VERSION ""

NS_ :

BS_:

BU_: L_3HKBD L_DIG L_FHPTC L_ATCU L_2HKBD L_PCM L_ATCU_vMON L_EVNT L_HKBD L_RHPTC

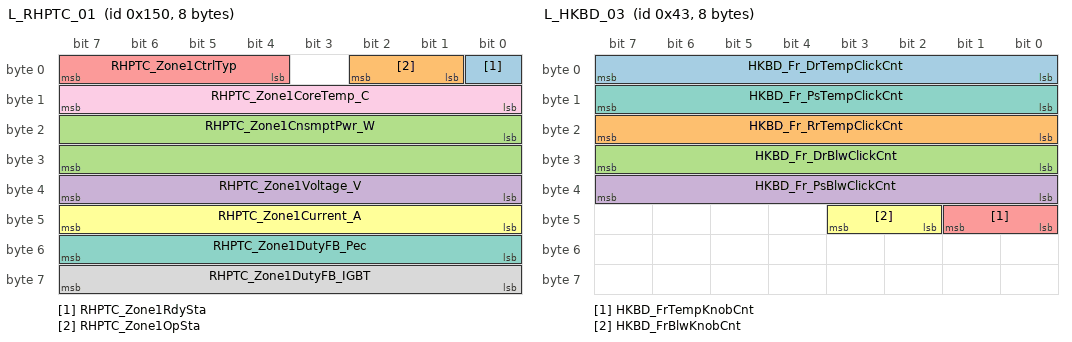
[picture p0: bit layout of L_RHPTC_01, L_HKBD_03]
BO_ 336 L_RHPTC_01: 8 L_RHPTC
 SG_ RHPTC_Zone1RdySta : 0|1@1+ (1,0) [0|0] ""  L_ATCU
 SG_ RHPTC_Zone1OpSta : 1|2@1+ (1,0) [0|0] ""  L_ATCU
 SG_ RHPTC_Zone1CnsmptPwr_W : 16|16@1+ (1,0) [0|10000] "W"  L_ATCU
 SG_ RHPTC_Zone1Voltage_V : 32|8@1+ (4,0) [0|1000] "V"  L_ATCU
 SG_ RHPTC_Zone1CtrlTyp : 4|4@1+ (1,0) [0|0] ""  L_ATCU
 SG_ RHPTC_Zone1Current_A : 40|8@1+ (0.2,0) [0|50] "A"  L_ATCU
 SG_ RHPTC_Zone1DutyFB_Pec : 48|8@1+ (0.5,0) [0|100] "%"  L_ATCU
 SG_ RHPTC_Zone1DutyFB_IGBT : 56|8@1+ (0.5,0) [0|100] "%"  L_ATCU
 SG_ RHPTC_Zone1CoreTemp_C : 8|8@1+ (1,-40) [-40|200] "¡É"  L_ATCU

BO_ 67 L_HKBD_03: 8 L_HKBD
 SG_ HKBD_Fr_DrTempClickCnt : 0|8@1+ (1,0) [0|0] ""  L_ATCU
 SG_ HKBD_Fr_RrTempClickCnt : 16|8@1+ (1,0) [0|0] ""  L_ATCU
 SG_ HKBD_Fr_DrBlwClickCnt : 24|8@1+ (1,0) [0|0] ""  L_ATCU
 SG_ HKBD_Fr_PsBlwClickCnt : 32|8@1+ (1,0) [0|0] ""  L_ATCU
 SG_ HKBD_FrTempKnobCnt : 40|2@1+ (1,0) [0|0] ""  L_ATCU
 SG_ HKBD_FrBlwKnobCnt : 42|2@1+ (1,0) [0|0] ""  L_ATCU
 SG_ HKBD_Fr_PsTempClickCnt : 8|8@1+ (1,0) [0|0] ""  L_ATCU

BO_ 886 L_ATCU_Lib_38: 8 L_ATCU
 SG_ L_ATCU_Lib_MEM_ROMWriteCnt : 0|32@1+ (1,0) [0|0] ""  L_ATCU_vMON

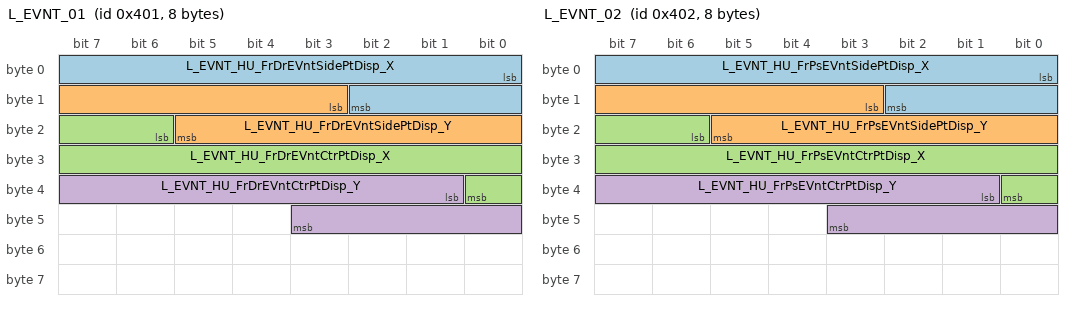
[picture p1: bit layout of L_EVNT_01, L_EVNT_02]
BO_ 1025 L_EVNT_01: 8 L_EVNT
 SG_ L_EVNT_HU_FrDrEVntSidePtDisp_X : 0|11@1+ (1,0) [0|0] ""  L_ATCU
 SG_ L_EVNT_HU_FrDrEVntSidePtDisp_Y : 11|11@1+ (1,0) [0|0] ""  L_ATCU
 SG_ L_EVNT_HU_FrDrEVntCtrPtDisp_X : 22|11@1+ (1,0) [0|0] ""  L_ATCU
 SG_ L_EVNT_HU_FrDrEVntCtrPtDisp_Y : 33|11@1+ (1,0) [0|0] ""  L_ATCU

BO_ 1026 L_EVNT_02: 8 L_EVNT
 SG_ L_EVNT_HU_FrPsEVntSidePtDisp_X : 0|11@1+ (1,0) [0|0] ""  L_ATCU
 SG_ L_EVNT_HU_FrPsEVntSidePtDisp_Y : 11|11@1+ (1,0) [0|0] ""  L_ATCU
 SG_ L_EVNT_HU_FrPsEVntCtrPtDisp_X : 22|11@1+ (1,0) [0|0] ""  L_ATCU
 SG_ L_EVNT_HU_FrPsEVntCtrPtDisp_Y : 33|11@1+ (1,0) [0|0] ""  L_ATCU

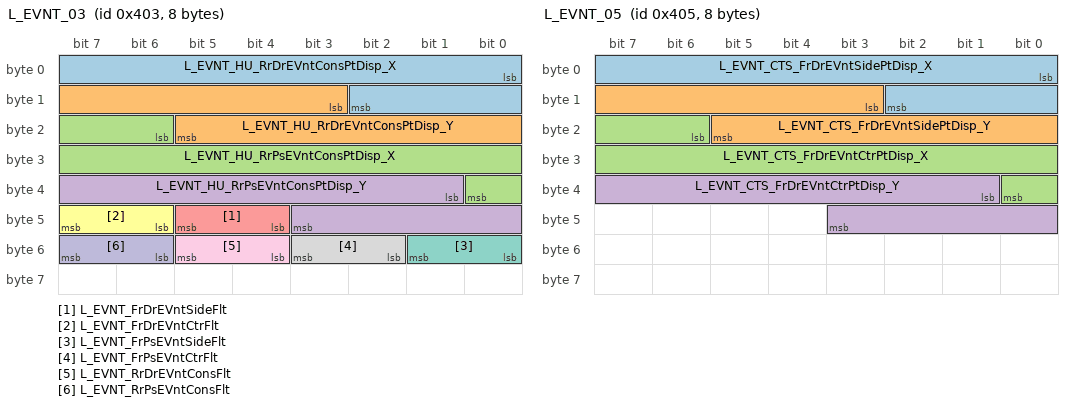
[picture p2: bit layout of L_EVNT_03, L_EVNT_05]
BO_ 1027 L_EVNT_03: 8 L_EVNT
 SG_ L_EVNT_HU_RrDrEVntConsPtDisp_X : 0|11@1+ (1,0) [0|0] ""  L_ATCU
 SG_ L_EVNT_HU_RrDrEVntConsPtDisp_Y : 11|11@1+ (1,0) [0|0] ""  L_ATCU
 SG_ L_EVNT_HU_RrPsEVntConsPtDisp_X : 22|11@1+ (1,0) [0|0] ""  L_ATCU
 SG_ L_EVNT_HU_RrPsEVntConsPtDisp_Y : 33|11@1+ (1,0) [0|0] ""  L_ATCU
 SG_ L_EVNT_FrDrEVntSideFlt : 44|2@1+ (1,0) [0|0] ""  L_ATCU
 SG_ L_EVNT_FrDrEVntCtrFlt : 46|2@1+ (1,0) [0|0] ""  L_ATCU
 SG_ L_EVNT_FrPsEVntSideFlt : 48|2@1+ (1,0) [0|0] ""  L_ATCU
 SG_ L_EVNT_FrPsEVntCtrFlt : 50|2@1+ (1,0) [0|0] ""  L_ATCU
 SG_ L_EVNT_RrDrEVntConsFlt : 52|2@1+ (1,0) [0|0] ""  L_ATCU
 SG_ L_EVNT_RrPsEVntConsFlt : 54|2@1+ (1,0) [0|0] ""  L_ATCU

BO_ 72 L_HKBD_08: 8 L_HKBD
 SG_ HKBD_Fr_IncarRaw : 0|10@1+ (0.01,0) [0|0] "V"  L_ATCU

BO_ 1028 L_EVNT_04: 8 L_EVNT
 SG_ L_EVNT_FrDrEVntModeSet_Disp : 0|4@1+ (1,0) [0|0] ""  L_ATCU
 SG_ L_EVNT_RrPsEVntModeSet_Disp : 12|4@1+ (1,0) [0|0] ""  L_ATCU
 SG_ L_EVNT_FrDrEVntSideOpnClsDisp : 16|2@1+ (1,0) [0|0] ""  L_ATCU
 SG_ L_EVNT_FrDrEVntCtrOpnClsDisp : 18|2@1+ (1,0) [0|0] ""  L_ATCU
 SG_ L_EVNT_FrPsEVntSideOpnClsDisp : 20|2@1+ (1,0) [0|0] ""  L_ATCU
 SG_ L_EVNT_FrPsEVntCtrOpnClsDisp : 22|2@1+ (1,0) [0|0] ""  L_ATCU
 SG_ L_EVNT_RrDrEVntConsOpnClsDisp : 24|2@1+ (1,0) [0|0] ""  L_ATCU
 SG_ L_EVNT_RrPsEVntConsOpnClsDisp : 26|2@1+ (1,0) [0|0] ""  L_ATCU
 SG_ L_EVNT_EVntTouchInform_HU : 28|2@1+ (1,0) [0|0] ""  L_ATCU
 SG_ L_EVNT_EVntTouchInform_CTS : 30|2@1+ (1,0) [0|0] ""  L_ATCU
 SG_ L_EVNT_FrtEvntFocusLvlSta : 32|3@1+ (1,0) [0|0] ""  L_ATCU
 SG_ L_EVNT_RrEvntFocusLvlSta : 35|3@1+ (1,0) [0|0] ""  L_ATCU
 SG_ L_EVNT_DrVntOpt : 38|2@1+ (1,0) [0|0] ""  L_ATCU
 SG_ L_EVNT_FrPsEVntModeSet_Disp : 4|4@1+ (1,0) [0|0] ""  L_ATCU
 SG_ L_EVNT_AstVntOpt : 40|2@1+ (1,0) [0|0] ""  L_ATCU
 SG_ L_EVNT_RrDrVntOpt : 42|2@1+ (1,0) [0|0] ""  L_ATCU
 SG_ L_EVNT_RrAstVntOpt : 44|2@1+ (1,0) [0|0] ""  L_ATCU
 SG_ L_EVNT_EVntAutoFlowHardSwOpt : 46|2@1+ (1,0) [0|0] ""  L_ATCU
 SG_ L_EVNT_RrDrEVntModeSet_Disp : 8|4@1+ (1,0) [0|0] ""  L_ATCU

BO_ 1029 L_EVNT_05: 8 L_EVNT
 SG_ L_EVNT_CTS_FrDrEVntSidePtDisp_X : 0|11@1+ (1,0) [0|0] ""  L_ATCU
 SG_ L_EVNT_CTS_FrDrEVntSidePtDisp_Y : 11|11@1+ (1,0) [0|0] ""  L_ATCU
 SG_ L_EVNT_CTS_FrDrEVntCtrPtDisp_X : 22|11@1+ (1,0) [0|0] ""  L_ATCU
 SG_ L_EVNT_CTS_FrDrEVntCtrPtDisp_Y : 33|11@1+ (1,0) [0|0] ""  L_ATCU

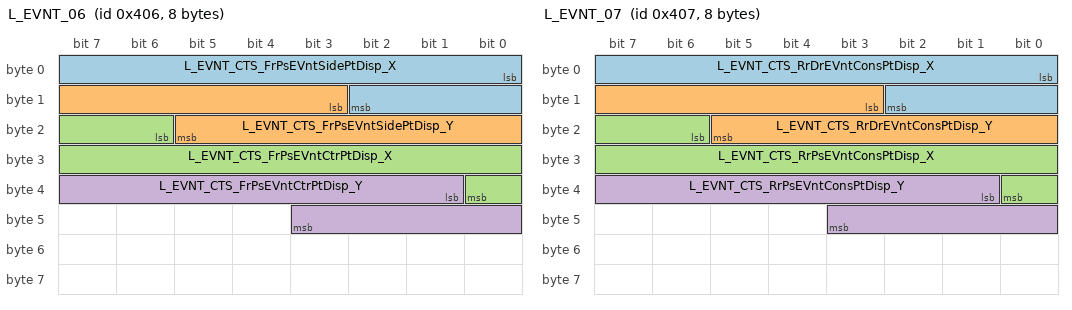
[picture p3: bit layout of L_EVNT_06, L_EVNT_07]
BO_ 1030 L_EVNT_06: 8 L_EVNT
 SG_ L_EVNT_CTS_FrPsEVntSidePtDisp_X : 0|11@1+ (1,0) [0|0] ""  L_ATCU
 SG_ L_EVNT_CTS_FrPsEVntSidePtDisp_Y : 11|11@1+ (1,0) [0|0] ""  L_ATCU
 SG_ L_EVNT_CTS_FrPsEVntCtrPtDisp_X : 22|11@1+ (1,0) [0|0] ""  L_ATCU
 SG_ L_EVNT_CTS_FrPsEVntCtrPtDisp_Y : 33|11@1+ (1,0) [0|0] ""  L_ATCU

BO_ 1031 L_EVNT_07: 8 L_EVNT
 SG_ L_EVNT_CTS_RrDrEVntConsPtDisp_X : 0|11@1+ (1,0) [0|0] ""  L_ATCU
 SG_ L_EVNT_CTS_RrDrEVntConsPtDisp_Y : 11|11@1+ (1,0) [0|0] ""  L_ATCU
 SG_ L_EVNT_CTS_RrPsEVntConsPtDisp_X : 22|11@1+ (1,0) [0|0] ""  L_ATCU
 SG_ L_EVNT_CTS_RrPsEVntConsPtDisp_Y : 33|11@1+ (1,0) [0|0] ""  L_ATCU

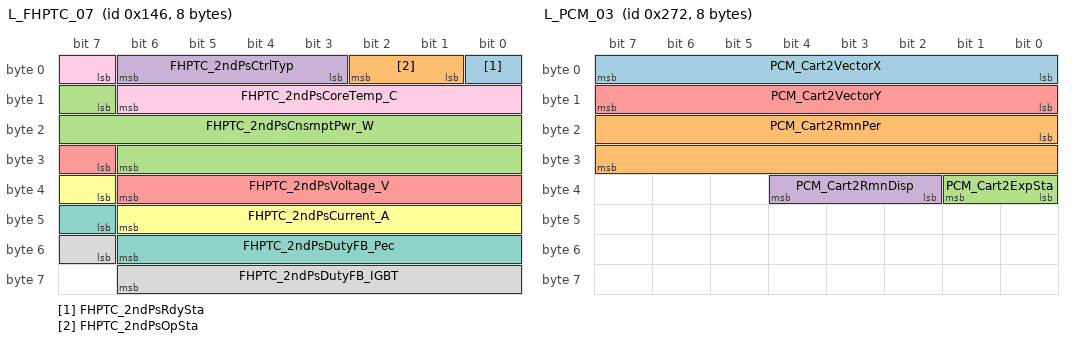
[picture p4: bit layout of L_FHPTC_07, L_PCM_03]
BO_ 326 L_FHPTC_07: 8 L_FHPTC
 SG_ FHPTC_2ndPsRdySta : 0|1@1+ (1,0) [0|0] ""  L_ATCU
 SG_ FHPTC_2ndPsOpSta : 1|2@1+ (1,0) [0|0] ""  L_ATCU
 SG_ FHPTC_2ndPsCnsmptPwr_W : 15|16@1+ (1,0) [0|10000] "W"  L_ATCU
 SG_ FHPTC_2ndPsCtrlTyp : 3|4@1+ (1,0) [0|0] ""  L_ATCU
 SG_ FHPTC_2ndPsVoltage_V : 31|8@1+ (4,0) [0|1000] "V"  L_ATCU
 SG_ FHPTC_2ndPsCurrent_A : 39|8@1+ (0.2,0) [0|50] "A"  L_ATCU
 SG_ FHPTC_2ndPsDutyFB_Pec : 47|8@1+ (0.5,0) [0|100] "%"  L_ATCU
 SG_ FHPTC_2ndPsDutyFB_IGBT : 55|8@1+ (0.5,0) [0|100] "%"  L_ATCU
 SG_ FHPTC_2ndPsCoreTemp_C : 7|8@1+ (1,-40) [-40|200] "¡É"  L_ATCU

BO_ 864 L_ATCU_Lib_16: 8 L_ATCU
 SG_ L_ATCU_Lib_MngrDEFBuf0 : 0|3@1+ (1,0) [0|7] ""  L_ATCU_vMON
 SG_ L_ATCU_Lib_MngrACBuf0 : 11|4@1+ (1,0) [0|15] ""  L_ATCU_vMON
 SG_ L_ATCU_Lib_MngrACBuf1 : 16|4@1+ (1,0) [0|15] ""  L_ATCU_vMON
 SG_ L_ATCU_Lib_MngrACBuf2 : 20|4@1+ (1,0) [0|15] ""  L_ATCU_vMON
 SG_ L_ATCU_Lib_MngrACBuf3 : 24|4@1+ (1,0) [0|15] ""  L_ATCU_vMON
 SG_ L_ATCU_Lib_MngrACBuf4 : 28|4@1+ (1,0) [0|15] ""  L_ATCU_vMON
 SG_ L_ATCU_Lib_MngrDEFBuf1 : 3|3@1+ (1,0) [0|7] ""  L_ATCU_vMON
 SG_ L_ATCU_Lib_MngrACBuf5 : 32|4@1+ (1,0) [0|15] ""  L_ATCU_vMON
 SG_ L_ATCU_Lib_MngrACBuf6 : 36|4@1+ (1,0) [0|15] ""  L_ATCU_vMON
 SG_ L_ATCU_Lib_MngrACBuf7 : 40|4@1+ (1,0) [0|15] ""  L_ATCU_vMON
 SG_ L_ATCU_Lib_MngrDEFBufLow1 : 44|2@1+ (1,0) [0|3] ""  L_ATCU_vMON
 SG_ L_ATCU_Lib_MngrTempBufLow1 : 48|2@1+ (1,0) [0|3] ""  L_ATCU_vMON
 SG_ L_ATCU_Lib_MngrTempBufLow0 : 50|2@1+ (1,0) [0|3] ""  L_ATCU_vMON
 SG_ L_ATCU_Lib_MngrIntakeBufHi0 : 52|2@1+ (1,0) [0|3] ""  L_ATCU_vMON
 SG_ L_ATCU_Lib_MngrIntakeBufHi1 : 54|2@1+ (1,0) [0|3] ""  L_ATCU_vMON
 SG_ L_ATCU_Lib_MngrIntakeBufLow2 : 56|2@1+ (1,0) [0|3] ""  L_ATCU_vMON
 SG_ L_ATCU_Lib_MngrDEFBufLow0 : 6|2@1+ (1,0) [0|3] ""  L_ATCU_vMON
 SG_ L_ATCU_Lib_MngrDEFBuf2 : 8|3@1+ (1,0) [0|7] ""  L_ATCU_vMON

BO_ 626 L_PCM_03: 8 L_PCM
 SG_ PCM_Cart2VectorX : 0|8@1+ (1,0) [0|0] ""  L_ATCU
 SG_ PCM_Cart2RmnPer : 16|16@1+ (0.01,0) [0|0] "%"  L_ATCU
 SG_ PCM_Cart2ExpSta : 32|2@1+ (1,0) [0|0] ""  L_ATCU
 SG_ PCM_Cart2RmnDisp : 34|3@1+ (1,0) [0|0] ""  L_ATCU
 SG_ PCM_Cart2VectorY : 8|8@1+ (1,0) [0|0] ""  L_ATCU

BO_ 327 L_FHPTC_08: 8 L_FHPTC
 SG_ FHPTC_2ndPsFlt : 0|1@1+ (1,0) [0|0] ""  L_ATCU
 SG_ FHPTC_2ndPsFltLVLow : 1|1@1+ (1,0) [0|0] ""  L_ATCU
 SG_ FHPTC_2ndPsFailLVSnr : 10|1@1+ (1,0) [0|0] ""  L_ATCU
 SG_ FHPTC_2ndPsFailCurrentSnr : 11|1@1+ (1,0) [0|0] ""  L_ATCU
 SG_ FHPTC_2ndPsFailCoreTempSnr : 12|1@1+ (1,0) [0|0] ""  L_ATCU
 SG_ FHPTC_2ndPsFailPcbTempSnr : 13|1@1+ (1,0) [0|0] ""  L_ATCU
 SG_ FHPTC_2ndPsFailIGBT : 14|1@1+ (1,0) [0|0] ""  L_ATCU
 SG_ FHPTC_2ndPsFailOpenLoad : 15|1@1+ (1,0) [0|0] ""  L_ATCU
 SG_ FHPTC_2ndPsLtdOpCause : 16|8@1+ (1,0) [0|0] ""  L_ATCU
 SG_ FHPTC_2ndPsFltLVHigh : 2|1@1+ (1,0) [0|0] ""  L_ATCU
 SG_ FHPTC_2ndPsSwVer : 24|8@1+ (1,0) [0|255] ""  L_ATCU
 SG_ FHPTC_2ndPsFltHVLow : 3|1@1+ (1,0) [0|0] ""  L_ATCU
 SG_ FHPTC_2ndPsFltHVHigh : 4|1@1+ (1,0) [0|0] ""  L_ATCU
 SG_ FHPTC_2ndPsFltOverCurrent : 5|1@1+ (1,0) [0|0] ""  L_ATCU
 SG_ FHPTC_2ndPsFltThermalShutDn : 6|1@1+ (1,0) [0|0] ""  L_ATCU
 SG_ FHPTC_2ndPsFltPcbThermalShutDn : 7|1@1+ (1,0) [0|0] ""  L_ATCU
 SG_ FHPTC_2ndPsFltMsgTmOutATCU : 8|1@1+ (1,0) [0|0] ""  L_ATCU
 SG_ FHPTC_2ndPsFailHVSnr : 9|1@1+ (1,0) [0|0] ""  L_ATCU

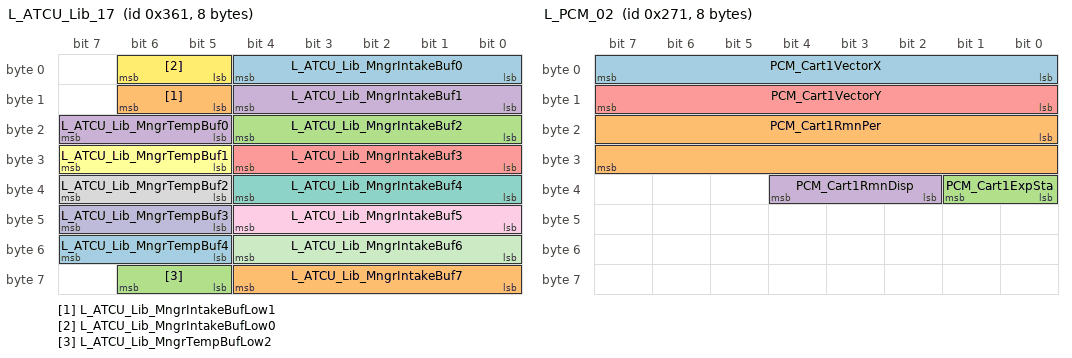
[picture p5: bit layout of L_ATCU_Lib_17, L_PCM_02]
BO_ 865 L_ATCU_Lib_17: 8 L_ATCU
 SG_ L_ATCU_Lib_MngrIntakeBuf0 : 0|5@1+ (1,0) [0|31] ""  L_ATCU_vMON
 SG_ L_ATCU_Lib_MngrIntakeBufLow1 : 13|2@1+ (1,0) [0|3] ""  L_ATCU_vMON
 SG_ L_ATCU_Lib_MngrIntakeBuf2 : 16|5@1+ (1,0) [0|31] ""  L_ATCU_vMON
 SG_ L_ATCU_Lib_MngrTempBuf0 : 21|3@1+ (1,0) [0|7] ""  L_ATCU_vMON
 SG_ L_ATCU_Lib_MngrIntakeBuf3 : 24|5@1+ (1,0) [0|31] ""  L_ATCU_vMON
 SG_ L_ATCU_Lib_MngrTempBuf1 : 29|3@1+ (1,0) [0|7] ""  L_ATCU_vMON
 SG_ L_ATCU_Lib_MngrIntakeBuf4 : 32|5@1+ (1,0) [0|31] ""  L_ATCU_vMON
 SG_ L_ATCU_Lib_MngrTempBuf2 : 37|3@1+ (1,0) [0|7] ""  L_ATCU_vMON
 SG_ L_ATCU_Lib_MngrIntakeBuf5 : 40|5@1+ (1,0) [0|31] ""  L_ATCU_vMON
 SG_ L_ATCU_Lib_MngrTempBuf3 : 45|3@1+ (1,0) [0|7] ""  L_ATCU_vMON
 SG_ L_ATCU_Lib_MngrIntakeBuf6 : 48|5@1+ (1,0) [0|31] ""  L_ATCU_vMON
 SG_ L_ATCU_Lib_MngrIntakeBufLow0 : 5|2@1+ (1,0) [0|3] ""  L_ATCU_vMON
 SG_ L_ATCU_Lib_MngrTempBuf4 : 53|3@1+ (1,0) [0|7] ""  L_ATCU_vMON
 SG_ L_ATCU_Lib_MngrIntakeBuf7 : 56|5@1+ (1,0) [0|31] ""  L_ATCU_vMON
 SG_ L_ATCU_Lib_MngrTempBufLow2 : 61|2@1+ (1,0) [0|3] ""  L_ATCU_vMON
 SG_ L_ATCU_Lib_MngrIntakeBuf1 : 8|5@1+ (1,0) [0|31] ""  L_ATCU_vMON

BO_ 625 L_PCM_02: 8 L_PCM
 SG_ PCM_Cart1VectorX : 0|8@1+ (1,0) [0|0] ""  L_ATCU
 SG_ PCM_Cart1RmnPer : 16|16@1+ (0.01,0) [0|0] "%"  L_ATCU
 SG_ PCM_Cart1ExpSta : 32|2@1+ (1,0) [0|0] ""  L_ATCU
 SG_ PCM_Cart1RmnDisp : 34|3@1+ (1,0) [0|0] ""  L_ATCU
 SG_ PCM_Cart1VectorY : 8|8@1+ (1,0) [0|0] ""  L_ATCU

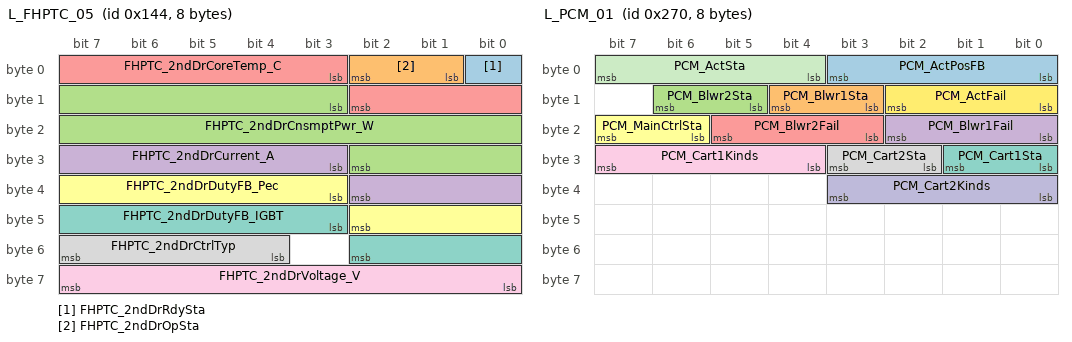
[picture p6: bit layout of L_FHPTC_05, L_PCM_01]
BO_ 324 L_FHPTC_05: 8 L_FHPTC
 SG_ FHPTC_2ndDrRdySta : 0|1@1+ (1,0) [0|0] ""  L_ATCU
 SG_ FHPTC_2ndDrOpSta : 1|2@1+ (1,0) [0|0] ""  L_ATCU
 SG_ FHPTC_2ndDrCnsmptPwr_W : 11|16@1+ (1,0) [0|10000] "W"  L_ATCU
 SG_ FHPTC_2ndDrCurrent_A : 27|8@1+ (0.2,0) [0|50] "A"  L_ATCU
 SG_ FHPTC_2ndDrCoreTemp_C : 3|8@1+ (1,-40) [-40|200] "¡É"  L_ATCU
 SG_ FHPTC_2ndDrDutyFB_Pec : 35|8@1+ (0.5,0) [0|100] "%"  L_ATCU
 SG_ FHPTC_2ndDrDutyFB_IGBT : 43|8@1+ (0.5,0) [0|100] "%"  L_ATCU
 SG_ FHPTC_2ndDrCtrlTyp : 52|4@1+ (1,0) [0|0] ""  L_ATCU
 SG_ FHPTC_2ndDrVoltage_V : 56|8@1+ (4,0) [0|1000] "V"  L_ATCU

BO_ 866 L_ATCU_Lib_18: 8 L_ATCU
 SG_ L_ATCU_Lib_2LHMngrModBuf0 : 0|4@1+ (1,0) [0|15] ""  L_ATCU_vMON
 SG_ L_ATCU_Lib_2LHMngrModBuf3 : 12|4@1+ (1,0) [0|15] ""  L_ATCU_vMON
 SG_ L_ATCU_Lib_2LHMngrModBuf4 : 16|4@1+ (1,0) [0|15] ""  L_ATCU_vMON
 SG_ L_ATCU_Lib_2LHMngrModBuf5 : 20|4@1+ (1,0) [0|15] ""  L_ATCU_vMON
 SG_ L_ATCU_Lib_2LHMngrModBuf6 : 24|4@1+ (1,0) [0|15] ""  L_ATCU_vMON
 SG_ L_ATCU_Lib_2LHMngrModBuf7 : 28|4@1+ (1,0) [0|15] ""  L_ATCU_vMON
 SG_ L_ATCU_Lib_2LHMngrBlwBuf0 : 32|4@1+ (1,0) [0|15] ""  L_ATCU_vMON
 SG_ L_ATCU_Lib_2LHMngrBlwBuf1 : 36|4@1+ (1,0) [0|15] ""  L_ATCU_vMON
 SG_ L_ATCU_Lib_2LHMngrModBuf1 : 4|4@1+ (1,0) [0|15] ""  L_ATCU_vMON
 SG_ L_ATCU_Lib_2LHMngrBlwBuf2 : 40|4@1+ (1,0) [0|15] ""  L_ATCU_vMON
 SG_ L_ATCU_Lib_2LHMngrBlwBuf3 : 44|4@1+ (1,0) [0|15] ""  L_ATCU_vMON
 SG_ L_ATCU_Lib_2LHMngrBlwBuf4 : 48|4@1+ (1,0) [0|15] ""  L_ATCU_vMON
 SG_ L_ATCU_Lib_2LHMngrBlwBuf5 : 52|4@1+ (1,0) [0|15] ""  L_ATCU_vMON
 SG_ L_ATCU_Lib_2LHMngrBlwBuf6 : 56|4@1+ (1,0) [0|15] ""  L_ATCU_vMON
 SG_ L_ATCU_Lib_2LHMngrBlwBufHi0 : 60|2@1+ (1,0) [0|3] ""  L_ATCU_vMON
 SG_ L_ATCU_Lib_2LHMngrBlwBufHi1 : 62|2@1+ (1,0) [0|3] ""  L_ATCU_vMON
 SG_ L_ATCU_Lib_2LHMngrModBuf2 : 8|4@1+ (1,0) [0|15] ""  L_ATCU_vMON

BO_ 624 L_PCM_01: 8 L_PCM
 SG_ PCM_ActPosFB : 0|4@1+ (1,0) [0|0] ""  L_ATCU
 SG_ PCM_Blwr1Sta : 11|2@1+ (1,0) [0|0] ""  L_ATCU
 SG_ PCM_Blwr2Sta : 13|2@1+ (1,0) [0|0] ""  L_ATCU
 SG_ PCM_Blwr1Fail : 16|3@1+ (1,0) [0|0] ""  L_ATCU
 SG_ PCM_Blwr2Fail : 19|3@1+ (1,0) [0|0] ""  L_ATCU
 SG_ PCM_MainCtrlSta : 22|2@1+ (1,0) [0|0] ""  L_ATCU
 SG_ PCM_Cart1Sta : 24|2@1+ (1,0) [0|0] ""  L_ATCU
 SG_ PCM_Cart2Sta : 26|2@1+ (1,0) [0|0] ""  L_ATCU
 SG_ PCM_Cart1Kinds : 28|4@1+ (1,0) [0|0] ""  L_ATCU
 SG_ PCM_Cart2Kinds : 32|4@1+ (1,0) [0|0] ""  L_ATCU
 SG_ PCM_ActSta : 4|4@1+ (1,0) [0|0] ""  L_ATCU
 SG_ PCM_ActFail : 8|3@1+ (1,0) [0|0] ""  L_ATCU

BO_ 325 L_FHPTC_06: 8 L_FHPTC
 SG_ FHPTC_2ndDrFlt : 0|1@1+ (1,0) [0|0] ""  L_ATCU
 SG_ FHPTC_2ndDrFltLVLow : 1|1@1+ (1,0) [0|0] ""  L_ATCU
 SG_ FHPTC_2ndDrFailLVSnr : 10|1@1+ (1,0) [0|0] ""  L_ATCU
 SG_ FHPTC_2ndDrFailCurrentSnr : 11|1@1+ (1,0) [0|0] ""  L_ATCU
 SG_ FHPTC_2ndDrFailCoreTempSnr : 12|1@1+ (1,0) [0|0] ""  L_ATCU
 SG_ FHPTC_2ndDrFailPcbTempSnr : 13|1@1+ (1,0) [0|0] ""  L_ATCU
 SG_ FHPTC_2ndDrFailIGBT : 14|1@1+ (1,0) [0|0] ""  L_ATCU
 SG_ FHPTC_2ndDrFailOpenLoad : 15|1@1+ (1,0) [0|0] ""  L_ATCU
 SG_ FHPTC_2ndDrLtdOpCause : 16|8@1+ (1,0) [0|0] ""  L_ATCU
 SG_ FHPTC_2ndDrFltLVHigh : 2|1@1+ (1,0) [0|0] ""  L_ATCU
 SG_ FHPTC_2ndDrSwVer : 24|8@1+ (1,0) [0|0] ""  L_ATCU
 SG_ FHPTC_2ndDrFltHVLow : 3|1@1+ (1,0) [0|0] ""  L_ATCU
 SG_ FHPTC_2ndDrFltHVHigh : 4|1@1+ (1,0) [0|0] ""  L_ATCU
 SG_ FHPTC_2ndDrFltOverCurrent : 5|1@1+ (1,0) [0|0] ""  L_ATCU
 SG_ FHPTC_2ndDrFltThermalShutDn : 6|1@1+ (1,0) [0|0] ""  L_ATCU
 SG_ FHPTC_2ndDrFltPcbThermalShutDn : 7|1@1+ (1,0) [0|0] ""  L_ATCU
 SG_ FHPTC_2ndDrFltMsgTmOutATCU : 8|1@1+ (1,0) [0|0] ""  L_ATCU
 SG_ FHPTC_2ndDrFailHVSnr : 9|1@1+ (1,0) [0|0] ""  L_ATCU

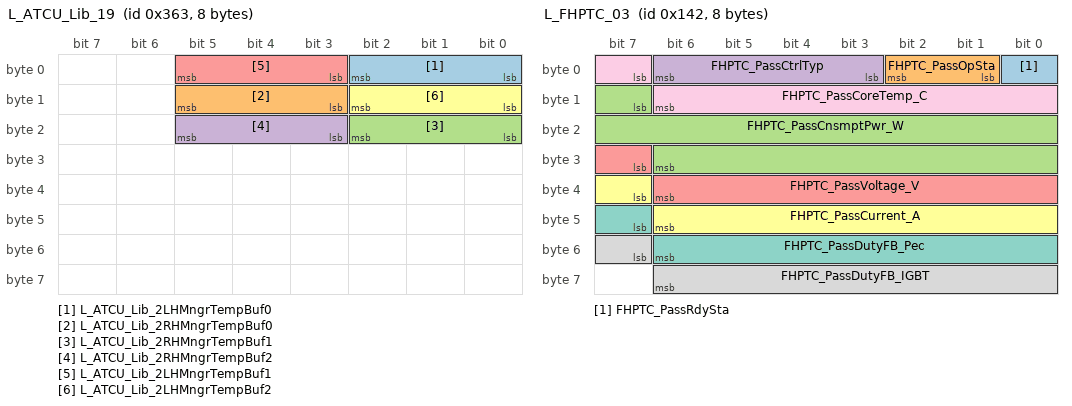
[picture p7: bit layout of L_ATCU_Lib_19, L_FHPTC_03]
BO_ 867 L_ATCU_Lib_19: 8 L_ATCU
 SG_ L_ATCU_Lib_2LHMngrTempBuf0 : 0|3@1+ (1,0) [0|7] ""  L_ATCU_vMON
 SG_ L_ATCU_Lib_2RHMngrTempBuf0 : 11|3@1+ (1,0) [0|7] ""  L_ATCU_vMON
 SG_ L_ATCU_Lib_2RHMngrTempBuf1 : 16|3@1+ (1,0) [0|7] ""  L_ATCU_vMON
 SG_ L_ATCU_Lib_2RHMngrTempBuf2 : 19|3@1+ (1,0) [0|7] ""  L_ATCU_vMON
 SG_ L_ATCU_Lib_2LHMngrTempBuf1 : 3|3@1+ (1,0) [0|7] ""  L_ATCU_vMON
 SG_ L_ATCU_Lib_2LHMngrTempBuf2 : 8|3@1+ (1,0) [0|7] ""  L_ATCU_vMON

BO_ 322 L_FHPTC_03: 8 L_FHPTC
 SG_ FHPTC_PassRdySta : 0|1@1+ (1,0) [0|0] ""  L_ATCU
 SG_ FHPTC_PassOpSta : 1|2@1+ (1,0) [0|0] ""  L_ATCU
 SG_ FHPTC_PassCnsmptPwr_W : 15|16@1+ (1,0) [0|10000] "W"  L_ATCU
 SG_ FHPTC_PassCtrlTyp : 3|4@1+ (1,0) [0|0] ""  L_ATCU
 SG_ FHPTC_PassVoltage_V : 31|8@1+ (4,0) [0|1000] "V"  L_ATCU
 SG_ FHPTC_PassCurrent_A : 39|8@1+ (0.2,0) [0|50] "A"  L_ATCU
 SG_ FHPTC_PassDutyFB_Pec : 47|8@1+ (0.5,0) [0|100] "%"  L_ATCU
 SG_ FHPTC_PassDutyFB_IGBT : 55|8@1+ (0.5,0) [0|100] "%"  L_ATCU
 SG_ FHPTC_PassCoreTemp_C : 7|8@1+ (1,-40) [-40|200] "¡É"  L_ATCU

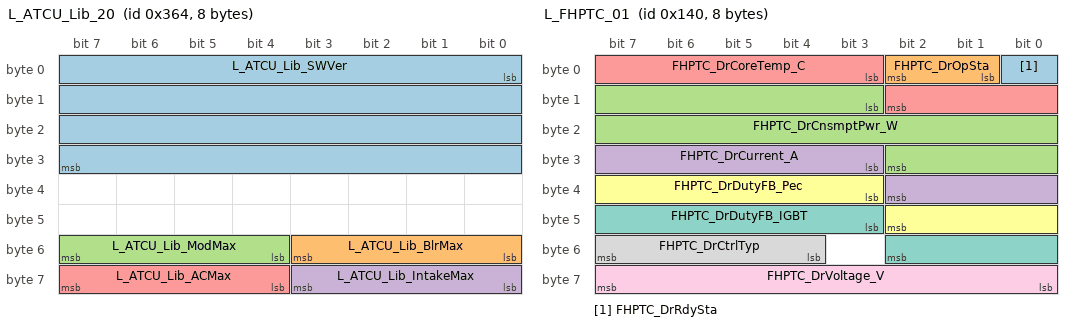
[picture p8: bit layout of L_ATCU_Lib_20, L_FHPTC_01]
BO_ 868 L_ATCU_Lib_20: 8 L_ATCU
 SG_ L_ATCU_Lib_SWVer : 0|32@1+ (1,0) [0|0] ""  L_ATCU_vMON
 SG_ L_ATCU_Lib_BlrMax : 48|4@1+ (1,0) [0|0] ""  L_ATCU_vMON
 SG_ L_ATCU_Lib_ModMax : 52|4@1+ (1,0) [0|0] ""  L_ATCU_vMON
 SG_ L_ATCU_Lib_IntakeMax : 56|4@1+ (1,0) [0|0] ""  L_ATCU_vMON
 SG_ L_ATCU_Lib_ACMax : 60|4@1+ (1,0) [0|0] ""  L_ATCU_vMON

BO_ 323 L_FHPTC_04: 8 L_FHPTC
 SG_ FHPTC_PassFlt : 0|1@1+ (1,0) [0|0] ""  L_ATCU
 SG_ FHPTC_PassFltLVLow : 1|1@1+ (1,0) [0|0] ""  L_ATCU
 SG_ FHPTC_PassFailLVSnr : 10|1@1+ (1,0) [0|0] ""  L_ATCU
 SG_ FHPTC_PassFailCurrentSnr : 11|1@1+ (1,0) [0|0] ""  L_ATCU
 SG_ FHPTC_PassFailCoreTempSnr : 12|1@1+ (1,0) [0|0] ""  L_ATCU
 SG_ FHPTC_PassFailPcbTempSnr : 13|1@1+ (1,0) [0|0] ""  L_ATCU
 SG_ FHPTC_PassFailIGBT : 14|1@1+ (1,0) [0|0] ""  L_ATCU
 SG_ FHPTC_PassFailOpenLoad : 15|1@1+ (1,0) [0|0] ""  L_ATCU
 SG_ FHPTC_PassLtdOpCause : 16|8@1+ (1,0) [0|0] ""  L_ATCU
 SG_ FHPTC_PassFltLVHigh : 2|1@1+ (1,0) [0|0] ""  L_ATCU
 SG_ FHPTC_PassSwVer : 24|8@1+ (1,0) [0|255] ""  L_ATCU
 SG_ FHPTC_PassFltHVLow : 3|1@1+ (1,0) [0|0] ""  L_ATCU
 SG_ FHPTC_PassFltHVHigh : 4|1@1+ (1,0) [0|0] ""  L_ATCU
 SG_ FHPTC_PassFltOverCurrent : 5|1@1+ (1,0) [0|0] ""  L_ATCU
 SG_ FHPTC_PassFltThermalShutDn : 6|1@1+ (1,0) [0|0] ""  L_ATCU
 SG_ FHPTC_PassFltPcbThermalShutDn : 7|1@1+ (1,0) [0|0] ""  L_ATCU
 SG_ FHPTC_PassFltMsgTmOutATCU : 8|1@1+ (1,0) [0|0] ""  L_ATCU
 SG_ FHPTC_PassFailHVSnr : 9|1@1+ (1,0) [0|0] ""  L_ATCU

BO_ 869 L_ATCU_Lib_21: 8 L_ATCU
 SG_ L_ATCU_Lib_StatMngr_Humid : 0|64@1+ (1,0) [0|0] ""  L_ATCU_vMON

BO_ 320 L_FHPTC_01: 8 L_FHPTC
 SG_ FHPTC_DrRdySta : 0|1@1+ (1,0) [0|0] ""  L_ATCU
 SG_ FHPTC_DrOpSta : 1|2@1+ (1,0) [0|0] ""  L_ATCU
 SG_ FHPTC_DrCnsmptPwr_W : 11|16@1+ (1,0) [0|10000] "W"  L_ATCU
 SG_ FHPTC_DrCurrent_A : 27|8@1+ (0.2,0) [0|50] "A"  L_ATCU
 SG_ FHPTC_DrCoreTemp_C : 3|8@1+ (1,-40) [-40|200] "¡É"  L_ATCU
 SG_ FHPTC_DrDutyFB_Pec : 35|8@1+ (0.5,0) [0|100] "%"  L_ATCU
 SG_ FHPTC_DrDutyFB_IGBT : 43|8@1+ (0.5,0) [0|100] "%"  L_ATCU
 SG_ FHPTC_DrCtrlTyp : 52|4@1+ (1,0) [0|0] ""  L_ATCU
 SG_ FHPTC_DrVoltage_V : 56|8@1+ (4,0) [0|1000] "V"  L_ATCU

BO_ 870 L_ATCU_Lib_22: 8 L_ATCU
 SG_ L_ATCU_Lib_StatMngr_Temp : 0|64@1+ (1,0) [0|0] ""  L_ATCU_vMON

BO_ 321 L_FHPTC_02: 8 L_FHPTC
 SG_ FHPTC_DrFlt : 0|1@1+ (1,0) [0|0] ""  L_ATCU
 SG_ FHPTC_DrFltLVLow : 1|1@1+ (1,0) [0|0] ""  L_ATCU
 SG_ FHPTC_DrFailLVSnr : 10|1@1+ (1,0) [0|0] ""  L_ATCU
 SG_ FHPTC_DrFailCurrentSnr : 11|1@1+ (1,0) [0|0] ""  L_ATCU
 SG_ FHPTC_DrFailCoreTempSnr : 12|1@1+ (1,0) [0|0] ""  L_ATCU
 SG_ FHPTC_DrFailPcbTempSnr : 13|1@1+ (1,0) [0|0] ""  L_ATCU
 SG_ FHPTC_DrFailIGBT : 14|1@1+ (1,0) [0|0] ""  L_ATCU
 SG_ FHPTC_DrFailOpenLoad : 15|1@1+ (1,0) [0|0] ""  L_ATCU
 SG_ FHPTC_DrLtdOpCause : 16|8@1+ (1,0) [0|0] ""  L_ATCU
 SG_ FHPTC_DrFltLVHigh : 2|1@1+ (1,0) [0|0] ""  L_ATCU
 SG_ FHPTC_DrSwVer : 24|8@1+ (1,0) [0|0] ""  L_ATCU
 SG_ FHPTC_DrFltHVLow : 3|1@1+ (1,0) [0|0] ""  L_ATCU
 SG_ FHPTC_CnsmptPwrTtl_W : 32|16@1+ (1,0) [0|10000] "W"  L_ATCU
 SG_ FHPTC_DrFltHVHigh : 4|1@1+ (1,0) [0|0] ""  L_ATCU
 SG_ FHPTC_IntlkSta : 48|2@1+ (1,0) [0|0] ""  L_ATCU
 SG_ FHPTC_DrFltOverCurrent : 5|1@1+ (1,0) [0|0] ""  L_ATCU
 SG_ FHPTC_DrFltThermalShutDn : 6|1@1+ (1,0) [0|0] ""  L_ATCU
 SG_ FHPTC_DrFltPcbThermalShutDn : 7|1@1+ (1,0) [0|0] ""  L_ATCU
 SG_ FHPTC_DrFltMsgTmOutATCU : 8|1@1+ (1,0) [0|0] ""  L_ATCU
 SG_ FHPTC_DrFailHVSnr : 9|1@1+ (1,0) [0|0] ""  L_ATCU

BO_ 871 L_ATCU_Lib_23: 8 L_ATCU
 SG_ L_ATCU_Lib_StatMngr_SafetynCool : 0|64@1+ (1,0) [0|0] ""  L_ATCU_vMON

BO_ 872 L_ATCU_Lib_24: 8 L_ATCU
 SG_ L_ATCU_Lib_StatMngr_Mngr : 0|64@1+ (1,0) [0|0] ""  L_ATCU_vMON

BO_ 1040 L_EVNT_10: 8 L_EVNT
 SG_ L_EVNT_FrDrEVntAutoFlowOSDReq : 0|2@1+ (1,0) [0|0] ""  L_ATCU
 SG_ L_EVNT_FrAstEVntAutoFlowOSDReq : 2|2@1+ (1,0) [0|0] ""  L_ATCU

BO_ 873 L_ATCU_Lib_25: 8 L_ATCU
 SG_ L_ATCU_Lib_StatMngr_Convenience : 0|64@1+ (1,0) [0|0] ""  L_ATCU_vMON

BO_ 874 L_ATCU_Lib_26: 8 L_ATCU
 SG_ L_ATCU_Lib_StatMngr_AirQuality : 0|64@1+ (1,0) [0|0] ""  L_ATCU_vMON

BO_ 875 L_ATCU_Lib_27: 8 L_ATCU
 SG_ L_ATCU_Lib_StatMngr_ETC : 0|64@1+ (1,0) [0|0] ""  L_ATCU_vMON

BO_ 876 L_ATCU_Lib_28: 8 L_ATCU
 SG_ L_ATCU_Lib_StatMngr_FuelEfficiency : 0|64@1+ (1,0) [0|0] ""  L_ATCU_vMON

BO_ 877 L_ATCU_Lib_29: 8 L_ATCU
 SG_ L_ATCU_Lib_StatMngr_Snsr : 0|64@1+ (1,0) [0|0] ""  L_ATCU_vMON

BO_ 878 L_ATCU_Lib_30: 8 L_ATCU
 SG_ L_ATCU_Lib_StatMngr_2ndHumid : 0|64@1+ (1,0) [0|0] ""  L_ATCU_vMON

BO_ 879 L_ATCU_Lib_31: 8 L_ATCU
 SG_ L_ATCU_Lib_StatMngr_2ndTemp : 0|64@1+ (1,0) [0|0] ""  L_ATCU_vMON

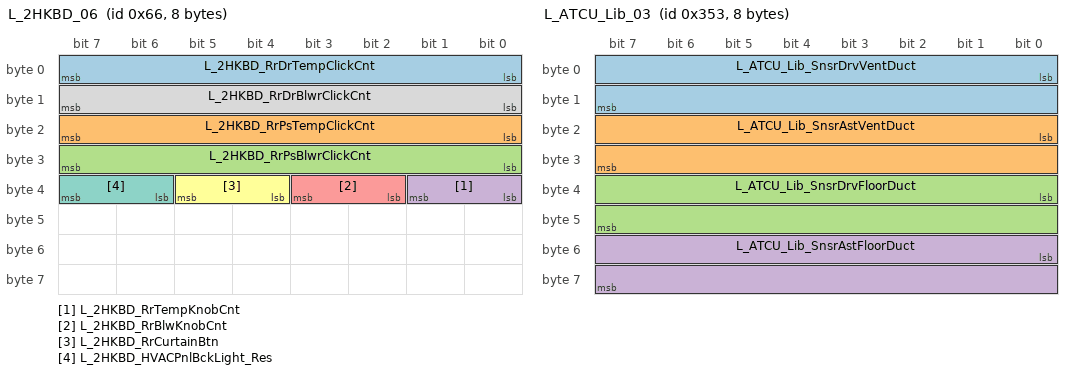
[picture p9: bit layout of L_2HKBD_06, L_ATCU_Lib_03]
BO_ 102 L_2HKBD_06: 8 L_2HKBD
 SG_ L_2HKBD_RrDrTempClickCnt : 0|8@1+ (1,0) [0|0] ""  L_ATCU
 SG_ L_2HKBD_RrPsTempClickCnt : 16|8@1+ (1,0) [0|0] ""  L_ATCU
 SG_ L_2HKBD_RrPsBlwrClickCnt : 24|8@1+ (1,0) [0|0] ""  L_ATCU
 SG_ L_2HKBD_RrTempKnobCnt : 32|2@1+ (1,0) [0|0] ""  L_ATCU
 SG_ L_2HKBD_RrBlwKnobCnt : 34|2@1+ (1,0) [0|0] ""  L_ATCU
 SG_ L_2HKBD_RrCurtainBtn : 36|2@1+ (1,0) [0|0] ""  L_ATCU
 SG_ L_2HKBD_HVACPnlBckLight_Res : 38|2@1+ (1,0) [0|0] ""  L_ATCU
 SG_ L_2HKBD_RrDrBlwrClickCnt : 8|8@1+ (1,0) [0|0] ""  L_ATCU

BO_ 851 L_ATCU_Lib_03: 8 L_ATCU
 SG_ L_ATCU_Lib_SnsrDrvVentDuct : 0|16@1+ (0.1,-40) [-40|120] "¡É"  L_ATCU_vMON
 SG_ L_ATCU_Lib_SnsrAstVentDuct : 16|16@1+ (0.1,-40) [-40|120] "¡É"  L_ATCU_vMON
 SG_ L_ATCU_Lib_SnsrDrvFloorDuct : 32|16@1+ (0.1,-40) [-40|120] "¡É"  L_ATCU_vMON
 SG_ L_ATCU_Lib_SnsrAstFloorDuct : 48|16@1+ (0.1,-40) [-40|120] "¡É"  L_ATCU_vMON

CM_ BO_ 102 "[EC] On Event and On Change";
CM_ SG_ 102 L_2HKBD_RrDrTempClickCnt "2HKBD_RearDriverTempClickCount";
CM_ SG_ 102 L_2HKBD_RrPsTempClickCnt "2HKBD_RearPassengerTempClickCount";
CM_ SG_ 102 L_2HKBD_RrPsBlwrClickCnt "2HKBD_RearPassengerBlowerClickCount";
CM_ SG_ 102 L_2HKBD_RrTempKnobCnt "2HKBD_RearTemperatureKnobCount (for knobs rotate count)";
CM_ SG_ 102 L_2HKBD_RrBlwKnobCnt "2HKBD_RearBlowerKnobCount (for knobs rotate count)";
CM_ SG_ 102 L_2HKBD_RrCurtainBtn "Rear Curtain Touch Button";
CM_ SG_ 102 L_2HKBD_HVACPnlBckLight_Res "Vehicle API HVAC Control Panel BackLight Response";
CM_ SG_ 102 L_2HKBD_RrDrBlwrClickCnt "2HKBD_RearDriverBlowerClickCount";
CM_ BO_ 851 "[PE] Periodic and On Event";
CM_ SG_ 851 L_ATCU_Lib_SnsrDrvVentDuct "ATCU Library Driver Vent Duct Temp Filtering Value";
CM_ SG_ 851 L_ATCU_Lib_SnsrAstVentDuct "ATCU Library Assist Vent Duct Temp Filtering Value";
CM_ SG_ 851 L_ATCU_Lib_SnsrDrvFloorDuct "ATCU Library Driver Floor Duct Temp Filtering Value";
CM_ SG_ 851 L_ATCU_Lib_SnsrAstFloorDuct "ATCU Library Assist Floor Duct Temp Filtering Value";
CM_ BO_ 864 "[PE] Periodic and On Event";
CM_ SG_ 864 L_ATCU_Lib_MngrDEFBuf0 "ATCU Library DEF Manager Buffer 0";
CM_ SG_ 864 L_ATCU_Lib_MngrACBuf0 "ATCU Library AC Manager Buffer 0";
CM_ SG_ 864 L_ATCU_Lib_MngrACBuf1 "ATCU Library AC Manager Buffer 1";
CM_ SG_ 864 L_ATCU_Lib_MngrACBuf2 "ATCU Library AC Manager Buffer 2";
CM_ SG_ 864 L_ATCU_Lib_MngrACBuf3 "ATCU Library AC Manager Buffer 3";
CM_ SG_ 864 L_ATCU_Lib_MngrACBuf4 "ATCU Library AC Manager Buffer 4";
CM_ SG_ 864 L_ATCU_Lib_MngrDEFBuf1 "ATCU Library DEF Manager Buffer 1";
CM_ SG_ 864 L_ATCU_Lib_MngrACBuf5 "ATCU Library AC Manager Buffer 5";
CM_ SG_ 864 L_ATCU_Lib_MngrACBuf6 "ATCU Library AC Manager Buffer 6";
CM_ SG_ 864 L_ATCU_Lib_MngrACBuf7 "ATCU Library AC Manager Buffer 7";
CM_ SG_ 864 L_ATCU_Lib_MngrDEFBufLow1 "ATCU Library DEF Manager Lower Limit Buffer 1";
CM_ SG_ 864 L_ATCU_Lib_MngrTempBufLow1 "ATCU Library Temp Manager Lower Limit Buffer 1";
CM_ SG_ 864 L_ATCU_Lib_MngrTempBufLow0 "ATCU Library Temp Manager Lower Limit Buffer 0";
CM_ SG_ 864 L_ATCU_Lib_MngrIntakeBufHi0 "ATCU Library Intake Manager Upper Limit Buffer 0";
CM_ SG_ 864 L_ATCU_Lib_MngrIntakeBufHi1 "ATCU Library Intake Manager Upper Limit Buffer 1";
CM_ SG_ 864 L_ATCU_Lib_MngrIntakeBufLow2 "ATCU Library Intake Manager Lower Limit Buffer 2";
CM_ SG_ 864 L_ATCU_Lib_MngrDEFBufLow0 "ATCU Library DEF Manager Lower Limit Buffer 0";
CM_ SG_ 864 L_ATCU_Lib_MngrDEFBuf2 "ATCU Library DEF Manager Buffer 2";
CM_ BO_ 865 "[PE] Periodic and On Event";
CM_ SG_ 865 L_ATCU_Lib_MngrIntakeBuf0 "ATCU Library Intake Manager Buffer 0";
CM_ SG_ 865 L_ATCU_Lib_MngrIntakeBufLow1 "ATCU Library Intake Manager Lower Limit Buffer 1";
CM_ SG_ 865 L_ATCU_Lib_MngrIntakeBuf2 "ATCU Library Intake Manager Buffer 2";
CM_ SG_ 865 L_ATCU_Lib_MngrTempBuf0 "ATCU Library Temp Manager Buffer 0";
CM_ SG_ 865 L_ATCU_Lib_MngrIntakeBuf3 "ATCU Library Intake Manager Buffer 3";
CM_ SG_ 865 L_ATCU_Lib_MngrTempBuf1 "ATCU Library Temp Manager Buffer 1";
CM_ SG_ 865 L_ATCU_Lib_MngrIntakeBuf4 "ATCU Library Intake Manager Buffer 4";
CM_ SG_ 865 L_ATCU_Lib_MngrTempBuf2 "ATCU Library Temp Manager Buffer 2";
CM_ SG_ 865 L_ATCU_Lib_MngrIntakeBuf5 "ATCU Library Intake Manager Buffer 5";
CM_ SG_ 865 L_ATCU_Lib_MngrTempBuf3 "ATCU Library Temp Manager Buffer 3";
CM_ SG_ 865 L_ATCU_Lib_MngrIntakeBuf6 "ATCU Library Intake Manager Buffer 6";
CM_ SG_ 865 L_ATCU_Lib_MngrIntakeBufLow0 "ATCU Library Intake Manager Lower Limit Buffer 0";
CM_ SG_ 865 L_ATCU_Lib_MngrTempBuf4 "ATCU Library Temp Manager Buffer 4";
CM_ SG_ 865 L_ATCU_Lib_MngrIntakeBuf7 "ATCU Library Intake Manager Buffer 7";
CM_ SG_ 865 L_ATCU_Lib_MngrTempBufLow2 "ATCU Library Temp Manager Lower Limit Buffer 2";
CM_ SG_ 865 L_ATCU_Lib_MngrIntakeBuf1 "ATCU Library Intake Manager Buffer 1";
CM_ BO_ 866 "[PE] Periodic and On Event";
CM_ SG_ 866 L_ATCU_Lib_2LHMngrModBuf0 "ATCU Library 2nd Leftside Mode Manager Buffer 0";
CM_ SG_ 866 L_ATCU_Lib_2LHMngrModBuf3 "ATCU Library 2nd Leftside Mode Manager Buffer 3";
CM_ SG_ 866 L_ATCU_Lib_2LHMngrModBuf4 "ATCU Library 2nd Leftside Mode Manager Buffer 4";
CM_ SG_ 866 L_ATCU_Lib_2LHMngrModBuf5 "ATCU Library 2nd Leftside Mode Manager Buffer 5";
CM_ SG_ 866 L_ATCU_Lib_2LHMngrModBuf6 "ATCU Library 2nd Leftside Mode Manager Buffer 6";
CM_ SG_ 866 L_ATCU_Lib_2LHMngrModBuf7 "ATCU Library 2nd Leftside Mode Manager Buffer 7";
CM_ SG_ 866 L_ATCU_Lib_2LHMngrBlwBuf0 "ATCU Library 2nd Leftside Blower Manager Buffer 0";
CM_ SG_ 866 L_ATCU_Lib_2LHMngrBlwBuf1 "ATCU Library 2nd Leftside Blower Manager Buffer 1";
CM_ SG_ 866 L_ATCU_Lib_2LHMngrModBuf1 "ATCU Library 2nd Leftside Mode Manager Buffer 1";
CM_ SG_ 866 L_ATCU_Lib_2LHMngrBlwBuf2 "ATCU Library 2nd Leftside Blower Manager Buffer 2";
CM_ SG_ 866 L_ATCU_Lib_2LHMngrBlwBuf3 "ATCU Library 2nd Leftside Blower Manager Buffer 3";
CM_ SG_ 866 L_ATCU_Lib_2LHMngrBlwBuf4 "ATCU Library 2nd Leftside Blower Manager Buffer 4";
CM_ SG_ 866 L_ATCU_Lib_2LHMngrBlwBuf5 "ATCU Library 2nd Leftside Blower Manager Buffer 5";
CM_ SG_ 866 L_ATCU_Lib_2LHMngrBlwBuf6 "ATCU Library 2nd Leftside Blower Manager Buffer 6";
CM_ SG_ 866 L_ATCU_Lib_2LHMngrBlwBufHi0 "ATCU Library 2nd Leftside Blower Manager Upper Limit Buffer 0";
CM_ SG_ 866 L_ATCU_Lib_2LHMngrBlwBufHi1 "ATCU Library 2nd Leftside Blower Manager Upper Limit Buffer 1";
CM_ SG_ 866 L_ATCU_Lib_2LHMngrModBuf2 "ATCU Library 2nd Leftside Mode Manager Buffer 2";
CM_ BO_ 867 "[PE] Periodic and On Event";
CM_ SG_ 867 L_ATCU_Lib_2LHMngrTempBuf0 "ATCU Library 2nd Leftside Temp Manager Buffer 0";
CM_ SG_ 867 L_ATCU_Lib_2RHMngrTempBuf0 "ATCU Library 2nd Rightside Temp Manager Buffer 0";
CM_ SG_ 867 L_ATCU_Lib_2RHMngrTempBuf1 "ATCU Library 2nd Rightside Temp Manager Buffer 1";
CM_ SG_ 867 L_ATCU_Lib_2RHMngrTempBuf2 "ATCU Library 2nd Rightside Temp Manager Buffer 2";
CM_ SG_ 867 L_ATCU_Lib_2LHMngrTempBuf1 "ATCU Library 2nd Leftside Temp Manager Buffer 1";
CM_ SG_ 867 L_ATCU_Lib_2LHMngrTempBuf2 "ATCU Library 2nd Leftside Temp Manager Buffer 2";
CM_ BO_ 868 "[PE] Periodic and On Event";
CM_ SG_ 868 L_ATCU_Lib_SWVer "ATCU_SoftWare_Version";
CM_ SG_ 868 L_ATCU_Lib_BlrMax "ATCU Library Blower Manager Buffer Max Data";
CM_ SG_ 868 L_ATCU_Lib_ModMax "ATCU Library Mode Manager Buffer Max Data";
CM_ SG_ 868 L_ATCU_Lib_IntakeMax "ATCU Library Intake Manager Buffer Max Data";
CM_ SG_ 868 L_ATCU_Lib_ACMax "ATCU Library AC Manager Buffer Max Data";
CM_ BO_ 869 "[PE] Periodic and On Event";
CM_ SG_ 869 L_ATCU_Lib_StatMngr_Humid "ATCU StateManagement Control Data (Humid)";
CM_ BO_ 870 "[PE] Periodic and On Event";
CM_ SG_ 870 L_ATCU_Lib_StatMngr_Temp "ATCU StateManagement Control Data (Temp)";
CM_ BO_ 871 "[PE] Periodic and On Event";
CM_ SG_ 871 L_ATCU_Lib_StatMngr_SafetynCool "ATCU StateManagement Control Data (SafetynCool)";
CM_ BO_ 872 "[PE] Periodic and On Event";
CM_ SG_ 872 L_ATCU_Lib_StatMngr_Mngr "ATCU StateManagement Control Data (Mngr)";
CM_ BO_ 873 "[PE] Periodic and On Event";
CM_ SG_ 873 L_ATCU_Lib_StatMngr_Convenience "ATCU StateManagement Control Data (Convenience)";
CM_ BO_ 874 "[PE] Periodic and On Event";
CM_ SG_ 874 L_ATCU_Lib_StatMngr_AirQuality "ATCU StateManagement Control Data (AirQuality)";
CM_ BO_ 875 "[PE] Periodic and On Event";
CM_ SG_ 875 L_ATCU_Lib_StatMngr_ETC "ATCU StateManagement Control Data (ETC)";
CM_ BO_ 876 "[PE] Periodic and On Event";
CM_ SG_ 876 L_ATCU_Lib_StatMngr_FuelEfficiency "ATCU StateManagement Control Data (FuelEfficiency)";
CM_ BO_ 877 "[PE] Periodic and On Event";
CM_ SG_ 877 L_ATCU_Lib_StatMngr_Snsr "ATCU StateManagement Control Data (Snsr)";
CM_ BO_ 878 "[PE] Periodic and On Event";
CM_ SG_ 878 L_ATCU_Lib_StatMngr_2ndHumid "ATCU StateManagement Control Data (2ndHumid)";
CM_ BO_ 879 "[PE] Periodic and On Event";
CM_ SG_ 879 L_ATCU_Lib_StatMngr_2ndTemp "ATCU StateManagement Control Data (2ndTemp)";
CM_ BO_ 886 "[PE] Periodic and On Event";
CM_ SG_ 886 L_ATCU_Lib_MEM_ROMWriteCnt "ATCU Memory ROM Write Count Data";
CM_ BO_ 1025 "[PE] Periodic and On Event";
CM_ SG_ 1025 L_EVNT_HU_FrDrEVntSidePtDisp_X "Front Driver Electric Vent Side Touch Point  X Value Display Feedback";
CM_ SG_ 1025 L_EVNT_HU_FrDrEVntSidePtDisp_Y "Front Driver Electric Vent Side Touch Point  Y Value Display Feedback";
CM_ SG_ 1025 L_EVNT_HU_FrDrEVntCtrPtDisp_X "Front Driver Electric Vent Center Touch Point  X Value Display Feedback";
CM_ SG_ 1025 L_EVNT_HU_FrDrEVntCtrPtDisp_Y "Front Driver Electric Vent Center Touch Point  Y Value Display Feedback";
CM_ BO_ 1026 "[PE] Periodic and On Event";
CM_ SG_ 1026 L_EVNT_HU_FrPsEVntSidePtDisp_X "Front Passenger Electric Vent Side Touch Point  X Value Display Feedback";
CM_ SG_ 1026 L_EVNT_HU_FrPsEVntSidePtDisp_Y "Front Passenger Electric Vent Side Touch Point  Y Value Display Feedback";
CM_ SG_ 1026 L_EVNT_HU_FrPsEVntCtrPtDisp_X "Front Passenger Electric Center Vent Touch Point  X Value Display Feedback";
CM_ SG_ 1026 L_EVNT_HU_FrPsEVntCtrPtDisp_Y "Front Passenger Electric Center Vent Touch Point  Y Value Display Feedback";
CM_ BO_ 1027 "[PE] Periodic and On Event";
CM_ SG_ 1027 L_EVNT_HU_RrDrEVntConsPtDisp_X "Rear Driver Electric Vent Console Touch Point  X Value Display Feedback";
CM_ SG_ 1027 L_EVNT_HU_RrDrEVntConsPtDisp_Y "Rear Driver Electric Vent Console Touch Point  Y Value Display Feedback";
CM_ SG_ 1027 L_EVNT_HU_RrPsEVntConsPtDisp_X "Rear Passenger Electric Vent Console Touch Point  X Value Display Feedback";
CM_ SG_ 1027 L_EVNT_HU_RrPsEVntConsPtDisp_Y "Rear Passenger Electric Vent Console Touch Point  Y Value Display Feedback";
CM_ SG_ 1027 L_EVNT_FrDrEVntSideFlt "Front Driver Electric Vent Side Fault Status";
CM_ SG_ 1027 L_EVNT_FrDrEVntCtrFlt "Front Driver Electric Vent Center Fault Status";
CM_ SG_ 1027 L_EVNT_FrPsEVntSideFlt "Front Passenger Electric Vent Side Fault Status";
CM_ SG_ 1027 L_EVNT_FrPsEVntCtrFlt "Front Passenger Electric Vent Center Fault Status";
CM_ SG_ 1027 L_EVNT_RrDrEVntConsFlt "Front Rear (2nd) Driver Electric Vent Console Fault Status";
CM_ SG_ 1027 L_EVNT_RrPsEVntConsFlt "Front Rear (2nd) Passenger Electric Vent Console Fault Status";
CM_ BO_ 1028 "[PE] Periodic and On Event";
CM_ SG_ 1028 L_EVNT_FrDrEVntModeSet_Disp "Front Driver Electric Vent Mode Display";
CM_ SG_ 1028 L_EVNT_RrPsEVntModeSet_Disp "Rear Passenger Electric Vent Mode Display";
CM_ SG_ 1028 L_EVNT_FrDrEVntSideOpnClsDisp "Front Driver Electric Vent Side Open Close Display";
CM_ SG_ 1028 L_EVNT_FrDrEVntCtrOpnClsDisp "Front Driver Electric Vent Center Open Close Display";
CM_ SG_ 1028 L_EVNT_FrPsEVntSideOpnClsDisp "Front Passenger Electric Vent Side Open Close Display";
CM_ SG_ 1028 L_EVNT_FrPsEVntCtrOpnClsDisp "Front Passenger Electric Vent Center Open Close Display";
CM_ SG_ 1028 L_EVNT_RrDrEVntConsOpnClsDisp "Rear Driver Electric Vent Console Open Close Display";
CM_ SG_ 1028 L_EVNT_RrPsEVntConsOpnClsDisp "Rear Passenger Electric Vent Open Console Close Display";
CM_ SG_ 1028 L_EVNT_EVntTouchInform_HU "Reply signal indicating whether to allow duplicate input signals for preventing overlapping of electric vent input signals";
CM_ SG_ 1028 L_EVNT_EVntTouchInform_CTS "Reply signal indicating whether to allow duplicate input signals for preventing overlapping of electric vent input signals";
CM_ SG_ 1028 L_EVNT_FrtEvntFocusLvlSta "status setting of front Electric Vent focus mode height level";
CM_ SG_ 1028 L_EVNT_RrEvntFocusLvlSta "status feedback of Rear Electric Vent focus mode height level";
CM_ SG_ 1028 L_EVNT_DrVntOpt "L_EVNT_DriverVentOption";
CM_ SG_ 1028 L_EVNT_FrPsEVntModeSet_Disp "Front Passenger Electric Vent Mode Display";
CM_ SG_ 1028 L_EVNT_AstVntOpt "L_EVNT_AssistVentOption";
CM_ SG_ 1028 L_EVNT_RrDrVntOpt "L_EVNT_RearDriverVentOption";
CM_ SG_ 1028 L_EVNT_RrAstVntOpt "L_EVNT_RearAssistVentOption";
CM_ SG_ 1028 L_EVNT_EVntAutoFlowHardSwOpt "L_EVNT_EVntAutoAirFlowHotKeyOpt";
CM_ SG_ 1028 L_EVNT_RrDrEVntModeSet_Disp "Rear Driver Electric Vent Mode Display";
CM_ BO_ 1029 "[PE] Periodic and On Event";
CM_ SG_ 1029 L_EVNT_CTS_FrDrEVntSidePtDisp_X "Front Driver Electric Vent Side Touch Point  X Value Display Feedback";
CM_ SG_ 1029 L_EVNT_CTS_FrDrEVntSidePtDisp_Y "Front Driver Electric Vent Side Touch Point  Y Value Display Feedback";
CM_ SG_ 1029 L_EVNT_CTS_FrDrEVntCtrPtDisp_X "Front Driver Electric Vent Center Touch Point  X Value Display Feedback";
CM_ SG_ 1029 L_EVNT_CTS_FrDrEVntCtrPtDisp_Y "Front Driver Electric Vent Center Touch Point  Y Value Display Feedback";
CM_ BO_ 1030 "[PE] Periodic and On Event";
CM_ SG_ 1030 L_EVNT_CTS_FrPsEVntSidePtDisp_X "Front Passenger Electric Vent Side Touch Point  X Value Display Feedback";
CM_ SG_ 1030 L_EVNT_CTS_FrPsEVntSidePtDisp_Y "Front Passenger Electric Vent Side Touch Point  Y Value Display Feedback";
CM_ SG_ 1030 L_EVNT_CTS_FrPsEVntCtrPtDisp_X "Front Passenger Electric Center Vent Touch Point  X Value Display Feedback";
CM_ SG_ 1030 L_EVNT_CTS_FrPsEVntCtrPtDisp_Y "Front Passenger Electric Center Vent Touch Point  Y Value Display Feedback";
CM_ BO_ 1031 "[PE] Periodic and On Event";
CM_ SG_ 1031 L_EVNT_CTS_RrDrEVntConsPtDisp_X "Rear Driver Electric Vent Console Touch Point  X Value Display Feedback";
CM_ SG_ 1031 L_EVNT_CTS_RrDrEVntConsPtDisp_Y "Rear Driver Electric Vent Console Touch Point  Y Value Display Feedback";
CM_ SG_ 1031 L_EVNT_CTS_RrPsEVntConsPtDisp_X "Rear Passenger Electric Vent Console Touch Point  X Value Display Feedback";
CM_ SG_ 1031 L_EVNT_CTS_RrPsEVntConsPtDisp_Y "Rear Passenger Electric Vent Console Touch Point  Y Value Display Feedback";
CM_ BO_ 1040 "[EC] On Event and On Change";
CM_ SG_ 1040 L_EVNT_FrDrEVntAutoFlowOSDReq "L_EVNT_FrDrEVntAutoAirFlowHotKeySw";
CM_ SG_ 1040 L_EVNT_FrAstEVntAutoFlowOSDReq "L_EVNT_FrAstEVntAutoAirFlowHotKeySw";
CM_ BO_ 320 "[P] Periodic";
CM_ SG_ 320 FHPTC_DrRdySta "FHPTC_DrReadyStatus";
CM_ SG_ 320 FHPTC_DrOpSta "FHPTC_DrOperationStatus";
CM_ SG_ 320 FHPTC_DrCnsmptPwr_W "FHPTC_DrConsumptionPower_W";
CM_ SG_ 320 FHPTC_DrCurrent_A "FHPTC_DrCurrent_A";
CM_ SG_ 320 FHPTC_DrCoreTemp_C "FHPTC_DrCoreTemp_C";
CM_ SG_ 320 FHPTC_DrDutyFB_Pec "FHPTC_DrDutyFeedBack_Percentile";
CM_ SG_ 320 FHPTC_DrDutyFB_IGBT "FHPTC_DrDutyFeedBack_IGBT";
CM_ SG_ 320 FHPTC_DrCtrlTyp "FHPTC_DrControlType";
CM_ SG_ 320 FHPTC_DrVoltage_V "FHPTC_DrVoltage_V";
CM_ BO_ 321 "[P] Periodic";
CM_ SG_ 321 FHPTC_DrFlt "FHPTC_DrFault";
CM_ SG_ 321 FHPTC_DrFltLVLow "FHPTC_DrFaultLVLow";
CM_ SG_ 321 FHPTC_DrFailLVSnr "FHPTC_DrFailLowVoltageSensor";
CM_ SG_ 321 FHPTC_DrFailCurrentSnr "FHPTC_DrFailCurrentSensor";
CM_ SG_ 321 FHPTC_DrFailCoreTempSnr "FHPTC_DrFailCoreTempSensor";
CM_ SG_ 321 FHPTC_DrFailPcbTempSnr "FHPTC_DrFailPcbTempSensor";
CM_ SG_ 321 FHPTC_DrFailIGBT "FHPTC_DrFailIGBT";
CM_ SG_ 321 FHPTC_DrFailOpenLoad "FHPTC_DrFailOpenLoad";
CM_ SG_ 321 FHPTC_DrLtdOpCause "FHPTC_DrLtdOperationCauseFlag";
CM_ SG_ 321 FHPTC_DrFltLVHigh "FHPTC_DrFaultLVHigh";
CM_ SG_ 321 FHPTC_DrSwVer "FHPTC_DrSoftwareVer";
CM_ SG_ 321 FHPTC_DrFltHVLow "FHPTC_DrFaultHVLow";
CM_ SG_ 321 FHPTC_CnsmptPwrTtl_W "FHPTC_ConsumptionPowerTotal_W";
CM_ SG_ 321 FHPTC_DrFltHVHigh "FHPTC_DrFaultHVHigh";
CM_ SG_ 321 FHPTC_IntlkSta "FHPTC_InterlockStatus";
CM_ SG_ 321 FHPTC_DrFltOverCurrent "FHPTC_DrFaultOverCurrent";
CM_ SG_ 321 FHPTC_DrFltThermalShutDn "FHPTC_DrFaultThermalShutDown";
CM_ SG_ 321 FHPTC_DrFltPcbThermalShutDn "FHPTC_DrFaultPcbThermalShutDown";
CM_ SG_ 321 FHPTC_DrFltMsgTmOutATCU "FHPTC_DrFaultMassgeTimemOutATCU";
CM_ SG_ 321 FHPTC_DrFailHVSnr "FHPTC_DrFailHighVoltageSensor";
CM_ BO_ 322 "[P] Periodic";
CM_ SG_ 322 FHPTC_PassRdySta "FHPTC_PassReadyStatus";
CM_ SG_ 322 FHPTC_PassOpSta "FHPTC_PassOperationStatus";
CM_ SG_ 322 FHPTC_PassCnsmptPwr_W "FHPTC_PassConsumptionPower_W";
CM_ SG_ 322 FHPTC_PassCtrlTyp "FHPTC_PassControlType";
CM_ SG_ 322 FHPTC_PassVoltage_V "FHPTC_PassVoltage_V";
CM_ SG_ 322 FHPTC_PassCurrent_A "FHPTC_PassCurrent_A";
CM_ SG_ 322 FHPTC_PassDutyFB_Pec "FHPTC_PassDutyFB_Percentile";
CM_ SG_ 322 FHPTC_PassDutyFB_IGBT "FHPTC_PassDutyFeedBack_IGBT";
CM_ SG_ 322 FHPTC_PassCoreTemp_C "FHPTC_PassCoreTemp_C";
CM_ BO_ 323 "[P] Periodic";
CM_ SG_ 323 FHPTC_PassFlt "FHPTC_PassFault";
CM_ SG_ 323 FHPTC_PassFltLVLow "FHPTC_PassFaultLVLow";
CM_ SG_ 323 FHPTC_PassFailLVSnr "FHPTC_PassFailLVSensor";
CM_ SG_ 323 FHPTC_PassFailCurrentSnr "FHPTC_PassFailCurrentSensor";
CM_ SG_ 323 FHPTC_PassFailCoreTempSnr "FHPTC_PassFailCoreTempSensor";
CM_ SG_ 323 FHPTC_PassFailPcbTempSnr "FHPTC_PassFailPcbTempSensor";
CM_ SG_ 323 FHPTC_PassFailIGBT "FHPTC_PassFailIGBT";
CM_ SG_ 323 FHPTC_PassFailOpenLoad "FHPTC_PassFailOpenLoad";
CM_ SG_ 323 FHPTC_PassLtdOpCause "FHPTC_PassLtdOperationCause";
CM_ SG_ 323 FHPTC_PassFltLVHigh "FHPTC_PassFaultLVHigh";
CM_ SG_ 323 FHPTC_PassSwVer "FHPTC_PassSoftwareVer";
CM_ SG_ 323 FHPTC_PassFltHVLow "FHPTC_PassFaultHVLow";
CM_ SG_ 323 FHPTC_PassFltHVHigh "FHPTC_PassFaultHVHigh";
CM_ SG_ 323 FHPTC_PassFltOverCurrent "FHPTC_PassFaultOverCurrent";
CM_ SG_ 323 FHPTC_PassFltThermalShutDn "FHPTC_PassFaultThermalShutDown";
CM_ SG_ 323 FHPTC_PassFltPcbThermalShutDn "FHPTC_PassFaultPcbThermalShutDown";
CM_ SG_ 323 FHPTC_PassFltMsgTmOutATCU "FHPTC_PassFaultMessageTimeOutATCU";
CM_ SG_ 323 FHPTC_PassFailHVSnr "FHPTC_PassFailHVSensor";
CM_ BO_ 324 "[P] Periodic";
CM_ SG_ 324 FHPTC_2ndDrRdySta "FHPTC_2ndDriverReadyStatus";
CM_ SG_ 324 FHPTC_2ndDrOpSta "FHPTC_2ndDriverOperationStatus";
CM_ SG_ 324 FHPTC_2ndDrCnsmptPwr_W "FHPTC_2ndDriverConsumptionPower_W";
CM_ SG_ 324 FHPTC_2ndDrCurrent_A "FHPTC_2ndDriverCurrent_A";
CM_ SG_ 324 FHPTC_2ndDrCoreTemp_C "FHPTC_2ndDriverCoreTemp_C";
CM_ SG_ 324 FHPTC_2ndDrDutyFB_Pec "FHPTC_2ndDriverDutyFeedBack_Percentile";
CM_ SG_ 324 FHPTC_2ndDrDutyFB_IGBT "FHPTC_2ndDriverDutyFeedBack_IGBT";
CM_ SG_ 324 FHPTC_2ndDrCtrlTyp "FHPTC_2ndDriverControlType";
CM_ SG_ 324 FHPTC_2ndDrVoltage_V "FHPTC_2ndDriverVoltage_V";
CM_ BO_ 325 "[P] Periodic";
CM_ SG_ 325 FHPTC_2ndDrFlt "FHPTC_2ndDriverFault";
CM_ SG_ 325 FHPTC_2ndDrFltLVLow "FHPTC_2ndDriverFaultLVLow";
CM_ SG_ 325 FHPTC_2ndDrFailLVSnr "FHPTC_2ndDriverFailLowVoltageSensor";
CM_ SG_ 325 FHPTC_2ndDrFailCurrentSnr "FHPTC_2ndDriverFailCurrentSensor";
CM_ SG_ 325 FHPTC_2ndDrFailCoreTempSnr "FHPTC_2ndDriverFailCoreTempSensor";
CM_ SG_ 325 FHPTC_2ndDrFailPcbTempSnr "FHPTC_2ndDriverFailPcbTempSensor";
CM_ SG_ 325 FHPTC_2ndDrFailIGBT "FHPTC_2ndDriverFailIGBT";
CM_ SG_ 325 FHPTC_2ndDrFailOpenLoad "FHPTC_2ndDriverFailOpenLoad";
CM_ SG_ 325 FHPTC_2ndDrLtdOpCause "FHPTC_2ndDriverLtdOperationCauseFlag";
CM_ SG_ 325 FHPTC_2ndDrFltLVHigh "FHPTC_2ndDriverFaultLVHigh";
CM_ SG_ 325 FHPTC_2ndDrSwVer "FHPTC_2ndDriverSoftwareVer";
CM_ SG_ 325 FHPTC_2ndDrFltHVLow "FHPTC_2ndDriverFaultHVLow";
CM_ SG_ 325 FHPTC_2ndDrFltHVHigh "FHPTC_2ndDriverFaultHVHigh";
CM_ SG_ 325 FHPTC_2ndDrFltOverCurrent "FHPTC_2ndDriverFaultOverCurrent";
CM_ SG_ 325 FHPTC_2ndDrFltThermalShutDn "FHPTC_2ndDriverFaultThermalShutDown";
CM_ SG_ 325 FHPTC_2ndDrFltPcbThermalShutDn "FHPTC_2ndDriverFaultPcbThermalShutDown";
CM_ SG_ 325 FHPTC_2ndDrFltMsgTmOutATCU "FHPTC_2ndDriverFaultMassgeTimemOutATCU";
CM_ SG_ 325 FHPTC_2ndDrFailHVSnr "FHPTC_2ndDriverFailHighVoltageSensor";
CM_ BO_ 326 "[P] Periodic";
CM_ SG_ 326 FHPTC_2ndPsRdySta "FHPTC_2ndPassengerReadyStatus";
CM_ SG_ 326 FHPTC_2ndPsOpSta "FHPTC_2ndPassengerOperationStatus";
CM_ SG_ 326 FHPTC_2ndPsCnsmptPwr_W "FHPTC_2ndPassengerConsumptionPower_W";
CM_ SG_ 326 FHPTC_2ndPsCtrlTyp "FHPTC_2ndPassengerControlType";
CM_ SG_ 326 FHPTC_2ndPsVoltage_V "FHPTC_2ndPassengerVoltage_V";
CM_ SG_ 326 FHPTC_2ndPsCurrent_A "FHPTC_2ndPassengerCurrent_A";
CM_ SG_ 326 FHPTC_2ndPsDutyFB_Pec "FHPTC_2ndPassengerDutyFB_Percentile";
CM_ SG_ 326 FHPTC_2ndPsDutyFB_IGBT "FHPTC_2ndPassengerDutyFeedBack_IGBT";
CM_ SG_ 326 FHPTC_2ndPsCoreTemp_C "FHPTC_2ndPassengerCoreTemp_C";
CM_ BO_ 327 "[P] Periodic";
CM_ SG_ 327 FHPTC_2ndPsFlt "FHPTC_2ndPassengerFault";
CM_ SG_ 327 FHPTC_2ndPsFltLVLow "FHPTC_2ndPassengerFaultLVLow";
CM_ SG_ 327 FHPTC_2ndPsFailLVSnr "FHPTC_2ndPassengerFailLVSensor";
CM_ SG_ 327 FHPTC_2ndPsFailCurrentSnr "FHPTC_2ndPassengerFailCurrentSensor";
CM_ SG_ 327 FHPTC_2ndPsFailCoreTempSnr "FHPTC_2ndPassengerFailCoreTempSensor";
CM_ SG_ 327 FHPTC_2ndPsFailPcbTempSnr "FHPTC_2ndPassengerFailPcbTempSensor";
CM_ SG_ 327 FHPTC_2ndPsFailIGBT "FHPTC_2ndPassengerFailIGBT";
CM_ SG_ 327 FHPTC_2ndPsFailOpenLoad "FHPTC_2ndPassengerFailOpenLoad";
CM_ SG_ 327 FHPTC_2ndPsLtdOpCause "FHPTC_2ndPassengerLtdOperationCause";
CM_ SG_ 327 FHPTC_2ndPsFltLVHigh "FHPTC_2ndPassengerFaultLVHigh";
CM_ SG_ 327 FHPTC_2ndPsSwVer "FHPTC_2ndPassengerSoftwareVer";
CM_ SG_ 327 FHPTC_2ndPsFltHVLow "FHPTC_2ndPassengerFaultHVLow";
CM_ SG_ 327 FHPTC_2ndPsFltHVHigh "FHPTC_2ndPassengerFaultHVHigh";
CM_ SG_ 327 FHPTC_2ndPsFltOverCurrent "FHPTC_2ndPassengerFaultOverCurrent";
CM_ SG_ 327 FHPTC_2ndPsFltThermalShutDn "FHPTC_2ndPassengerFaultThermalShutDown";
CM_ SG_ 327 FHPTC_2ndPsFltPcbThermalShutDn "FHPTC_2ndPassengerFaultPcbThermalShutDown";
CM_ SG_ 327 FHPTC_2ndPsFltMsgTmOutATCU "FHPTC_2ndPassengerFaultMessageTimeOutATCU";
CM_ SG_ 327 FHPTC_2ndPsFailHVSnr "FHPTC_2ndPassengerFailHVSensor";
CM_ BO_ 67 "[EC] On Event and On Change";
CM_ SG_ 67 HKBD_Fr_DrTempClickCnt "HKBD_Front_DriverTemperatureClickCount";
CM_ SG_ 67 HKBD_Fr_RrTempClickCnt "HKBD_Front_RearTemperatureClickCount";
CM_ SG_ 67 HKBD_Fr_DrBlwClickCnt "HKBD_Front_DriverBlowerClickCount";
CM_ SG_ 67 HKBD_Fr_PsBlwClickCnt "HKBD_Front_PassengerBlowerClickCount";
CM_ SG_ 67 HKBD_FrTempKnobCnt "HKBD_FrontTempKnobCount (for knobs rotate count)";
CM_ SG_ 67 HKBD_FrBlwKnobCnt "HKBD_FrontBlowerKnobCount (for knobs rotate count)";
CM_ SG_ 67 HKBD_Fr_PsTempClickCnt "HKBD_Front_PassengerTemperatureClickCount";
CM_ BO_ 72 "[P] Periodic";
CM_ SG_ 72 HKBD_Fr_IncarRaw "HKBD_Front_IncarSensorRawValue";
CM_ BO_ 624 "[P] Periodic";
CM_ SG_ 624 PCM_ActPosFB "Actuator Position F/B of Unit-Air Aroma";
CM_ SG_ 624 PCM_Blwr1Sta "Blower#1 Operating Status of Unit-Air Aroma";
CM_ SG_ 624 PCM_Blwr2Sta "Blower#2 Operating Status of Unit-Air Aroma";
CM_ SG_ 624 PCM_Blwr1Fail "Blower#1 Failure Flag";
CM_ SG_ 624 PCM_Blwr2Fail "Blower#2 Failure Flag";
CM_ SG_ 624 PCM_MainCtrlSta "Operation status of UAA Main Controller";
CM_ SG_ 624 PCM_Cart1Sta "Cartridge#1 Contact Status";
CM_ SG_ 624 PCM_Cart2Sta "Cartridge#2 Contact Status";
CM_ SG_ 624 PCM_Cart1Kinds "Cartridge#1 Fragnance Name";
CM_ SG_ 624 PCM_Cart2Kinds "Cartridge#2 Fragnance Name";
CM_ SG_ 624 PCM_ActSta "Actuator Operating Status of Unit-Air Aroma";
CM_ SG_ 624 PCM_ActFail "Actuator Failure Flag for Motor Stall";
CM_ BO_ 625 "[PE] Periodic and On Event";
CM_ SG_ 625 PCM_Cart1VectorX "X coordinate of Cartridge #1 for Mood Therapy";
CM_ SG_ 625 PCM_Cart1RmnPer "Percent of remaining perfume liquid of Cartridge #1";
CM_ SG_ 625 PCM_Cart1ExpSta "Status of Expiration Date of Cartridge #1";
CM_ SG_ 625 PCM_Cart1RmnDisp "Display for remaining perfume liquid of Cartridge #1";
CM_ SG_ 625 PCM_Cart1VectorY "Y coordinate of Cartridge #1 for Mood Therapy";
CM_ BO_ 626 "[PE] Periodic and On Event";
CM_ SG_ 626 PCM_Cart2VectorX "X coordinate of Cartridge #2 for Mood Therapy";
CM_ SG_ 626 PCM_Cart2RmnPer "Percent of remaining perfume liquid of Cartridge #2";
CM_ SG_ 626 PCM_Cart2ExpSta "Status of Expiration Date of Cartridge #1";
CM_ SG_ 626 PCM_Cart2RmnDisp "Display for remaining perfume liquid of Cartridge #2";
CM_ SG_ 626 PCM_Cart2VectorY "Y coordinate of Cartridge #2 for Mood Therapy";
CM_ BO_ 336 "[P] Periodic";
CM_ SG_ 336 RHPTC_Zone1RdySta "RHPTC_Zone1ReadyStatus (Zone1 : Dr or Roof)";
CM_ SG_ 336 RHPTC_Zone1OpSta "RHPTC_Zone1OperationStatus (Zone1 : Dr or Roof)";
CM_ SG_ 336 RHPTC_Zone1CnsmptPwr_W "RHPTC_Zone1ConsumptionPower_W (Zone1 : Dr or Roof)";
CM_ SG_ 336 RHPTC_Zone1Voltage_V "RHPTC_Zone1Voltage_V (Zone1 : Dr or Roof)";
CM_ SG_ 336 RHPTC_Zone1CtrlTyp "RHPTC_Zone1ControlType (Zone1 : Dr or Roof)";
CM_ SG_ 336 RHPTC_Zone1Current_A "RHPTC_Zone1Current_A (Zone1 : Dr or Roof)";
CM_ SG_ 336 RHPTC_Zone1DutyFB_Pec "RHPTC_Zone1DutyFeedBack_Percentile (Zone1 : Dr or Roof)";
CM_ SG_ 336 RHPTC_Zone1DutyFB_IGBT "RHPTC_Zone1DutyFeedBack_IGBT (Zone1 : Dr or Roof)";
CM_ SG_ 336 RHPTC_Zone1CoreTemp_C "RHPTC_Zone1CoreTemp_C (Zone1 : Dr or Roof)";
BA_DEF_ BO_ "UsrMsgIDSforwardDeviation" INT 0 100 ;
BA_DEF_ BO_ "UsrMsgIDSbackwardDeviation" INT 50 1000 ;
BA_DEF_ BO_ "GenMsgCycleTime" INT 0 2000 ;
BA_DEF_ BO_ "GenMsgStartDelayTime" INT 0 2000 ;
BA_DEF_ BO_ "GenMsgSendType" ENUM "Cyclic","NoMsgSendType" ;
BA_DEF_ BO_ "GenMsgCycleTimeFast" INT 0 500 ;
BA_DEF_ BO_ "GenMsgDelayTime" INT 0 20 ;
BA_DEF_ BO_ "GenMsgILSupport" ENUM "No","Yes" ;
BA_DEF_ BO_ "GenMsgNrOfRepetition" INT 0 3 ;
BA_DEF_ BO_ "VFrameFormat" ENUM "StandardCAN","ExtendedCAN","reserved","reserved","reserved","reserved","reserved","reserved","reserved","reserved","reserved","reserved","reserved","reserved","StandardCAN_FD","ExtendedCAN_FD" ;
BA_DEF_ SG_ "UserSigValidity" ENUM "B+","ACC","IG","IG1","IG2","IG3","IG1 or IG2","IG1 or IG3","Undef" ;
BA_DEF_ SG_ "UsrSigPurpose" ENUM "Undef","FN","DIAG","DIAG(Req)","DIAG(Res)","DIAG(Phy)","DEV","CCP(Req)","CCP(Res)","NM","TP" ;
BA_DEF_ SG_ "GenSigStartValue" INT 0 1215752192 ;
BA_DEF_ SG_ "NetworkRequestHoldingTime" INT 0 65535 ;
BA_DEF_ SG_ "Description" STRING ;
BA_DEF_ SG_ "Version" STRING ;
BA_DEF_ SG_ "GenSigEnvVarType" ENUM "Int","Float","Undef" ;
BA_DEF_ SG_ "GenSigSendType" ENUM "Cyclic","OnWrite","OnWriteWithRepetition","OnChange","OnChangeWithRepetition","IfActive","IfActiveWithRepetition","NoSigSendType","OnChangeAndIfActive","OnChangeAndIfActiveWithRepetition" ;
BA_DEF_ SG_ "GwSigLatencyTime" INT 0 65536 ;
BA_DEF_ SG_ "GwSigMissingSourceType" ENUM "Undef","OldValue","DefaultValue","InitialValue" ;
BA_DEF_ SG_ "NWM-WakeupAllowed" ENUM "<n.a.>" ;
BA_DEF_ SG_ "RoutingFactor" INT 1 1215752192 ;
BA_DEF_REL_ BU_SG_REL_ "GenSigTimeoutTime" INT 0 7000 ;
BA_DEF_DEF_ "UsrMsgIDSforwardDeviation" 10 ;
BA_DEF_DEF_ "UsrMsgIDSbackwardDeviation" 100 ;
BA_DEF_DEF_ "GenMsgCycleTime" 200 ;
BA_DEF_DEF_ "GenMsgStartDelayTime" 0 ;
BA_DEF_DEF_ "GenMsgSendType" "NoMsgSendType" ;
BA_DEF_DEF_ "GenMsgCycleTimeFast" 40 ;
BA_DEF_DEF_ "GenMsgDelayTime" 20 ;
BA_DEF_DEF_ "GenMsgILSupport" "Yes" ;
BA_DEF_DEF_ "GenMsgNrOfRepetition" 3 ;
BA_DEF_DEF_ "VFrameFormat" "StandardCAN" ;
BA_DEF_DEF_ "UserSigValidity" "IG" ;
BA_DEF_DEF_ "UsrSigPurpose" "FN" ;
BA_DEF_DEF_ "GenSigStartValue" 0 ;
BA_DEF_DEF_ "NetworkRequestHoldingTime" 0 ;
BA_DEF_DEF_ "Description" "" ;
BA_DEF_DEF_ "Version" "" ;
BA_DEF_DEF_ "GenSigEnvVarType" "Undef" ;
BA_DEF_DEF_ "GenSigSendType" "NoSigSendType" ;
BA_DEF_DEF_ "GwSigLatencyTime" 40 ;
BA_DEF_DEF_ "GwSigMissingSourceType" "Undef" ;
BA_DEF_DEF_ "NWM-WakeupAllowed" "<n.a.>" ;
BA_DEF_DEF_ "RoutingFactor" 1 ;
BA_DEF_DEF_REL_ "GenSigTimeoutTime" 500 ;
BA_ "GenMsgCycleTime" BO_ 102 0;
BA_ "GenSigSendType" SG_ 102 L_2HKBD_RrDrTempClickCnt 4;
BA_ "GenSigStartValue" SG_ 102 L_2HKBD_RrDrTempClickCnt 255;
BA_ "UserSigValidity" SG_ 102 L_2HKBD_RrDrTempClickCnt 7;
BA_REL_ "GenSigTimeoutTime" BU_SG_REL_ L_ATCU SG_ 102 L_2HKBD_RrDrTempClickCnt 0;
BA_ "Version" SG_ 102 L_2HKBD_RrDrTempClickCnt "24.01.00";
BA_ "GenSigSendType" SG_ 102 L_2HKBD_RrPsTempClickCnt 4;
BA_ "GenSigStartValue" SG_ 102 L_2HKBD_RrPsTempClickCnt 255;
BA_ "UserSigValidity" SG_ 102 L_2HKBD_RrPsTempClickCnt 7;
BA_REL_ "GenSigTimeoutTime" BU_SG_REL_ L_ATCU SG_ 102 L_2HKBD_RrPsTempClickCnt 0;
BA_ "Version" SG_ 102 L_2HKBD_RrPsTempClickCnt "24.01.00";
BA_ "GenSigSendType" SG_ 102 L_2HKBD_RrPsBlwrClickCnt 4;
BA_ "GenSigStartValue" SG_ 102 L_2HKBD_RrPsBlwrClickCnt 255;
BA_ "UserSigValidity" SG_ 102 L_2HKBD_RrPsBlwrClickCnt 7;
BA_REL_ "GenSigTimeoutTime" BU_SG_REL_ L_ATCU SG_ 102 L_2HKBD_RrPsBlwrClickCnt 0;
BA_ "Version" SG_ 102 L_2HKBD_RrPsBlwrClickCnt "24.01.00";
BA_ "GenSigSendType" SG_ 102 L_2HKBD_RrTempKnobCnt 4;
BA_ "GenSigStartValue" SG_ 102 L_2HKBD_RrTempKnobCnt 3;
BA_ "UserSigValidity" SG_ 102 L_2HKBD_RrTempKnobCnt 7;
BA_REL_ "GenSigTimeoutTime" BU_SG_REL_ L_ATCU SG_ 102 L_2HKBD_RrTempKnobCnt 0;
BA_ "Version" SG_ 102 L_2HKBD_RrTempKnobCnt "24.01.00";
BA_ "GenSigSendType" SG_ 102 L_2HKBD_RrBlwKnobCnt 4;
BA_ "GenSigStartValue" SG_ 102 L_2HKBD_RrBlwKnobCnt 3;
BA_ "UserSigValidity" SG_ 102 L_2HKBD_RrBlwKnobCnt 7;
BA_REL_ "GenSigTimeoutTime" BU_SG_REL_ L_ATCU SG_ 102 L_2HKBD_RrBlwKnobCnt 0;
BA_ "Version" SG_ 102 L_2HKBD_RrBlwKnobCnt "24.01.00";
BA_ "Description" SG_ 102 L_2HKBD_RrCurtainBtn "Rear Curtain Touch Button";
BA_ "GenSigSendType" SG_ 102 L_2HKBD_RrCurtainBtn 4;
BA_ "UserSigValidity" SG_ 102 L_2HKBD_RrCurtainBtn 7;
BA_REL_ "GenSigTimeoutTime" BU_SG_REL_ L_ATCU SG_ 102 L_2HKBD_RrCurtainBtn 0;
BA_ "Version" SG_ 102 L_2HKBD_RrCurtainBtn "25.08.06";
BA_ "Description" SG_ 102 L_2HKBD_HVACPnlBckLight_Res "Vehicle API HVAC Control Panel BackLight Response";
BA_ "GenSigSendType" SG_ 102 L_2HKBD_HVACPnlBckLight_Res 4;
BA_ "UserSigValidity" SG_ 102 L_2HKBD_HVACPnlBckLight_Res 7;
BA_REL_ "GenSigTimeoutTime" BU_SG_REL_ L_ATCU SG_ 102 L_2HKBD_HVACPnlBckLight_Res 0;
BA_ "Version" SG_ 102 L_2HKBD_HVACPnlBckLight_Res "25.08.06";
BA_ "GenSigSendType" SG_ 102 L_2HKBD_RrDrBlwrClickCnt 4;
BA_ "GenSigStartValue" SG_ 102 L_2HKBD_RrDrBlwrClickCnt 255;
BA_ "UserSigValidity" SG_ 102 L_2HKBD_RrDrBlwrClickCnt 7;
BA_REL_ "GenSigTimeoutTime" BU_SG_REL_ L_ATCU SG_ 102 L_2HKBD_RrDrBlwrClickCnt 0;
BA_ "Version" SG_ 102 L_2HKBD_RrDrBlwrClickCnt "24.01.00";
BA_ "GenMsgSendType" BO_ 851 0;
BA_ "GenMsgCycleTime" BO_ 851 500;
BA_ "Description" SG_ 851 L_ATCU_Lib_SnsrDrvVentDuct "This value only use for ATCU Library data monitoring (Only use before SOP)";
BA_ "GenSigSendType" SG_ 851 L_ATCU_Lib_SnsrDrvVentDuct 4;
BA_ "UserSigValidity" SG_ 851 L_ATCU_Lib_SnsrDrvVentDuct 0;
BA_REL_ "GenSigTimeoutTime" BU_SG_REL_ L_ATCU_vMON SG_ 851 L_ATCU_Lib_SnsrDrvVentDuct 5000;
BA_ "Version" SG_ 851 L_ATCU_Lib_SnsrDrvVentDuct "23.11.10";
BA_ "Description" SG_ 851 L_ATCU_Lib_SnsrAstVentDuct "This value only use for ATCU Library data monitoring (Only use before SOP)";
BA_ "GenSigSendType" SG_ 851 L_ATCU_Lib_SnsrAstVentDuct 4;
BA_ "UserSigValidity" SG_ 851 L_ATCU_Lib_SnsrAstVentDuct 0;
BA_REL_ "GenSigTimeoutTime" BU_SG_REL_ L_ATCU_vMON SG_ 851 L_ATCU_Lib_SnsrAstVentDuct 5000;
BA_ "Version" SG_ 851 L_ATCU_Lib_SnsrAstVentDuct "23.11.10";
BA_ "Description" SG_ 851 L_ATCU_Lib_SnsrDrvFloorDuct "This value only use for ATCU Library data monitoring (Only use before SOP)";
BA_ "GenSigSendType" SG_ 851 L_ATCU_Lib_SnsrDrvFloorDuct 4;
BA_ "UserSigValidity" SG_ 851 L_ATCU_Lib_SnsrDrvFloorDuct 0;
BA_REL_ "GenSigTimeoutTime" BU_SG_REL_ L_ATCU_vMON SG_ 851 L_ATCU_Lib_SnsrDrvFloorDuct 5000;
BA_ "Version" SG_ 851 L_ATCU_Lib_SnsrDrvFloorDuct "23.11.10";
BA_ "Description" SG_ 851 L_ATCU_Lib_SnsrAstFloorDuct "This value only use for ATCU Library data monitoring (Only use before SOP)";
BA_ "GenSigSendType" SG_ 851 L_ATCU_Lib_SnsrAstFloorDuct 4;
BA_ "UserSigValidity" SG_ 851 L_ATCU_Lib_SnsrAstFloorDuct 0;
BA_REL_ "GenSigTimeoutTime" BU_SG_REL_ L_ATCU_vMON SG_ 851 L_ATCU_Lib_SnsrAstFloorDuct 5000;
BA_ "Version" SG_ 851 L_ATCU_Lib_SnsrAstFloorDuct "23.11.10";
BA_ "GenMsgSendType" BO_ 864 0;
BA_ "GenMsgCycleTime" BO_ 864 500;
BA_ "Description" SG_ 864 L_ATCU_Lib_MngrDEFBuf0 "This value only use for ATCU Library data monitoring (Only use before SOP)";
BA_ "GenSigSendType" SG_ 864 L_ATCU_Lib_MngrDEFBuf0 4;
BA_ "UserSigValidity" SG_ 864 L_ATCU_Lib_MngrDEFBuf0 0;
BA_REL_ "GenSigTimeoutTime" BU_SG_REL_ L_ATCU_vMON SG_ 864 L_ATCU_Lib_MngrDEFBuf0 5000;
BA_ "Version" SG_ 864 L_ATCU_Lib_MngrDEFBuf0 "23.11.10";
BA_ "Description" SG_ 864 L_ATCU_Lib_MngrACBuf0 "This value only use for ATCU Library data monitoring (Only use before SOP)";
BA_ "GenSigSendType" SG_ 864 L_ATCU_Lib_MngrACBuf0 4;
BA_ "UserSigValidity" SG_ 864 L_ATCU_Lib_MngrACBuf0 0;
BA_REL_ "GenSigTimeoutTime" BU_SG_REL_ L_ATCU_vMON SG_ 864 L_ATCU_Lib_MngrACBuf0 5000;
BA_ "Version" SG_ 864 L_ATCU_Lib_MngrACBuf0 "23.11.10";
BA_ "Description" SG_ 864 L_ATCU_Lib_MngrACBuf1 "This value only use for ATCU Library data monitoring (Only use before SOP)";
BA_ "GenSigSendType" SG_ 864 L_ATCU_Lib_MngrACBuf1 4;
BA_ "UserSigValidity" SG_ 864 L_ATCU_Lib_MngrACBuf1 0;
BA_REL_ "GenSigTimeoutTime" BU_SG_REL_ L_ATCU_vMON SG_ 864 L_ATCU_Lib_MngrACBuf1 5000;
BA_ "Version" SG_ 864 L_ATCU_Lib_MngrACBuf1 "23.11.10";
BA_ "Description" SG_ 864 L_ATCU_Lib_MngrACBuf2 "This value only use for ATCU Library data monitoring (Only use before SOP)";
BA_ "GenSigSendType" SG_ 864 L_ATCU_Lib_MngrACBuf2 4;
BA_ "UserSigValidity" SG_ 864 L_ATCU_Lib_MngrACBuf2 0;
BA_REL_ "GenSigTimeoutTime" BU_SG_REL_ L_ATCU_vMON SG_ 864 L_ATCU_Lib_MngrACBuf2 5000;
BA_ "Version" SG_ 864 L_ATCU_Lib_MngrACBuf2 "23.11.10";
BA_ "Description" SG_ 864 L_ATCU_Lib_MngrACBuf3 "This value only use for ATCU Library data monitoring (Only use before SOP)";
BA_ "GenSigSendType" SG_ 864 L_ATCU_Lib_MngrACBuf3 4;
BA_ "UserSigValidity" SG_ 864 L_ATCU_Lib_MngrACBuf3 0;
BA_REL_ "GenSigTimeoutTime" BU_SG_REL_ L_ATCU_vMON SG_ 864 L_ATCU_Lib_MngrACBuf3 5000;
BA_ "Version" SG_ 864 L_ATCU_Lib_MngrACBuf3 "23.11.10";
BA_ "Description" SG_ 864 L_ATCU_Lib_MngrACBuf4 "This value only use for ATCU Library data monitoring (Only use before SOP)";
BA_ "GenSigSendType" SG_ 864 L_ATCU_Lib_MngrACBuf4 4;
BA_ "UserSigValidity" SG_ 864 L_ATCU_Lib_MngrACBuf4 0;
BA_REL_ "GenSigTimeoutTime" BU_SG_REL_ L_ATCU_vMON SG_ 864 L_ATCU_Lib_MngrACBuf4 5000;
BA_ "Version" SG_ 864 L_ATCU_Lib_MngrACBuf4 "23.11.10";
BA_ "Description" SG_ 864 L_ATCU_Lib_MngrDEFBuf1 "This value only use for ATCU Library data monitoring (Only use before SOP)";
BA_ "GenSigSendType" SG_ 864 L_ATCU_Lib_MngrDEFBuf1 4;
BA_ "UserSigValidity" SG_ 864 L_ATCU_Lib_MngrDEFBuf1 0;
BA_REL_ "GenSigTimeoutTime" BU_SG_REL_ L_ATCU_vMON SG_ 864 L_ATCU_Lib_MngrDEFBuf1 5000;
BA_ "Version" SG_ 864 L_ATCU_Lib_MngrDEFBuf1 "23.11.10";
BA_ "Description" SG_ 864 L_ATCU_Lib_MngrACBuf5 "This value only use for ATCU Library data monitoring (Only use before SOP)";
BA_ "GenSigSendType" SG_ 864 L_ATCU_Lib_MngrACBuf5 4;
BA_ "UserSigValidity" SG_ 864 L_ATCU_Lib_MngrACBuf5 0;
BA_REL_ "GenSigTimeoutTime" BU_SG_REL_ L_ATCU_vMON SG_ 864 L_ATCU_Lib_MngrACBuf5 5000;
BA_ "Version" SG_ 864 L_ATCU_Lib_MngrACBuf5 "23.11.10";
BA_ "Description" SG_ 864 L_ATCU_Lib_MngrACBuf6 "This value only use for ATCU Library data monitoring (Only use before SOP)";
BA_ "GenSigSendType" SG_ 864 L_ATCU_Lib_MngrACBuf6 4;
BA_ "UserSigValidity" SG_ 864 L_ATCU_Lib_MngrACBuf6 0;
BA_REL_ "GenSigTimeoutTime" BU_SG_REL_ L_ATCU_vMON SG_ 864 L_ATCU_Lib_MngrACBuf6 5000;
BA_ "Version" SG_ 864 L_ATCU_Lib_MngrACBuf6 "23.11.10";
BA_ "Description" SG_ 864 L_ATCU_Lib_MngrACBuf7 "This value only use for ATCU Library data monitoring (Only use before SOP)";
BA_ "GenSigSendType" SG_ 864 L_ATCU_Lib_MngrACBuf7 4;
BA_ "UserSigValidity" SG_ 864 L_ATCU_Lib_MngrACBuf7 0;
BA_REL_ "GenSigTimeoutTime" BU_SG_REL_ L_ATCU_vMON SG_ 864 L_ATCU_Lib_MngrACBuf7 5000;
BA_ "Version" SG_ 864 L_ATCU_Lib_MngrACBuf7 "23.11.10";
BA_ "Description" SG_ 864 L_ATCU_Lib_MngrDEFBufLow1 "This value only use for ATCU Library data monitoring (Only use before SOP)";
BA_ "GenSigSendType" SG_ 864 L_ATCU_Lib_MngrDEFBufLow1 4;
BA_ "UserSigValidity" SG_ 864 L_ATCU_Lib_MngrDEFBufLow1 0;
BA_REL_ "GenSigTimeoutTime" BU_SG_REL_ L_ATCU_vMON SG_ 864 L_ATCU_Lib_MngrDEFBufLow1 5000;
BA_ "Version" SG_ 864 L_ATCU_Lib_MngrDEFBufLow1 "23.11.10";
BA_ "Description" SG_ 864 L_ATCU_Lib_MngrTempBufLow1 "This value only use for ATCU Library data monitoring (Only use before SOP)";
BA_ "GenSigSendType" SG_ 864 L_ATCU_Lib_MngrTempBufLow1 4;
BA_ "UserSigValidity" SG_ 864 L_ATCU_Lib_MngrTempBufLow1 0;
BA_REL_ "GenSigTimeoutTime" BU_SG_REL_ L_ATCU_vMON SG_ 864 L_ATCU_Lib_MngrTempBufLow1 5000;
BA_ "Version" SG_ 864 L_ATCU_Lib_MngrTempBufLow1 "23.11.10";
BA_ "Description" SG_ 864 L_ATCU_Lib_MngrTempBufLow0 "This value only use for ATCU Library data monitoring (Only use before SOP)";
BA_ "GenSigSendType" SG_ 864 L_ATCU_Lib_MngrTempBufLow0 4;
BA_ "UserSigValidity" SG_ 864 L_ATCU_Lib_MngrTempBufLow0 0;
BA_REL_ "GenSigTimeoutTime" BU_SG_REL_ L_ATCU_vMON SG_ 864 L_ATCU_Lib_MngrTempBufLow0 5000;
BA_ "Version" SG_ 864 L_ATCU_Lib_MngrTempBufLow0 "23.11.10";
BA_ "Description" SG_ 864 L_ATCU_Lib_MngrIntakeBufHi0 "This value only use for ATCU Library data monitoring (Only use before SOP)";
BA_ "GenSigSendType" SG_ 864 L_ATCU_Lib_MngrIntakeBufHi0 4;
BA_ "UserSigValidity" SG_ 864 L_ATCU_Lib_MngrIntakeBufHi0 0;
BA_REL_ "GenSigTimeoutTime" BU_SG_REL_ L_ATCU_vMON SG_ 864 L_ATCU_Lib_MngrIntakeBufHi0 5000;
BA_ "Version" SG_ 864 L_ATCU_Lib_MngrIntakeBufHi0 "23.11.10";
BA_ "Description" SG_ 864 L_ATCU_Lib_MngrIntakeBufHi1 "This value only use for ATCU Library data monitoring (Only use before SOP)";
BA_ "GenSigSendType" SG_ 864 L_ATCU_Lib_MngrIntakeBufHi1 4;
BA_ "UserSigValidity" SG_ 864 L_ATCU_Lib_MngrIntakeBufHi1 0;
BA_REL_ "GenSigTimeoutTime" BU_SG_REL_ L_ATCU_vMON SG_ 864 L_ATCU_Lib_MngrIntakeBufHi1 5000;
BA_ "Version" SG_ 864 L_ATCU_Lib_MngrIntakeBufHi1 "23.11.10";
BA_ "Description" SG_ 864 L_ATCU_Lib_MngrIntakeBufLow2 "This value only use for ATCU Library data monitoring (Only use before SOP)";
BA_ "GenSigSendType" SG_ 864 L_ATCU_Lib_MngrIntakeBufLow2 4;
BA_ "UserSigValidity" SG_ 864 L_ATCU_Lib_MngrIntakeBufLow2 0;
BA_REL_ "GenSigTimeoutTime" BU_SG_REL_ L_ATCU_vMON SG_ 864 L_ATCU_Lib_MngrIntakeBufLow2 5000;
BA_ "Version" SG_ 864 L_ATCU_Lib_MngrIntakeBufLow2 "24.09.00";
BA_ "Description" SG_ 864 L_ATCU_Lib_MngrDEFBufLow0 "This value only use for ATCU Library data monitoring (Only use before SOP)";
BA_ "GenSigSendType" SG_ 864 L_ATCU_Lib_MngrDEFBufLow0 4;
BA_ "UserSigValidity" SG_ 864 L_ATCU_Lib_MngrDEFBufLow0 0;
BA_REL_ "GenSigTimeoutTime" BU_SG_REL_ L_ATCU_vMON SG_ 864 L_ATCU_Lib_MngrDEFBufLow0 5000;
BA_ "Version" SG_ 864 L_ATCU_Lib_MngrDEFBufLow0 "23.11.10";
BA_ "Description" SG_ 864 L_ATCU_Lib_MngrDEFBuf2 "This value only use for ATCU Library data monitoring (Only use before SOP)";
BA_ "GenSigSendType" SG_ 864 L_ATCU_Lib_MngrDEFBuf2 4;
BA_ "UserSigValidity" SG_ 864 L_ATCU_Lib_MngrDEFBuf2 0;
BA_REL_ "GenSigTimeoutTime" BU_SG_REL_ L_ATCU_vMON SG_ 864 L_ATCU_Lib_MngrDEFBuf2 5000;
BA_ "Version" SG_ 864 L_ATCU_Lib_MngrDEFBuf2 "23.11.10";
BA_ "GenMsgSendType" BO_ 865 0;
BA_ "GenMsgCycleTime" BO_ 865 500;
BA_ "Description" SG_ 865 L_ATCU_Lib_MngrIntakeBuf0 "This value only use for ATCU Library data monitoring (Only use before SOP)";
BA_ "GenSigSendType" SG_ 865 L_ATCU_Lib_MngrIntakeBuf0 4;
BA_ "UserSigValidity" SG_ 865 L_ATCU_Lib_MngrIntakeBuf0 0;
BA_REL_ "GenSigTimeoutTime" BU_SG_REL_ L_ATCU_vMON SG_ 865 L_ATCU_Lib_MngrIntakeBuf0 5000;
BA_ "Version" SG_ 865 L_ATCU_Lib_MngrIntakeBuf0 "25.05.03";
BA_ "Description" SG_ 865 L_ATCU_Lib_MngrIntakeBufLow1 "This value only use for ATCU Library data monitoring (Only use before SOP)";
BA_ "GenSigSendType" SG_ 865 L_ATCU_Lib_MngrIntakeBufLow1 4;
BA_ "UserSigValidity" SG_ 865 L_ATCU_Lib_MngrIntakeBufLow1 0;
BA_REL_ "GenSigTimeoutTime" BU_SG_REL_ L_ATCU_vMON SG_ 865 L_ATCU_Lib_MngrIntakeBufLow1 5000;
BA_ "Version" SG_ 865 L_ATCU_Lib_MngrIntakeBufLow1 "24.09.00";
BA_ "Description" SG_ 865 L_ATCU_Lib_MngrIntakeBuf2 "This value only use for ATCU Library data monitoring (Only use before SOP)";
BA_ "GenSigSendType" SG_ 865 L_ATCU_Lib_MngrIntakeBuf2 4;
BA_ "UserSigValidity" SG_ 865 L_ATCU_Lib_MngrIntakeBuf2 0;
BA_REL_ "GenSigTimeoutTime" BU_SG_REL_ L_ATCU_vMON SG_ 865 L_ATCU_Lib_MngrIntakeBuf2 5000;
BA_ "Version" SG_ 865 L_ATCU_Lib_MngrIntakeBuf2 "25.05.03";
BA_ "Description" SG_ 865 L_ATCU_Lib_MngrTempBuf0 "This value only use for ATCU Library data monitoring (Only use before SOP)";
BA_ "GenSigSendType" SG_ 865 L_ATCU_Lib_MngrTempBuf0 4;
BA_ "UserSigValidity" SG_ 865 L_ATCU_Lib_MngrTempBuf0 0;
BA_REL_ "GenSigTimeoutTime" BU_SG_REL_ L_ATCU_vMON SG_ 865 L_ATCU_Lib_MngrTempBuf0 5000;
BA_ "Version" SG_ 865 L_ATCU_Lib_MngrTempBuf0 "23.11.10";
BA_ "Description" SG_ 865 L_ATCU_Lib_MngrIntakeBuf3 "This value only use for ATCU Library data monitoring (Only use before SOP)";
BA_ "GenSigSendType" SG_ 865 L_ATCU_Lib_MngrIntakeBuf3 4;
BA_ "UserSigValidity" SG_ 865 L_ATCU_Lib_MngrIntakeBuf3 0;
BA_REL_ "GenSigTimeoutTime" BU_SG_REL_ L_ATCU_vMON SG_ 865 L_ATCU_Lib_MngrIntakeBuf3 5000;
BA_ "Version" SG_ 865 L_ATCU_Lib_MngrIntakeBuf3 "25.05.03";
BA_ "Description" SG_ 865 L_ATCU_Lib_MngrTempBuf1 "This value only use for ATCU Library data monitoring (Only use before SOP)";
BA_ "GenSigSendType" SG_ 865 L_ATCU_Lib_MngrTempBuf1 4;
BA_ "UserSigValidity" SG_ 865 L_ATCU_Lib_MngrTempBuf1 0;
BA_REL_ "GenSigTimeoutTime" BU_SG_REL_ L_ATCU_vMON SG_ 865 L_ATCU_Lib_MngrTempBuf1 5000;
BA_ "Version" SG_ 865 L_ATCU_Lib_MngrTempBuf1 "23.11.10";
BA_ "Description" SG_ 865 L_ATCU_Lib_MngrIntakeBuf4 "This value only use for ATCU Library data monitoring (Only use before SOP)";
BA_ "GenSigSendType" SG_ 865 L_ATCU_Lib_MngrIntakeBuf4 4;
BA_ "UserSigValidity" SG_ 865 L_ATCU_Lib_MngrIntakeBuf4 0;
BA_REL_ "GenSigTimeoutTime" BU_SG_REL_ L_ATCU_vMON SG_ 865 L_ATCU_Lib_MngrIntakeBuf4 5000;
BA_ "Version" SG_ 865 L_ATCU_Lib_MngrIntakeBuf4 "25.05.03";
BA_ "Description" SG_ 865 L_ATCU_Lib_MngrTempBuf2 "This value only use for ATCU Library data monitoring (Only use before SOP)";
BA_ "GenSigSendType" SG_ 865 L_ATCU_Lib_MngrTempBuf2 4;
BA_ "UserSigValidity" SG_ 865 L_ATCU_Lib_MngrTempBuf2 0;
BA_REL_ "GenSigTimeoutTime" BU_SG_REL_ L_ATCU_vMON SG_ 865 L_ATCU_Lib_MngrTempBuf2 5000;
BA_ "Version" SG_ 865 L_ATCU_Lib_MngrTempBuf2 "23.11.10";
BA_ "Description" SG_ 865 L_ATCU_Lib_MngrIntakeBuf5 "This value only use for ATCU Library data monitoring (Only use before SOP)";
BA_ "GenSigSendType" SG_ 865 L_ATCU_Lib_MngrIntakeBuf5 4;
BA_ "UserSigValidity" SG_ 865 L_ATCU_Lib_MngrIntakeBuf5 0;
BA_REL_ "GenSigTimeoutTime" BU_SG_REL_ L_ATCU_vMON SG_ 865 L_ATCU_Lib_MngrIntakeBuf5 5000;
BA_ "Version" SG_ 865 L_ATCU_Lib_MngrIntakeBuf5 "25.05.03";
BA_ "Description" SG_ 865 L_ATCU_Lib_MngrTempBuf3 "This value only use for ATCU Library data monitoring (Only use before SOP)";
BA_ "GenSigSendType" SG_ 865 L_ATCU_Lib_MngrTempBuf3 4;
BA_ "UserSigValidity" SG_ 865 L_ATCU_Lib_MngrTempBuf3 0;
BA_REL_ "GenSigTimeoutTime" BU_SG_REL_ L_ATCU_vMON SG_ 865 L_ATCU_Lib_MngrTempBuf3 5000;
BA_ "Version" SG_ 865 L_ATCU_Lib_MngrTempBuf3 "23.11.10";
BA_ "Description" SG_ 865 L_ATCU_Lib_MngrIntakeBuf6 "This value only use for ATCU Library data monitoring (Only use before SOP)";
BA_ "GenSigSendType" SG_ 865 L_ATCU_Lib_MngrIntakeBuf6 4;
BA_ "UserSigValidity" SG_ 865 L_ATCU_Lib_MngrIntakeBuf6 0;
BA_REL_ "GenSigTimeoutTime" BU_SG_REL_ L_ATCU_vMON SG_ 865 L_ATCU_Lib_MngrIntakeBuf6 5000;
BA_ "Version" SG_ 865 L_ATCU_Lib_MngrIntakeBuf6 "25.05.03";
BA_ "Description" SG_ 865 L_ATCU_Lib_MngrIntakeBufLow0 "This value only use for ATCU Library data monitoring (Only use before SOP)";
BA_ "GenSigSendType" SG_ 865 L_ATCU_Lib_MngrIntakeBufLow0 4;
BA_ "UserSigValidity" SG_ 865 L_ATCU_Lib_MngrIntakeBufLow0 0;
BA_REL_ "GenSigTimeoutTime" BU_SG_REL_ L_ATCU_vMON SG_ 865 L_ATCU_Lib_MngrIntakeBufLow0 5000;
BA_ "Version" SG_ 865 L_ATCU_Lib_MngrIntakeBufLow0 "24.09.00";
BA_ "Description" SG_ 865 L_ATCU_Lib_MngrTempBuf4 "This value only use for ATCU Library data monitoring (Only use before SOP)";
BA_ "GenSigSendType" SG_ 865 L_ATCU_Lib_MngrTempBuf4 4;
BA_ "UserSigValidity" SG_ 865 L_ATCU_Lib_MngrTempBuf4 0;
BA_REL_ "GenSigTimeoutTime" BU_SG_REL_ L_ATCU_vMON SG_ 865 L_ATCU_Lib_MngrTempBuf4 5000;
BA_ "Version" SG_ 865 L_ATCU_Lib_MngrTempBuf4 "23.11.10";
BA_ "Description" SG_ 865 L_ATCU_Lib_MngrIntakeBuf7 "This value only use for ATCU Library data monitoring (Only use before SOP)";
BA_ "GenSigSendType" SG_ 865 L_ATCU_Lib_MngrIntakeBuf7 4;
BA_ "UserSigValidity" SG_ 865 L_ATCU_Lib_MngrIntakeBuf7 0;
BA_REL_ "GenSigTimeoutTime" BU_SG_REL_ L_ATCU_vMON SG_ 865 L_ATCU_Lib_MngrIntakeBuf7 5000;
BA_ "Version" SG_ 865 L_ATCU_Lib_MngrIntakeBuf7 "25.05.03";
BA_ "Description" SG_ 865 L_ATCU_Lib_MngrTempBufLow2 "This value only use for ATCU Library data monitoring (Only use before SOP)";
BA_ "GenSigSendType" SG_ 865 L_ATCU_Lib_MngrTempBufLow2 4;
BA_ "UserSigValidity" SG_ 865 L_ATCU_Lib_MngrTempBufLow2 0;
BA_REL_ "GenSigTimeoutTime" BU_SG_REL_ L_ATCU_vMON SG_ 865 L_ATCU_Lib_MngrTempBufLow2 5000;
BA_ "Version" SG_ 865 L_ATCU_Lib_MngrTempBufLow2 "23.11.10";
BA_ "Description" SG_ 865 L_ATCU_Lib_MngrIntakeBuf1 "This value only use for ATCU Library data monitoring (Only use before SOP)";
BA_ "GenSigSendType" SG_ 865 L_ATCU_Lib_MngrIntakeBuf1 4;
BA_ "UserSigValidity" SG_ 865 L_ATCU_Lib_MngrIntakeBuf1 0;
BA_REL_ "GenSigTimeoutTime" BU_SG_REL_ L_ATCU_vMON SG_ 865 L_ATCU_Lib_MngrIntakeBuf1 5000;
BA_ "Version" SG_ 865 L_ATCU_Lib_MngrIntakeBuf1 "25.05.03";
BA_ "GenMsgSendType" BO_ 866 0;
BA_ "GenMsgCycleTime" BO_ 866 500;
BA_ "Description" SG_ 866 L_ATCU_Lib_2LHMngrModBuf0 "This value only use for ATCU Library data monitoring (Only use before SOP)";
BA_ "GenSigSendType" SG_ 866 L_ATCU_Lib_2LHMngrModBuf0 4;
BA_ "UserSigValidity" SG_ 866 L_ATCU_Lib_2LHMngrModBuf0 0;
BA_REL_ "GenSigTimeoutTime" BU_SG_REL_ L_ATCU_vMON SG_ 866 L_ATCU_Lib_2LHMngrModBuf0 5000;
BA_ "Version" SG_ 866 L_ATCU_Lib_2LHMngrModBuf0 "25.05.03";
BA_ "Description" SG_ 866 L_ATCU_Lib_2LHMngrModBuf3 "This value only use for ATCU Library data monitoring (Only use before SOP)";
BA_ "GenSigSendType" SG_ 866 L_ATCU_Lib_2LHMngrModBuf3 4;
BA_ "UserSigValidity" SG_ 866 L_ATCU_Lib_2LHMngrModBuf3 0;
BA_REL_ "GenSigTimeoutTime" BU_SG_REL_ L_ATCU_vMON SG_ 866 L_ATCU_Lib_2LHMngrModBuf3 5000;
BA_ "Version" SG_ 866 L_ATCU_Lib_2LHMngrModBuf3 "25.05.03";
BA_ "Description" SG_ 866 L_ATCU_Lib_2LHMngrModBuf4 "This value only use for ATCU Library data monitoring (Only use before SOP)";
BA_ "GenSigSendType" SG_ 866 L_ATCU_Lib_2LHMngrModBuf4 4;
BA_ "UserSigValidity" SG_ 866 L_ATCU_Lib_2LHMngrModBuf4 0;
BA_REL_ "GenSigTimeoutTime" BU_SG_REL_ L_ATCU_vMON SG_ 866 L_ATCU_Lib_2LHMngrModBuf4 5000;
BA_ "Version" SG_ 866 L_ATCU_Lib_2LHMngrModBuf4 "25.05.03";
BA_ "Description" SG_ 866 L_ATCU_Lib_2LHMngrModBuf5 "This value only use for ATCU Library data monitoring (Only use before SOP)";
BA_ "GenSigSendType" SG_ 866 L_ATCU_Lib_2LHMngrModBuf5 4;
BA_ "UserSigValidity" SG_ 866 L_ATCU_Lib_2LHMngrModBuf5 0;
BA_REL_ "GenSigTimeoutTime" BU_SG_REL_ L_ATCU_vMON SG_ 866 L_ATCU_Lib_2LHMngrModBuf5 5000;
BA_ "Version" SG_ 866 L_ATCU_Lib_2LHMngrModBuf5 "25.05.03";
BA_ "Description" SG_ 866 L_ATCU_Lib_2LHMngrModBuf6 "This value only use for ATCU Library data monitoring (Only use before SOP)";
BA_ "GenSigSendType" SG_ 866 L_ATCU_Lib_2LHMngrModBuf6 4;
BA_ "UserSigValidity" SG_ 866 L_ATCU_Lib_2LHMngrModBuf6 0;
BA_REL_ "GenSigTimeoutTime" BU_SG_REL_ L_ATCU_vMON SG_ 866 L_ATCU_Lib_2LHMngrModBuf6 5000;
BA_ "Version" SG_ 866 L_ATCU_Lib_2LHMngrModBuf6 "25.05.03";
BA_ "Description" SG_ 866 L_ATCU_Lib_2LHMngrModBuf7 "This value only use for ATCU Library data monitoring (Only use before SOP)";
BA_ "GenSigSendType" SG_ 866 L_ATCU_Lib_2LHMngrModBuf7 4;
BA_ "UserSigValidity" SG_ 866 L_ATCU_Lib_2LHMngrModBuf7 0;
BA_REL_ "GenSigTimeoutTime" BU_SG_REL_ L_ATCU_vMON SG_ 866 L_ATCU_Lib_2LHMngrModBuf7 5000;
BA_ "Version" SG_ 866 L_ATCU_Lib_2LHMngrModBuf7 "25.05.03";
BA_ "Description" SG_ 866 L_ATCU_Lib_2LHMngrBlwBuf0 "This value only use for ATCU Library data monitoring (Only use before SOP)";
BA_ "GenSigSendType" SG_ 866 L_ATCU_Lib_2LHMngrBlwBuf0 4;
BA_ "UserSigValidity" SG_ 866 L_ATCU_Lib_2LHMngrBlwBuf0 0;
BA_REL_ "GenSigTimeoutTime" BU_SG_REL_ L_ATCU_vMON SG_ 866 L_ATCU_Lib_2LHMngrBlwBuf0 5000;
BA_ "Version" SG_ 866 L_ATCU_Lib_2LHMngrBlwBuf0 "25.05.03";
BA_ "Description" SG_ 866 L_ATCU_Lib_2LHMngrBlwBuf1 "This value only use for ATCU Library data monitoring (Only use before SOP)";
BA_ "GenSigSendType" SG_ 866 L_ATCU_Lib_2LHMngrBlwBuf1 4;
BA_ "UserSigValidity" SG_ 866 L_ATCU_Lib_2LHMngrBlwBuf1 0;
BA_REL_ "GenSigTimeoutTime" BU_SG_REL_ L_ATCU_vMON SG_ 866 L_ATCU_Lib_2LHMngrBlwBuf1 5000;
BA_ "Version" SG_ 866 L_ATCU_Lib_2LHMngrBlwBuf1 "25.05.03";
BA_ "Description" SG_ 866 L_ATCU_Lib_2LHMngrModBuf1 "This value only use for ATCU Library data monitoring (Only use before SOP)";
BA_ "GenSigSendType" SG_ 866 L_ATCU_Lib_2LHMngrModBuf1 4;
BA_ "UserSigValidity" SG_ 866 L_ATCU_Lib_2LHMngrModBuf1 0;
BA_REL_ "GenSigTimeoutTime" BU_SG_REL_ L_ATCU_vMON SG_ 866 L_ATCU_Lib_2LHMngrModBuf1 5000;
BA_ "Version" SG_ 866 L_ATCU_Lib_2LHMngrModBuf1 "25.05.03";
BA_ "Description" SG_ 866 L_ATCU_Lib_2LHMngrBlwBuf2 "This value only use for ATCU Library data monitoring (Only use before SOP)";
BA_ "GenSigSendType" SG_ 866 L_ATCU_Lib_2LHMngrBlwBuf2 4;
BA_ "UserSigValidity" SG_ 866 L_ATCU_Lib_2LHMngrBlwBuf2 0;
BA_REL_ "GenSigTimeoutTime" BU_SG_REL_ L_ATCU_vMON SG_ 866 L_ATCU_Lib_2LHMngrBlwBuf2 5000;
BA_ "Version" SG_ 866 L_ATCU_Lib_2LHMngrBlwBuf2 "25.05.03";
BA_ "Description" SG_ 866 L_ATCU_Lib_2LHMngrBlwBuf3 "This value only use for ATCU Library data monitoring (Only use before SOP)";
BA_ "GenSigSendType" SG_ 866 L_ATCU_Lib_2LHMngrBlwBuf3 4;
BA_ "UserSigValidity" SG_ 866 L_ATCU_Lib_2LHMngrBlwBuf3 0;
BA_REL_ "GenSigTimeoutTime" BU_SG_REL_ L_ATCU_vMON SG_ 866 L_ATCU_Lib_2LHMngrBlwBuf3 5000;
BA_ "Version" SG_ 866 L_ATCU_Lib_2LHMngrBlwBuf3 "25.05.03";
BA_ "Description" SG_ 866 L_ATCU_Lib_2LHMngrBlwBuf4 "This value only use for ATCU Library data monitoring (Only use before SOP)";
BA_ "GenSigSendType" SG_ 866 L_ATCU_Lib_2LHMngrBlwBuf4 4;
BA_ "UserSigValidity" SG_ 866 L_ATCU_Lib_2LHMngrBlwBuf4 0;
BA_REL_ "GenSigTimeoutTime" BU_SG_REL_ L_ATCU_vMON SG_ 866 L_ATCU_Lib_2LHMngrBlwBuf4 5000;
BA_ "Version" SG_ 866 L_ATCU_Lib_2LHMngrBlwBuf4 "25.05.03";
BA_ "Description" SG_ 866 L_ATCU_Lib_2LHMngrBlwBuf5 "This value only use for ATCU Library data monitoring (Only use before SOP)";
BA_ "GenSigSendType" SG_ 866 L_ATCU_Lib_2LHMngrBlwBuf5 4;
BA_ "UserSigValidity" SG_ 866 L_ATCU_Lib_2LHMngrBlwBuf5 0;
BA_REL_ "GenSigTimeoutTime" BU_SG_REL_ L_ATCU_vMON SG_ 866 L_ATCU_Lib_2LHMngrBlwBuf5 5000;
BA_ "Version" SG_ 866 L_ATCU_Lib_2LHMngrBlwBuf5 "25.05.03";
BA_ "Description" SG_ 866 L_ATCU_Lib_2LHMngrBlwBuf6 "This value only use for ATCU Library data monitoring (Only use before SOP)";
BA_ "GenSigSendType" SG_ 866 L_ATCU_Lib_2LHMngrBlwBuf6 4;
BA_ "UserSigValidity" SG_ 866 L_ATCU_Lib_2LHMngrBlwBuf6 0;
BA_REL_ "GenSigTimeoutTime" BU_SG_REL_ L_ATCU_vMON SG_ 866 L_ATCU_Lib_2LHMngrBlwBuf6 5000;
BA_ "Version" SG_ 866 L_ATCU_Lib_2LHMngrBlwBuf6 "25.05.03";
BA_ "Description" SG_ 866 L_ATCU_Lib_2LHMngrBlwBufHi0 "This value only use for ATCU Library data monitoring (Only use before SOP)";
BA_ "GenSigSendType" SG_ 866 L_ATCU_Lib_2LHMngrBlwBufHi0 4;
BA_ "UserSigValidity" SG_ 866 L_ATCU_Lib_2LHMngrBlwBufHi0 0;
BA_REL_ "GenSigTimeoutTime" BU_SG_REL_ L_ATCU_vMON SG_ 866 L_ATCU_Lib_2LHMngrBlwBufHi0 5000;
BA_ "Version" SG_ 866 L_ATCU_Lib_2LHMngrBlwBufHi0 "23.11.10";
BA_ "Description" SG_ 866 L_ATCU_Lib_2LHMngrBlwBufHi1 "This value only use for ATCU Library data monitoring (Only use before SOP)";
BA_ "GenSigSendType" SG_ 866 L_ATCU_Lib_2LHMngrBlwBufHi1 4;
BA_ "UserSigValidity" SG_ 866 L_ATCU_Lib_2LHMngrBlwBufHi1 0;
BA_REL_ "GenSigTimeoutTime" BU_SG_REL_ L_ATCU_vMON SG_ 866 L_ATCU_Lib_2LHMngrBlwBufHi1 5000;
BA_ "Version" SG_ 866 L_ATCU_Lib_2LHMngrBlwBufHi1 "23.11.10";
BA_ "Description" SG_ 866 L_ATCU_Lib_2LHMngrModBuf2 "This value only use for ATCU Library data monitoring (Only use before SOP)";
BA_ "GenSigSendType" SG_ 866 L_ATCU_Lib_2LHMngrModBuf2 4;
BA_ "UserSigValidity" SG_ 866 L_ATCU_Lib_2LHMngrModBuf2 0;
BA_REL_ "GenSigTimeoutTime" BU_SG_REL_ L_ATCU_vMON SG_ 866 L_ATCU_Lib_2LHMngrModBuf2 5000;
BA_ "Version" SG_ 866 L_ATCU_Lib_2LHMngrModBuf2 "25.05.03";
BA_ "GenMsgSendType" BO_ 867 0;
BA_ "GenMsgCycleTime" BO_ 867 500;
BA_ "Description" SG_ 867 L_ATCU_Lib_2LHMngrTempBuf0 "This value only use for ATCU Library data monitoring (Only use before SOP)";
BA_ "GenSigSendType" SG_ 867 L_ATCU_Lib_2LHMngrTempBuf0 4;
BA_ "UserSigValidity" SG_ 867 L_ATCU_Lib_2LHMngrTempBuf0 0;
BA_REL_ "GenSigTimeoutTime" BU_SG_REL_ L_ATCU_vMON SG_ 867 L_ATCU_Lib_2LHMngrTempBuf0 5000;
BA_ "Version" SG_ 867 L_ATCU_Lib_2LHMngrTempBuf0 "23.11.10";
BA_ "Description" SG_ 867 L_ATCU_Lib_2RHMngrTempBuf0 "This value only use for ATCU Library data monitoring (Only use before SOP)";
BA_ "GenSigSendType" SG_ 867 L_ATCU_Lib_2RHMngrTempBuf0 4;
BA_ "UserSigValidity" SG_ 867 L_ATCU_Lib_2RHMngrTempBuf0 0;
BA_REL_ "GenSigTimeoutTime" BU_SG_REL_ L_ATCU_vMON SG_ 867 L_ATCU_Lib_2RHMngrTempBuf0 5000;
BA_ "Version" SG_ 867 L_ATCU_Lib_2RHMngrTempBuf0 "23.11.10";
BA_ "Description" SG_ 867 L_ATCU_Lib_2RHMngrTempBuf1 "This value only use for ATCU Library data monitoring (Only use before SOP)";
BA_ "GenSigSendType" SG_ 867 L_ATCU_Lib_2RHMngrTempBuf1 4;
BA_ "UserSigValidity" SG_ 867 L_ATCU_Lib_2RHMngrTempBuf1 0;
BA_REL_ "GenSigTimeoutTime" BU_SG_REL_ L_ATCU_vMON SG_ 867 L_ATCU_Lib_2RHMngrTempBuf1 5000;
BA_ "Version" SG_ 867 L_ATCU_Lib_2RHMngrTempBuf1 "23.11.10";
BA_ "Description" SG_ 867 L_ATCU_Lib_2RHMngrTempBuf2 "This value only use for ATCU Library data monitoring (Only use before SOP)";
BA_ "GenSigSendType" SG_ 867 L_ATCU_Lib_2RHMngrTempBuf2 4;
BA_ "UserSigValidity" SG_ 867 L_ATCU_Lib_2RHMngrTempBuf2 0;
BA_REL_ "GenSigTimeoutTime" BU_SG_REL_ L_ATCU_vMON SG_ 867 L_ATCU_Lib_2RHMngrTempBuf2 5000;
BA_ "Version" SG_ 867 L_ATCU_Lib_2RHMngrTempBuf2 "23.11.10";
BA_ "Description" SG_ 867 L_ATCU_Lib_2LHMngrTempBuf1 "This value only use for ATCU Library data monitoring (Only use before SOP)";
BA_ "GenSigSendType" SG_ 867 L_ATCU_Lib_2LHMngrTempBuf1 4;
BA_ "UserSigValidity" SG_ 867 L_ATCU_Lib_2LHMngrTempBuf1 0;
BA_REL_ "GenSigTimeoutTime" BU_SG_REL_ L_ATCU_vMON SG_ 867 L_ATCU_Lib_2LHMngrTempBuf1 5000;
BA_ "Version" SG_ 867 L_ATCU_Lib_2LHMngrTempBuf1 "23.11.10";
BA_ "Description" SG_ 867 L_ATCU_Lib_2LHMngrTempBuf2 "This value only use for ATCU Library data monitoring (Only use before SOP)";
BA_ "GenSigSendType" SG_ 867 L_ATCU_Lib_2LHMngrTempBuf2 4;
BA_ "UserSigValidity" SG_ 867 L_ATCU_Lib_2LHMngrTempBuf2 0;
BA_REL_ "GenSigTimeoutTime" BU_SG_REL_ L_ATCU_vMON SG_ 867 L_ATCU_Lib_2LHMngrTempBuf2 5000;
BA_ "Version" SG_ 867 L_ATCU_Lib_2LHMngrTempBuf2 "23.11.10";
BA_ "GenMsgSendType" BO_ 868 0;
BA_ "GenMsgCycleTime" BO_ 868 1000;
BA_ "Description" SG_ 868 L_ATCU_Lib_SWVer "Local CAN Signal to check library application version";
BA_ "GenSigSendType" SG_ 868 L_ATCU_Lib_SWVer 4;
BA_ "UserSigValidity" SG_ 868 L_ATCU_Lib_SWVer 0;
BA_REL_ "GenSigTimeoutTime" BU_SG_REL_ L_ATCU_vMON SG_ 868 L_ATCU_Lib_SWVer 3000;
BA_ "Version" SG_ 868 L_ATCU_Lib_SWVer "25.05.03";
BA_ "Description" SG_ 868 L_ATCU_Lib_BlrMax "ATCU Library Blower Manager Buffer Max Data";
BA_ "GenSigSendType" SG_ 868 L_ATCU_Lib_BlrMax 4;
BA_ "UserSigValidity" SG_ 868 L_ATCU_Lib_BlrMax 0;
BA_REL_ "GenSigTimeoutTime" BU_SG_REL_ L_ATCU_vMON SG_ 868 L_ATCU_Lib_BlrMax 3000;
BA_ "Version" SG_ 868 L_ATCU_Lib_BlrMax "25.05.03";
BA_ "Description" SG_ 868 L_ATCU_Lib_ModMax "ATCU Library Mode Manager Buffer Max Data";
BA_ "GenSigSendType" SG_ 868 L_ATCU_Lib_ModMax 4;
BA_ "UserSigValidity" SG_ 868 L_ATCU_Lib_ModMax 0;
BA_REL_ "GenSigTimeoutTime" BU_SG_REL_ L_ATCU_vMON SG_ 868 L_ATCU_Lib_ModMax 3000;
BA_ "Version" SG_ 868 L_ATCU_Lib_ModMax "25.05.03";
BA_ "Description" SG_ 868 L_ATCU_Lib_IntakeMax "ATCU Library Intake Manager Buffer Max Data";
BA_ "GenSigSendType" SG_ 868 L_ATCU_Lib_IntakeMax 4;
BA_ "UserSigValidity" SG_ 868 L_ATCU_Lib_IntakeMax 0;
BA_REL_ "GenSigTimeoutTime" BU_SG_REL_ L_ATCU_vMON SG_ 868 L_ATCU_Lib_IntakeMax 3000;
BA_ "Version" SG_ 868 L_ATCU_Lib_IntakeMax "25.05.03";
BA_ "Description" SG_ 868 L_ATCU_Lib_ACMax "ATCU Library AC Manager Buffer Max Data";
BA_ "GenSigSendType" SG_ 868 L_ATCU_Lib_ACMax 4;
BA_ "UserSigValidity" SG_ 868 L_ATCU_Lib_ACMax 0;
BA_REL_ "GenSigTimeoutTime" BU_SG_REL_ L_ATCU_vMON SG_ 868 L_ATCU_Lib_ACMax 3000;
BA_ "Version" SG_ 868 L_ATCU_Lib_ACMax "25.05.03";
BA_ "GenMsgSendType" BO_ 869 0;
BA_ "GenMsgCycleTime" BO_ 869 2000;
BA_ "Description" SG_ 869 L_ATCU_Lib_StatMngr_Humid "This value only use for ATCU Library data monitoring (Only use before SOP)";
BA_ "GenSigSendType" SG_ 869 L_ATCU_Lib_StatMngr_Humid 4;
BA_ "UserSigValidity" SG_ 869 L_ATCU_Lib_StatMngr_Humid 0;
BA_REL_ "GenSigTimeoutTime" BU_SG_REL_ L_ATCU_vMON SG_ 869 L_ATCU_Lib_StatMngr_Humid 5000;
BA_ "Version" SG_ 869 L_ATCU_Lib_StatMngr_Humid "24.09.01";
BA_ "GenMsgSendType" BO_ 870 0;
BA_ "GenMsgCycleTime" BO_ 870 2000;
BA_ "Description" SG_ 870 L_ATCU_Lib_StatMngr_Temp "This value only use for ATCU Library data monitoring (Only use before SOP)";
BA_ "GenSigSendType" SG_ 870 L_ATCU_Lib_StatMngr_Temp 4;
BA_ "UserSigValidity" SG_ 870 L_ATCU_Lib_StatMngr_Temp 0;
BA_REL_ "GenSigTimeoutTime" BU_SG_REL_ L_ATCU_vMON SG_ 870 L_ATCU_Lib_StatMngr_Temp 5000;
BA_ "Version" SG_ 870 L_ATCU_Lib_StatMngr_Temp "24.09.01";
BA_ "GenMsgSendType" BO_ 871 0;
BA_ "GenMsgCycleTime" BO_ 871 2000;
BA_ "Description" SG_ 871 L_ATCU_Lib_StatMngr_SafetynCool "This value only use for ATCU Library data monitoring (Only use before SOP)";
BA_ "GenSigSendType" SG_ 871 L_ATCU_Lib_StatMngr_SafetynCool 4;
BA_ "UserSigValidity" SG_ 871 L_ATCU_Lib_StatMngr_SafetynCool 0;
BA_REL_ "GenSigTimeoutTime" BU_SG_REL_ L_ATCU_vMON SG_ 871 L_ATCU_Lib_StatMngr_SafetynCool 5000;
BA_ "Version" SG_ 871 L_ATCU_Lib_StatMngr_SafetynCool "24.09.01";
BA_ "GenMsgSendType" BO_ 872 0;
BA_ "GenMsgCycleTime" BO_ 872 2000;
BA_ "Description" SG_ 872 L_ATCU_Lib_StatMngr_Mngr "This value only use for ATCU Library data monitoring (Only use before SOP)";
BA_ "GenSigSendType" SG_ 872 L_ATCU_Lib_StatMngr_Mngr 4;
BA_ "UserSigValidity" SG_ 872 L_ATCU_Lib_StatMngr_Mngr 0;
BA_REL_ "GenSigTimeoutTime" BU_SG_REL_ L_ATCU_vMON SG_ 872 L_ATCU_Lib_StatMngr_Mngr 5000;
BA_ "Version" SG_ 872 L_ATCU_Lib_StatMngr_Mngr "24.09.01";
BA_ "GenMsgSendType" BO_ 873 0;
BA_ "GenMsgCycleTime" BO_ 873 2000;
BA_ "Description" SG_ 873 L_ATCU_Lib_StatMngr_Convenience "This value only use for ATCU Library data monitoring (Only use before SOP)";
BA_ "GenSigSendType" SG_ 873 L_ATCU_Lib_StatMngr_Convenience 4;
BA_ "UserSigValidity" SG_ 873 L_ATCU_Lib_StatMngr_Convenience 0;
BA_REL_ "GenSigTimeoutTime" BU_SG_REL_ L_ATCU_vMON SG_ 873 L_ATCU_Lib_StatMngr_Convenience 5000;
BA_ "Version" SG_ 873 L_ATCU_Lib_StatMngr_Convenience "24.09.01";
BA_ "GenMsgSendType" BO_ 874 0;
BA_ "GenMsgCycleTime" BO_ 874 2000;
BA_ "Description" SG_ 874 L_ATCU_Lib_StatMngr_AirQuality "This value only use for ATCU Library data monitoring (Only use before SOP)";
BA_ "GenSigSendType" SG_ 874 L_ATCU_Lib_StatMngr_AirQuality 4;
BA_ "UserSigValidity" SG_ 874 L_ATCU_Lib_StatMngr_AirQuality 0;
BA_REL_ "GenSigTimeoutTime" BU_SG_REL_ L_ATCU_vMON SG_ 874 L_ATCU_Lib_StatMngr_AirQuality 5000;
BA_ "Version" SG_ 874 L_ATCU_Lib_StatMngr_AirQuality "24.09.01";
BA_ "GenMsgSendType" BO_ 875 0;
BA_ "GenMsgCycleTime" BO_ 875 2000;
BA_ "Description" SG_ 875 L_ATCU_Lib_StatMngr_ETC "This value only use for ATCU Library data monitoring (Only use before SOP)";
BA_ "GenSigSendType" SG_ 875 L_ATCU_Lib_StatMngr_ETC 4;
BA_ "UserSigValidity" SG_ 875 L_ATCU_Lib_StatMngr_ETC 0;
BA_REL_ "GenSigTimeoutTime" BU_SG_REL_ L_ATCU_vMON SG_ 875 L_ATCU_Lib_StatMngr_ETC 5000;
BA_ "Version" SG_ 875 L_ATCU_Lib_StatMngr_ETC "24.09.01";
BA_ "GenMsgSendType" BO_ 876 0;
BA_ "GenMsgCycleTime" BO_ 876 2000;
BA_ "Description" SG_ 876 L_ATCU_Lib_StatMngr_FuelEfficiency "This value only use for ATCU Library data monitoring (Only use before SOP)";
BA_ "GenSigSendType" SG_ 876 L_ATCU_Lib_StatMngr_FuelEfficiency 4;
BA_ "UserSigValidity" SG_ 876 L_ATCU_Lib_StatMngr_FuelEfficiency 0;
BA_REL_ "GenSigTimeoutTime" BU_SG_REL_ L_ATCU_vMON SG_ 876 L_ATCU_Lib_StatMngr_FuelEfficiency 5000;
BA_ "Version" SG_ 876 L_ATCU_Lib_StatMngr_FuelEfficiency "24.09.01";
BA_ "GenMsgSendType" BO_ 877 0;
BA_ "GenMsgCycleTime" BO_ 877 2000;
BA_ "Description" SG_ 877 L_ATCU_Lib_StatMngr_Snsr "This value only use for ATCU Library data monitoring (Only use before SOP)";
BA_ "GenSigSendType" SG_ 877 L_ATCU_Lib_StatMngr_Snsr 4;
BA_ "UserSigValidity" SG_ 877 L_ATCU_Lib_StatMngr_Snsr 0;
BA_REL_ "GenSigTimeoutTime" BU_SG_REL_ L_ATCU_vMON SG_ 877 L_ATCU_Lib_StatMngr_Snsr 5000;
BA_ "Version" SG_ 877 L_ATCU_Lib_StatMngr_Snsr "24.09.01";
BA_ "GenMsgSendType" BO_ 878 0;
BA_ "GenMsgCycleTime" BO_ 878 2000;
BA_ "Description" SG_ 878 L_ATCU_Lib_StatMngr_2ndHumid "This value only use for ATCU Library data monitoring (Only use before SOP)";
BA_ "GenSigSendType" SG_ 878 L_ATCU_Lib_StatMngr_2ndHumid 4;
BA_ "UserSigValidity" SG_ 878 L_ATCU_Lib_StatMngr_2ndHumid 0;
BA_REL_ "GenSigTimeoutTime" BU_SG_REL_ L_ATCU_vMON SG_ 878 L_ATCU_Lib_StatMngr_2ndHumid 5000;
BA_ "Version" SG_ 878 L_ATCU_Lib_StatMngr_2ndHumid "24.09.01";
BA_ "GenMsgSendType" BO_ 879 0;
BA_ "GenMsgCycleTime" BO_ 879 2000;
BA_ "Description" SG_ 879 L_ATCU_Lib_StatMngr_2ndTemp "This value only use for ATCU Library data monitoring (Only use before SOP)";
BA_ "GenSigSendType" SG_ 879 L_ATCU_Lib_StatMngr_2ndTemp 4;
BA_ "UserSigValidity" SG_ 879 L_ATCU_Lib_StatMngr_2ndTemp 0;
BA_REL_ "GenSigTimeoutTime" BU_SG_REL_ L_ATCU_vMON SG_ 879 L_ATCU_Lib_StatMngr_2ndTemp 5000;
BA_ "Version" SG_ 879 L_ATCU_Lib_StatMngr_2ndTemp "24.09.01";
BA_ "GenMsgSendType" BO_ 886 0;
BA_ "GenMsgCycleTime" BO_ 886 2000;
BA_ "Description" SG_ 886 L_ATCU_Lib_MEM_ROMWriteCnt "ATCU Memory ROM Write Count Data";
BA_ "GenSigSendType" SG_ 886 L_ATCU_Lib_MEM_ROMWriteCnt 4;
BA_ "UserSigValidity" SG_ 886 L_ATCU_Lib_MEM_ROMWriteCnt 0;
BA_REL_ "GenSigTimeoutTime" BU_SG_REL_ L_ATCU_vMON SG_ 886 L_ATCU_Lib_MEM_ROMWriteCnt 5000;
BA_ "Version" SG_ 886 L_ATCU_Lib_MEM_ROMWriteCnt "25.05.03";
BA_ "GenMsgSendType" BO_ 1025 0;
BA_ "GenMsgCycleTime" BO_ 1025 1000;
BA_ "Description" SG_ 1025 L_EVNT_HU_FrDrEVntSidePtDisp_X "Electric Vent Frt Driver Side Electric Vent Touch Range X Coordinate Display Feedback (To CTS)";
BA_ "GenSigSendType" SG_ 1025 L_EVNT_HU_FrDrEVntSidePtDisp_X 4;
BA_ "UserSigValidity" SG_ 1025 L_EVNT_HU_FrDrEVntSidePtDisp_X 7;
BA_REL_ "GenSigTimeoutTime" BU_SG_REL_ L_ATCU SG_ 1025 L_EVNT_HU_FrDrEVntSidePtDisp_X 5000;
BA_ "Version" SG_ 1025 L_EVNT_HU_FrDrEVntSidePtDisp_X "24.05.11";
BA_ "Description" SG_ 1025 L_EVNT_HU_FrDrEVntSidePtDisp_Y "Electric Vent Frt Driver Side Electric Vent Touch Range Y Coordinate Display Feedback (To CTS)";
BA_ "GenSigSendType" SG_ 1025 L_EVNT_HU_FrDrEVntSidePtDisp_Y 4;
BA_ "UserSigValidity" SG_ 1025 L_EVNT_HU_FrDrEVntSidePtDisp_Y 7;
BA_REL_ "GenSigTimeoutTime" BU_SG_REL_ L_ATCU SG_ 1025 L_EVNT_HU_FrDrEVntSidePtDisp_Y 5000;
BA_ "Version" SG_ 1025 L_EVNT_HU_FrDrEVntSidePtDisp_Y "24.05.11";
BA_ "Description" SG_ 1025 L_EVNT_HU_FrDrEVntCtrPtDisp_X "Electric Vent Frt Driver Center Electric Vent Touch Range X Coordinate Display Feedback (To CTS)";
BA_ "GenSigSendType" SG_ 1025 L_EVNT_HU_FrDrEVntCtrPtDisp_X 4;
BA_ "UserSigValidity" SG_ 1025 L_EVNT_HU_FrDrEVntCtrPtDisp_X 7;
BA_REL_ "GenSigTimeoutTime" BU_SG_REL_ L_ATCU SG_ 1025 L_EVNT_HU_FrDrEVntCtrPtDisp_X 5000;
BA_ "Version" SG_ 1025 L_EVNT_HU_FrDrEVntCtrPtDisp_X "24.05.11";
BA_ "Description" SG_ 1025 L_EVNT_HU_FrDrEVntCtrPtDisp_Y "Electric Vent Frt Driver Center Electric Vent Touch Range Y Coordinate Display Feedback (To CTS)";
BA_ "GenSigSendType" SG_ 1025 L_EVNT_HU_FrDrEVntCtrPtDisp_Y 4;
BA_ "UserSigValidity" SG_ 1025 L_EVNT_HU_FrDrEVntCtrPtDisp_Y 7;
BA_REL_ "GenSigTimeoutTime" BU_SG_REL_ L_ATCU SG_ 1025 L_EVNT_HU_FrDrEVntCtrPtDisp_Y 5000;
BA_ "Version" SG_ 1025 L_EVNT_HU_FrDrEVntCtrPtDisp_Y "24.05.11";
BA_ "GenMsgSendType" BO_ 1026 0;
BA_ "GenMsgCycleTime" BO_ 1026 1000;
BA_ "Description" SG_ 1026 L_EVNT_HU_FrPsEVntSidePtDisp_X "Electric Vent Frt Passenger Side Electric Vent Touch Range X Coordinate Display Feedback (To CTS)";
BA_ "GenSigSendType" SG_ 1026 L_EVNT_HU_FrPsEVntSidePtDisp_X 4;
BA_ "UserSigValidity" SG_ 1026 L_EVNT_HU_FrPsEVntSidePtDisp_X 7;
BA_REL_ "GenSigTimeoutTime" BU_SG_REL_ L_ATCU SG_ 1026 L_EVNT_HU_FrPsEVntSidePtDisp_X 5000;
BA_ "Version" SG_ 1026 L_EVNT_HU_FrPsEVntSidePtDisp_X "24.05.11";
BA_ "Description" SG_ 1026 L_EVNT_HU_FrPsEVntSidePtDisp_Y "Electric Vent Frt Passenger Side Electric Vent Touch Range Y Coordinate Display Feedback (To CTS)";
BA_ "GenSigSendType" SG_ 1026 L_EVNT_HU_FrPsEVntSidePtDisp_Y 4;
BA_ "UserSigValidity" SG_ 1026 L_EVNT_HU_FrPsEVntSidePtDisp_Y 7;
BA_REL_ "GenSigTimeoutTime" BU_SG_REL_ L_ATCU SG_ 1026 L_EVNT_HU_FrPsEVntSidePtDisp_Y 5000;
BA_ "Version" SG_ 1026 L_EVNT_HU_FrPsEVntSidePtDisp_Y "24.05.11";
BA_ "Description" SG_ 1026 L_EVNT_HU_FrPsEVntCtrPtDisp_X "Electric Vent Frt Passenger Center Electric Vent Touch Range X Coordinate Display Feedback (To CTS)";
BA_ "GenSigSendType" SG_ 1026 L_EVNT_HU_FrPsEVntCtrPtDisp_X 4;
BA_ "UserSigValidity" SG_ 1026 L_EVNT_HU_FrPsEVntCtrPtDisp_X 7;
BA_REL_ "GenSigTimeoutTime" BU_SG_REL_ L_ATCU SG_ 1026 L_EVNT_HU_FrPsEVntCtrPtDisp_X 5000;
BA_ "Version" SG_ 1026 L_EVNT_HU_FrPsEVntCtrPtDisp_X "24.05.11";
BA_ "Description" SG_ 1026 L_EVNT_HU_FrPsEVntCtrPtDisp_Y "Electric Vent Frt Passenger Center Electric Vent Touch Range Y Coordinate Display Feedback (To CTS)";
BA_ "GenSigSendType" SG_ 1026 L_EVNT_HU_FrPsEVntCtrPtDisp_Y 4;
BA_ "UserSigValidity" SG_ 1026 L_EVNT_HU_FrPsEVntCtrPtDisp_Y 7;
BA_REL_ "GenSigTimeoutTime" BU_SG_REL_ L_ATCU SG_ 1026 L_EVNT_HU_FrPsEVntCtrPtDisp_Y 5000;
BA_ "Version" SG_ 1026 L_EVNT_HU_FrPsEVntCtrPtDisp_Y "24.05.11";
BA_ "GenMsgSendType" BO_ 1027 0;
BA_ "GenMsgCycleTime" BO_ 1027 1000;
BA_ "Description" SG_ 1027 L_EVNT_HU_RrDrEVntConsPtDisp_X "Electric Vent Rear Driver Console Touch Range X Coordinate Display Feedback (To CTS)";
BA_ "GenSigSendType" SG_ 1027 L_EVNT_HU_RrDrEVntConsPtDisp_X 4;
BA_ "UserSigValidity" SG_ 1027 L_EVNT_HU_RrDrEVntConsPtDisp_X 7;
BA_REL_ "GenSigTimeoutTime" BU_SG_REL_ L_ATCU SG_ 1027 L_EVNT_HU_RrDrEVntConsPtDisp_X 5000;
BA_ "Version" SG_ 1027 L_EVNT_HU_RrDrEVntConsPtDisp_X "24.05.11";
BA_ "Description" SG_ 1027 L_EVNT_HU_RrDrEVntConsPtDisp_Y "Electric Vent Rear Driver Console Touch Range Y Coordinate Display Feedback (To CTS)";
BA_ "GenSigSendType" SG_ 1027 L_EVNT_HU_RrDrEVntConsPtDisp_Y 4;
BA_ "UserSigValidity" SG_ 1027 L_EVNT_HU_RrDrEVntConsPtDisp_Y 7;
BA_REL_ "GenSigTimeoutTime" BU_SG_REL_ L_ATCU SG_ 1027 L_EVNT_HU_RrDrEVntConsPtDisp_Y 5000;
BA_ "Version" SG_ 1027 L_EVNT_HU_RrDrEVntConsPtDisp_Y "24.05.11";
BA_ "Description" SG_ 1027 L_EVNT_HU_RrPsEVntConsPtDisp_X "Electric Vent Rear Passenger Console Touch Range X Coordinate Display Feedback (To CTS)";
BA_ "GenSigSendType" SG_ 1027 L_EVNT_HU_RrPsEVntConsPtDisp_X 4;
BA_ "UserSigValidity" SG_ 1027 L_EVNT_HU_RrPsEVntConsPtDisp_X 7;
BA_REL_ "GenSigTimeoutTime" BU_SG_REL_ L_ATCU SG_ 1027 L_EVNT_HU_RrPsEVntConsPtDisp_X 5000;
BA_ "Version" SG_ 1027 L_EVNT_HU_RrPsEVntConsPtDisp_X "24.05.11";
BA_ "Description" SG_ 1027 L_EVNT_HU_RrPsEVntConsPtDisp_Y "Electric Vent Rear Passenger Console Touch Range Y Coordinate Display Feedback (To CTS)";
BA_ "GenSigSendType" SG_ 1027 L_EVNT_HU_RrPsEVntConsPtDisp_Y 4;
BA_ "UserSigValidity" SG_ 1027 L_EVNT_HU_RrPsEVntConsPtDisp_Y 7;
BA_REL_ "GenSigTimeoutTime" BU_SG_REL_ L_ATCU SG_ 1027 L_EVNT_HU_RrPsEVntConsPtDisp_Y 5000;
BA_ "Version" SG_ 1027 L_EVNT_HU_RrPsEVntConsPtDisp_Y "24.05.11";
BA_ "Description" SG_ 1027 L_EVNT_FrDrEVntSideFlt "Front Driver Electric Vent Side Fault Status";
BA_ "GenSigSendType" SG_ 1027 L_EVNT_FrDrEVntSideFlt 4;
BA_ "UserSigValidity" SG_ 1027 L_EVNT_FrDrEVntSideFlt 7;
BA_REL_ "GenSigTimeoutTime" BU_SG_REL_ L_ATCU SG_ 1027 L_EVNT_FrDrEVntSideFlt 5000;
BA_ "Version" SG_ 1027 L_EVNT_FrDrEVntSideFlt "24.05.11";
BA_ "Description" SG_ 1027 L_EVNT_FrDrEVntCtrFlt "Front Driver Electric Vent Center Fault Status";
BA_ "GenSigSendType" SG_ 1027 L_EVNT_FrDrEVntCtrFlt 4;
BA_ "UserSigValidity" SG_ 1027 L_EVNT_FrDrEVntCtrFlt 7;
BA_REL_ "GenSigTimeoutTime" BU_SG_REL_ L_ATCU SG_ 1027 L_EVNT_FrDrEVntCtrFlt 5000;
BA_ "Version" SG_ 1027 L_EVNT_FrDrEVntCtrFlt "24.05.11";
BA_ "Description" SG_ 1027 L_EVNT_FrPsEVntSideFlt "Front Passenger Electric Vent Side Fault Status";
BA_ "GenSigSendType" SG_ 1027 L_EVNT_FrPsEVntSideFlt 4;
BA_ "UserSigValidity" SG_ 1027 L_EVNT_FrPsEVntSideFlt 7;
BA_REL_ "GenSigTimeoutTime" BU_SG_REL_ L_ATCU SG_ 1027 L_EVNT_FrPsEVntSideFlt 5000;
BA_ "Version" SG_ 1027 L_EVNT_FrPsEVntSideFlt "24.05.11";
BA_ "Description" SG_ 1027 L_EVNT_FrPsEVntCtrFlt "Front Passenger Electric Vent Center Fault Status";
BA_ "GenSigSendType" SG_ 1027 L_EVNT_FrPsEVntCtrFlt 4;
BA_ "UserSigValidity" SG_ 1027 L_EVNT_FrPsEVntCtrFlt 7;
BA_REL_ "GenSigTimeoutTime" BU_SG_REL_ L_ATCU SG_ 1027 L_EVNT_FrPsEVntCtrFlt 5000;
BA_ "Version" SG_ 1027 L_EVNT_FrPsEVntCtrFlt "24.05.11";
BA_ "Description" SG_ 1027 L_EVNT_RrDrEVntConsFlt "Front Rear (2nd) Driver Electric Vent Console Fault Status";
BA_ "GenSigSendType" SG_ 1027 L_EVNT_RrDrEVntConsFlt 4;
BA_ "UserSigValidity" SG_ 1027 L_EVNT_RrDrEVntConsFlt 7;
BA_REL_ "GenSigTimeoutTime" BU_SG_REL_ L_ATCU SG_ 1027 L_EVNT_RrDrEVntConsFlt 5000;
BA_ "Version" SG_ 1027 L_EVNT_RrDrEVntConsFlt "24.05.11";
BA_ "Description" SG_ 1027 L_EVNT_RrPsEVntConsFlt "Front Rear (2nd) Passenger Electric Vent Console Fault Status";
BA_ "GenSigSendType" SG_ 1027 L_EVNT_RrPsEVntConsFlt 4;
BA_ "UserSigValidity" SG_ 1027 L_EVNT_RrPsEVntConsFlt 7;
BA_REL_ "GenSigTimeoutTime" BU_SG_REL_ L_ATCU SG_ 1027 L_EVNT_RrPsEVntConsFlt 5000;
BA_ "Version" SG_ 1027 L_EVNT_RrPsEVntConsFlt "24.05.11";
BA_ "GenMsgSendType" BO_ 1028 0;
BA_ "GenMsgCycleTime" BO_ 1028 1000;
BA_ "Description" SG_ 1028 L_EVNT_FrDrEVntModeSet_Disp "Electric Vent Frt Driver Mode Signal Display Feedback";
BA_ "GenSigSendType" SG_ 1028 L_EVNT_FrDrEVntModeSet_Disp 4;
BA_ "UserSigValidity" SG_ 1028 L_EVNT_FrDrEVntModeSet_Disp 7;
BA_REL_ "GenSigTimeoutTime" BU_SG_REL_ L_ATCU SG_ 1028 L_EVNT_FrDrEVntModeSet_Disp 5000;
BA_ "Version" SG_ 1028 L_EVNT_FrDrEVntModeSet_Disp "25.04.02";
BA_ "Description" SG_ 1028 L_EVNT_RrPsEVntModeSet_Disp "Electric Vent Rear Passenger Mode Signal Display Feedback";
BA_ "GenSigSendType" SG_ 1028 L_EVNT_RrPsEVntModeSet_Disp 4;
BA_ "UserSigValidity" SG_ 1028 L_EVNT_RrPsEVntModeSet_Disp 7;
BA_REL_ "GenSigTimeoutTime" BU_SG_REL_ L_ATCU SG_ 1028 L_EVNT_RrPsEVntModeSet_Disp 5000;
BA_ "Version" SG_ 1028 L_EVNT_RrPsEVntModeSet_Disp "25.04.02";
BA_ "Description" SG_ 1028 L_EVNT_FrDrEVntSideOpnClsDisp "Electric Vent Frt Driver Side Vent Open/Close Signal Display Feedback";
BA_ "GenSigSendType" SG_ 1028 L_EVNT_FrDrEVntSideOpnClsDisp 4;
BA_ "UserSigValidity" SG_ 1028 L_EVNT_FrDrEVntSideOpnClsDisp 7;
BA_REL_ "GenSigTimeoutTime" BU_SG_REL_ L_ATCU SG_ 1028 L_EVNT_FrDrEVntSideOpnClsDisp 5000;
BA_ "Version" SG_ 1028 L_EVNT_FrDrEVntSideOpnClsDisp "24.05.11";
BA_ "Description" SG_ 1028 L_EVNT_FrDrEVntCtrOpnClsDisp "Electric Vent Frt Driver Center Vent Open/Close Signal Display Feedback";
BA_ "GenSigSendType" SG_ 1028 L_EVNT_FrDrEVntCtrOpnClsDisp 4;
BA_ "UserSigValidity" SG_ 1028 L_EVNT_FrDrEVntCtrOpnClsDisp 7;
BA_REL_ "GenSigTimeoutTime" BU_SG_REL_ L_ATCU SG_ 1028 L_EVNT_FrDrEVntCtrOpnClsDisp 5000;
BA_ "Version" SG_ 1028 L_EVNT_FrDrEVntCtrOpnClsDisp "24.05.11";
BA_ "Description" SG_ 1028 L_EVNT_FrPsEVntSideOpnClsDisp "Electric Vent Frt Passenger Side Vent Open/Close Signal Display Feedback";
BA_ "GenSigSendType" SG_ 1028 L_EVNT_FrPsEVntSideOpnClsDisp 4;
BA_ "UserSigValidity" SG_ 1028 L_EVNT_FrPsEVntSideOpnClsDisp 7;
BA_REL_ "GenSigTimeoutTime" BU_SG_REL_ L_ATCU SG_ 1028 L_EVNT_FrPsEVntSideOpnClsDisp 5000;
BA_ "Version" SG_ 1028 L_EVNT_FrPsEVntSideOpnClsDisp "24.05.11";
BA_ "Description" SG_ 1028 L_EVNT_FrPsEVntCtrOpnClsDisp "Electric Vent Frt Passenger Center Vent Open/Close Signal Display Feedback";
BA_ "GenSigSendType" SG_ 1028 L_EVNT_FrPsEVntCtrOpnClsDisp 4;
BA_ "UserSigValidity" SG_ 1028 L_EVNT_FrPsEVntCtrOpnClsDisp 7;
BA_REL_ "GenSigTimeoutTime" BU_SG_REL_ L_ATCU SG_ 1028 L_EVNT_FrPsEVntCtrOpnClsDisp 5000;
BA_ "Version" SG_ 1028 L_EVNT_FrPsEVntCtrOpnClsDisp "24.05.11";
BA_ "Description" SG_ 1028 L_EVNT_RrDrEVntConsOpnClsDisp "Electric Vent Rear Driver Console Vent Open/Close Signal Display Feedback";
BA_ "GenSigSendType" SG_ 1028 L_EVNT_RrDrEVntConsOpnClsDisp 4;
BA_ "UserSigValidity" SG_ 1028 L_EVNT_RrDrEVntConsOpnClsDisp 7;
BA_REL_ "GenSigTimeoutTime" BU_SG_REL_ L_ATCU SG_ 1028 L_EVNT_RrDrEVntConsOpnClsDisp 5000;
BA_ "Version" SG_ 1028 L_EVNT_RrDrEVntConsOpnClsDisp "24.05.11";
BA_ "Description" SG_ 1028 L_EVNT_RrPsEVntConsOpnClsDisp "Electric Vent Rear Passenger Console Vent Open/Close Signal Display Feedback";
BA_ "GenSigSendType" SG_ 1028 L_EVNT_RrPsEVntConsOpnClsDisp 4;
BA_ "UserSigValidity" SG_ 1028 L_EVNT_RrPsEVntConsOpnClsDisp 7;
BA_REL_ "GenSigTimeoutTime" BU_SG_REL_ L_ATCU SG_ 1028 L_EVNT_RrPsEVntConsOpnClsDisp 5000;
BA_ "Version" SG_ 1028 L_EVNT_RrPsEVntConsOpnClsDisp "24.05.11";
BA_ "Description" SG_ 1028 L_EVNT_EVntTouchInform_HU "Electric Vent touch available information to HU_MM (prevent input from CTS)";
BA_ "GenSigSendType" SG_ 1028 L_EVNT_EVntTouchInform_HU 4;
BA_ "UserSigValidity" SG_ 1028 L_EVNT_EVntTouchInform_HU 7;
BA_REL_ "GenSigTimeoutTime" BU_SG_REL_ L_ATCU SG_ 1028 L_EVNT_EVntTouchInform_HU 5000;
BA_ "Version" SG_ 1028 L_EVNT_EVntTouchInform_HU "24.05.11";
BA_ "Description" SG_ 1028 L_EVNT_EVntTouchInform_CTS "Electric Vent touch available information to CTS (prevent input from HU_MM)";
BA_ "GenSigSendType" SG_ 1028 L_EVNT_EVntTouchInform_CTS 4;
BA_ "UserSigValidity" SG_ 1028 L_EVNT_EVntTouchInform_CTS 7;
BA_REL_ "GenSigTimeoutTime" BU_SG_REL_ L_ATCU SG_ 1028 L_EVNT_EVntTouchInform_CTS 5000;
BA_ "Version" SG_ 1028 L_EVNT_EVntTouchInform_CTS "24.05.11";
BA_ "GenSigSendType" SG_ 1028 L_EVNT_FrtEvntFocusLvlSta 4;
BA_ "UserSigValidity" SG_ 1028 L_EVNT_FrtEvntFocusLvlSta 7;
BA_REL_ "GenSigTimeoutTime" BU_SG_REL_ L_ATCU SG_ 1028 L_EVNT_FrtEvntFocusLvlSta 5000;
BA_ "Version" SG_ 1028 L_EVNT_FrtEvntFocusLvlSta "25.05.04";
BA_ "GenSigSendType" SG_ 1028 L_EVNT_RrEvntFocusLvlSta 4;
BA_ "UserSigValidity" SG_ 1028 L_EVNT_RrEvntFocusLvlSta 7;
BA_REL_ "GenSigTimeoutTime" BU_SG_REL_ L_ATCU SG_ 1028 L_EVNT_RrEvntFocusLvlSta 5000;
BA_ "Version" SG_ 1028 L_EVNT_RrEvntFocusLvlSta "25.05.04";
BA_ "GenSigSendType" SG_ 1028 L_EVNT_DrVntOpt 4;
BA_ "UserSigValidity" SG_ 1028 L_EVNT_DrVntOpt 7;
BA_REL_ "GenSigTimeoutTime" BU_SG_REL_ L_ATCU SG_ 1028 L_EVNT_DrVntOpt 5000;
BA_ "Version" SG_ 1028 L_EVNT_DrVntOpt "25.06.00";
BA_ "Description" SG_ 1028 L_EVNT_FrPsEVntModeSet_Disp "Electric Vent Frt Passenger Mode Signal Display Feedback";
BA_ "GenSigSendType" SG_ 1028 L_EVNT_FrPsEVntModeSet_Disp 4;
BA_ "UserSigValidity" SG_ 1028 L_EVNT_FrPsEVntModeSet_Disp 7;
BA_REL_ "GenSigTimeoutTime" BU_SG_REL_ L_ATCU SG_ 1028 L_EVNT_FrPsEVntModeSet_Disp 5000;
BA_ "Version" SG_ 1028 L_EVNT_FrPsEVntModeSet_Disp "25.04.02";
BA_ "GenSigSendType" SG_ 1028 L_EVNT_AstVntOpt 4;
BA_ "UserSigValidity" SG_ 1028 L_EVNT_AstVntOpt 7;
BA_REL_ "GenSigTimeoutTime" BU_SG_REL_ L_ATCU SG_ 1028 L_EVNT_AstVntOpt 5000;
BA_ "Version" SG_ 1028 L_EVNT_AstVntOpt "25.06.00";
BA_ "GenSigSendType" SG_ 1028 L_EVNT_RrDrVntOpt 4;
BA_ "UserSigValidity" SG_ 1028 L_EVNT_RrDrVntOpt 7;
BA_REL_ "GenSigTimeoutTime" BU_SG_REL_ L_ATCU SG_ 1028 L_EVNT_RrDrVntOpt 5000;
BA_ "Version" SG_ 1028 L_EVNT_RrDrVntOpt "25.06.00";
BA_ "GenSigSendType" SG_ 1028 L_EVNT_RrAstVntOpt 4;
BA_ "UserSigValidity" SG_ 1028 L_EVNT_RrAstVntOpt 7;
BA_REL_ "GenSigTimeoutTime" BU_SG_REL_ L_ATCU SG_ 1028 L_EVNT_RrAstVntOpt 5000;
BA_ "Version" SG_ 1028 L_EVNT_RrAstVntOpt "25.06.00";
BA_ "Description" SG_ 1028 L_EVNT_EVntAutoFlowHardSwOpt "Main can option routing / EVntAutoAirFlowHotKeyOpt";
BA_ "GenSigSendType" SG_ 1028 L_EVNT_EVntAutoFlowHardSwOpt 4;
BA_ "UserSigValidity" SG_ 1028 L_EVNT_EVntAutoFlowHardSwOpt 7;
BA_REL_ "GenSigTimeoutTime" BU_SG_REL_ L_ATCU SG_ 1028 L_EVNT_EVntAutoFlowHardSwOpt 5000;
BA_ "Version" SG_ 1028 L_EVNT_EVntAutoFlowHardSwOpt "25.09.01";
BA_ "Description" SG_ 1028 L_EVNT_RrDrEVntModeSet_Disp "Electric Vent Rear Driver Mode Signal Display Feedback";
BA_ "GenSigSendType" SG_ 1028 L_EVNT_RrDrEVntModeSet_Disp 4;
BA_ "UserSigValidity" SG_ 1028 L_EVNT_RrDrEVntModeSet_Disp 7;
BA_REL_ "GenSigTimeoutTime" BU_SG_REL_ L_ATCU SG_ 1028 L_EVNT_RrDrEVntModeSet_Disp 5000;
BA_ "Version" SG_ 1028 L_EVNT_RrDrEVntModeSet_Disp "25.04.02";
BA_ "GenMsgSendType" BO_ 1029 0;
BA_ "GenMsgCycleTime" BO_ 1029 1000;
BA_ "Description" SG_ 1029 L_EVNT_CTS_FrDrEVntSidePtDisp_X "Electric Vent Frt Driver Side Electric Vent Touch Range X Coordinate Display Feedback (To CTS)";
BA_ "GenSigSendType" SG_ 1029 L_EVNT_CTS_FrDrEVntSidePtDisp_X 4;
BA_ "UserSigValidity" SG_ 1029 L_EVNT_CTS_FrDrEVntSidePtDisp_X 7;
BA_REL_ "GenSigTimeoutTime" BU_SG_REL_ L_ATCU SG_ 1029 L_EVNT_CTS_FrDrEVntSidePtDisp_X 5000;
BA_ "Version" SG_ 1029 L_EVNT_CTS_FrDrEVntSidePtDisp_X "24.05.11";
BA_ "Description" SG_ 1029 L_EVNT_CTS_FrDrEVntSidePtDisp_Y "Electric Vent Frt Driver Side Electric Vent Touch Range Y Coordinate Display Feedback (To CTS)";
BA_ "GenSigSendType" SG_ 1029 L_EVNT_CTS_FrDrEVntSidePtDisp_Y 4;
BA_ "UserSigValidity" SG_ 1029 L_EVNT_CTS_FrDrEVntSidePtDisp_Y 7;
BA_REL_ "GenSigTimeoutTime" BU_SG_REL_ L_ATCU SG_ 1029 L_EVNT_CTS_FrDrEVntSidePtDisp_Y 5000;
BA_ "Version" SG_ 1029 L_EVNT_CTS_FrDrEVntSidePtDisp_Y "24.05.11";
BA_ "Description" SG_ 1029 L_EVNT_CTS_FrDrEVntCtrPtDisp_X "Electric Vent Frt Driver Center Electric Vent Touch Range X Coordinate Display Feedback (To CTS)";
BA_ "GenSigSendType" SG_ 1029 L_EVNT_CTS_FrDrEVntCtrPtDisp_X 4;
BA_ "UserSigValidity" SG_ 1029 L_EVNT_CTS_FrDrEVntCtrPtDisp_X 7;
BA_REL_ "GenSigTimeoutTime" BU_SG_REL_ L_ATCU SG_ 1029 L_EVNT_CTS_FrDrEVntCtrPtDisp_X 5000;
BA_ "Version" SG_ 1029 L_EVNT_CTS_FrDrEVntCtrPtDisp_X "24.05.11";
BA_ "Description" SG_ 1029 L_EVNT_CTS_FrDrEVntCtrPtDisp_Y "Electric Vent Frt Driver Center Electric Vent Touch Range Y Coordinate Display Feedback (To CTS)";
BA_ "GenSigSendType" SG_ 1029 L_EVNT_CTS_FrDrEVntCtrPtDisp_Y 4;
BA_ "UserSigValidity" SG_ 1029 L_EVNT_CTS_FrDrEVntCtrPtDisp_Y 7;
BA_REL_ "GenSigTimeoutTime" BU_SG_REL_ L_ATCU SG_ 1029 L_EVNT_CTS_FrDrEVntCtrPtDisp_Y 5000;
BA_ "Version" SG_ 1029 L_EVNT_CTS_FrDrEVntCtrPtDisp_Y "24.05.11";
BA_ "GenMsgSendType" BO_ 1030 0;
BA_ "GenMsgCycleTime" BO_ 1030 1000;
BA_ "Description" SG_ 1030 L_EVNT_CTS_FrPsEVntSidePtDisp_X "Electric Vent Frt Passenger Side Electric Vent Touch Range X Coordinate Display Feedback (To CTS)";
BA_ "GenSigSendType" SG_ 1030 L_EVNT_CTS_FrPsEVntSidePtDisp_X 4;
BA_ "UserSigValidity" SG_ 1030 L_EVNT_CTS_FrPsEVntSidePtDisp_X 7;
BA_REL_ "GenSigTimeoutTime" BU_SG_REL_ L_ATCU SG_ 1030 L_EVNT_CTS_FrPsEVntSidePtDisp_X 5000;
BA_ "Version" SG_ 1030 L_EVNT_CTS_FrPsEVntSidePtDisp_X "24.05.11";
BA_ "Description" SG_ 1030 L_EVNT_CTS_FrPsEVntSidePtDisp_Y "Electric Vent Frt Passenger Side Electric Vent Touch Range Y Coordinate Display Feedback (To CTS)";
BA_ "GenSigSendType" SG_ 1030 L_EVNT_CTS_FrPsEVntSidePtDisp_Y 4;
BA_ "UserSigValidity" SG_ 1030 L_EVNT_CTS_FrPsEVntSidePtDisp_Y 7;
BA_REL_ "GenSigTimeoutTime" BU_SG_REL_ L_ATCU SG_ 1030 L_EVNT_CTS_FrPsEVntSidePtDisp_Y 5000;
BA_ "Version" SG_ 1030 L_EVNT_CTS_FrPsEVntSidePtDisp_Y "24.05.11";
BA_ "Description" SG_ 1030 L_EVNT_CTS_FrPsEVntCtrPtDisp_X "Electric Vent Frt Passenger Center Electric Vent Touch Range X Coordinate Display Feedback (To CTS)";
BA_ "GenSigSendType" SG_ 1030 L_EVNT_CTS_FrPsEVntCtrPtDisp_X 4;
BA_ "UserSigValidity" SG_ 1030 L_EVNT_CTS_FrPsEVntCtrPtDisp_X 7;
BA_REL_ "GenSigTimeoutTime" BU_SG_REL_ L_ATCU SG_ 1030 L_EVNT_CTS_FrPsEVntCtrPtDisp_X 5000;
BA_ "Version" SG_ 1030 L_EVNT_CTS_FrPsEVntCtrPtDisp_X "24.05.11";
BA_ "Description" SG_ 1030 L_EVNT_CTS_FrPsEVntCtrPtDisp_Y "Electric Vent Frt Passenger Center Electric Vent Touch Range Y Coordinate Display Feedback (To CTS)";
BA_ "GenSigSendType" SG_ 1030 L_EVNT_CTS_FrPsEVntCtrPtDisp_Y 4;
BA_ "UserSigValidity" SG_ 1030 L_EVNT_CTS_FrPsEVntCtrPtDisp_Y 7;
BA_REL_ "GenSigTimeoutTime" BU_SG_REL_ L_ATCU SG_ 1030 L_EVNT_CTS_FrPsEVntCtrPtDisp_Y 5000;
BA_ "Version" SG_ 1030 L_EVNT_CTS_FrPsEVntCtrPtDisp_Y "24.05.11";
BA_ "GenMsgSendType" BO_ 1031 0;
BA_ "GenMsgCycleTime" BO_ 1031 1000;
BA_ "Description" SG_ 1031 L_EVNT_CTS_RrDrEVntConsPtDisp_X "Electric Vent Rear Driver Console Touch Range X Coordinate Display Feedback (To CTS)";
BA_ "GenSigSendType" SG_ 1031 L_EVNT_CTS_RrDrEVntConsPtDisp_X 4;
BA_ "UserSigValidity" SG_ 1031 L_EVNT_CTS_RrDrEVntConsPtDisp_X 7;
BA_REL_ "GenSigTimeoutTime" BU_SG_REL_ L_ATCU SG_ 1031 L_EVNT_CTS_RrDrEVntConsPtDisp_X 5000;
BA_ "Version" SG_ 1031 L_EVNT_CTS_RrDrEVntConsPtDisp_X "24.05.11";
BA_ "Description" SG_ 1031 L_EVNT_CTS_RrDrEVntConsPtDisp_Y "Electric Vent Rear Driver Console Touch Range Y Coordinate Display Feedback (To CTS)";
BA_ "GenSigSendType" SG_ 1031 L_EVNT_CTS_RrDrEVntConsPtDisp_Y 4;
BA_ "UserSigValidity" SG_ 1031 L_EVNT_CTS_RrDrEVntConsPtDisp_Y 7;
BA_REL_ "GenSigTimeoutTime" BU_SG_REL_ L_ATCU SG_ 1031 L_EVNT_CTS_RrDrEVntConsPtDisp_Y 5000;
BA_ "Version" SG_ 1031 L_EVNT_CTS_RrDrEVntConsPtDisp_Y "24.05.11";
BA_ "Description" SG_ 1031 L_EVNT_CTS_RrPsEVntConsPtDisp_X "Electric Vent Rear Passenger Console Touch Range X Coordinate Display Feedback (To CTS)";
BA_ "GenSigSendType" SG_ 1031 L_EVNT_CTS_RrPsEVntConsPtDisp_X 4;
BA_ "UserSigValidity" SG_ 1031 L_EVNT_CTS_RrPsEVntConsPtDisp_X 7;
BA_REL_ "GenSigTimeoutTime" BU_SG_REL_ L_ATCU SG_ 1031 L_EVNT_CTS_RrPsEVntConsPtDisp_X 5000;
BA_ "Version" SG_ 1031 L_EVNT_CTS_RrPsEVntConsPtDisp_X "24.05.11";
BA_ "Description" SG_ 1031 L_EVNT_CTS_RrPsEVntConsPtDisp_Y "Electric Vent Rear Passenger Console Touch Range Y Coordinate Display Feedback (To CTS)";
BA_ "GenSigSendType" SG_ 1031 L_EVNT_CTS_RrPsEVntConsPtDisp_Y 4;
BA_ "UserSigValidity" SG_ 1031 L_EVNT_CTS_RrPsEVntConsPtDisp_Y 7;
BA_REL_ "GenSigTimeoutTime" BU_SG_REL_ L_ATCU SG_ 1031 L_EVNT_CTS_RrPsEVntConsPtDisp_Y 5000;
BA_ "Version" SG_ 1031 L_EVNT_CTS_RrPsEVntConsPtDisp_Y "24.05.11";
BA_ "GenMsgCycleTime" BO_ 1040 0;
BA_ "GenSigSendType" SG_ 1040 L_EVNT_FrDrEVntAutoFlowOSDReq 4;
BA_ "UserSigValidity" SG_ 1040 L_EVNT_FrDrEVntAutoFlowOSDReq 7;
BA_REL_ "GenSigTimeoutTime" BU_SG_REL_ L_ATCU SG_ 1040 L_EVNT_FrDrEVntAutoFlowOSDReq 0;
BA_ "Version" SG_ 1040 L_EVNT_FrDrEVntAutoFlowOSDReq "25.09.01";
BA_ "GenSigSendType" SG_ 1040 L_EVNT_FrAstEVntAutoFlowOSDReq 4;
BA_ "UserSigValidity" SG_ 1040 L_EVNT_FrAstEVntAutoFlowOSDReq 7;
BA_REL_ "GenSigTimeoutTime" BU_SG_REL_ L_ATCU SG_ 1040 L_EVNT_FrAstEVntAutoFlowOSDReq 0;
BA_ "Version" SG_ 1040 L_EVNT_FrAstEVntAutoFlowOSDReq "25.09.01";
BA_ "GenMsgSendType" BO_ 320 0;
BA_ "GenMsgCycleTime" BO_ 320 20;
BA_ "GenMsgCycleTimeFast" BO_ 320 0;
BA_ "GenMsgNrOfRepetition" BO_ 320 0;
BA_ "GenMsgDelayTime" BO_ 320 0;
BA_ "UserSigValidity" SG_ 320 FHPTC_DrRdySta 7;
BA_ "Version" SG_ 320 FHPTC_DrRdySta "23.08.08";
BA_ "UserSigValidity" SG_ 320 FHPTC_DrOpSta 7;
BA_ "Version" SG_ 320 FHPTC_DrOpSta "23.08.08";
BA_ "UserSigValidity" SG_ 320 FHPTC_DrCnsmptPwr_W 7;
BA_ "Version" SG_ 320 FHPTC_DrCnsmptPwr_W "23.08.08";
BA_ "UserSigValidity" SG_ 320 FHPTC_DrCurrent_A 7;
BA_ "Version" SG_ 320 FHPTC_DrCurrent_A "23.08.08";
BA_ "UserSigValidity" SG_ 320 FHPTC_DrCoreTemp_C 7;
BA_ "Version" SG_ 320 FHPTC_DrCoreTemp_C "23.08.08";
BA_ "Description" SG_ 320 FHPTC_DrDutyFB_Pec "Duty Conversion to PTC Consumption power value, 40w~6kw -> 10%~95%";
BA_ "UserSigValidity" SG_ 320 FHPTC_DrDutyFB_Pec 7;
BA_ "Version" SG_ 320 FHPTC_DrDutyFB_Pec "23.08.08";
BA_ "Description" SG_ 320 FHPTC_DrDutyFB_IGBT "PWM DUTY of PTC IGBT (0~100%)";
BA_ "UserSigValidity" SG_ 320 FHPTC_DrDutyFB_IGBT 7;
BA_ "Version" SG_ 320 FHPTC_DrDutyFB_IGBT "23.08.08";
BA_ "UserSigValidity" SG_ 320 FHPTC_DrCtrlTyp 7;
BA_ "Version" SG_ 320 FHPTC_DrCtrlTyp "23.08.08";
BA_ "UserSigValidity" SG_ 320 FHPTC_DrVoltage_V 7;
BA_ "Version" SG_ 320 FHPTC_DrVoltage_V "23.08.08";
BA_ "GenMsgSendType" BO_ 321 0;
BA_ "GenMsgCycleTime" BO_ 321 20;
BA_ "GenMsgCycleTimeFast" BO_ 321 0;
BA_ "GenMsgNrOfRepetition" BO_ 321 0;
BA_ "GenMsgDelayTime" BO_ 321 0;
BA_ "UserSigValidity" SG_ 321 FHPTC_DrFlt 7;
BA_ "Version" SG_ 321 FHPTC_DrFlt "23.08.08";
BA_ "UserSigValidity" SG_ 321 FHPTC_DrFltLVLow 7;
BA_ "Version" SG_ 321 FHPTC_DrFltLVLow "23.08.08";
BA_ "UserSigValidity" SG_ 321 FHPTC_DrFailLVSnr 7;
BA_ "Version" SG_ 321 FHPTC_DrFailLVSnr "23.08.08";
BA_ "UserSigValidity" SG_ 321 FHPTC_DrFailCurrentSnr 7;
BA_ "Version" SG_ 321 FHPTC_DrFailCurrentSnr "23.08.08";
BA_ "UserSigValidity" SG_ 321 FHPTC_DrFailCoreTempSnr 7;
BA_ "Version" SG_ 321 FHPTC_DrFailCoreTempSnr "23.08.08";
BA_ "UserSigValidity" SG_ 321 FHPTC_DrFailPcbTempSnr 7;
BA_ "Version" SG_ 321 FHPTC_DrFailPcbTempSnr "23.08.08";
BA_ "UserSigValidity" SG_ 321 FHPTC_DrFailIGBT 7;
BA_ "Version" SG_ 321 FHPTC_DrFailIGBT "23.08.08";
BA_ "UserSigValidity" SG_ 321 FHPTC_DrFailOpenLoad 7;
BA_ "Version" SG_ 321 FHPTC_DrFailOpenLoad "23.08.08";
BA_ "UserSigValidity" SG_ 321 FHPTC_DrLtdOpCause 7;
BA_ "Version" SG_ 321 FHPTC_DrLtdOpCause "23.08.08";
BA_ "UserSigValidity" SG_ 321 FHPTC_DrFltLVHigh 7;
BA_ "Version" SG_ 321 FHPTC_DrFltLVHigh "23.08.08";
BA_ "UserSigValidity" SG_ 321 FHPTC_DrSwVer 7;
BA_ "Version" SG_ 321 FHPTC_DrSwVer "23.08.08";
BA_ "UserSigValidity" SG_ 321 FHPTC_DrFltHVLow 7;
BA_ "Version" SG_ 321 FHPTC_DrFltHVLow "23.08.08";
BA_ "Description" SG_ 321 FHPTC_CnsmptPwrTtl_W "Total Power Consumption Value = FHPTC_DrConsumptionPower_W + FHPTC_PassConsumptionPower_W";
BA_ "UserSigValidity" SG_ 321 FHPTC_CnsmptPwrTtl_W 7;
BA_ "Version" SG_ 321 FHPTC_CnsmptPwrTtl_W "23.08.08";
BA_ "UserSigValidity" SG_ 321 FHPTC_DrFltHVHigh 7;
BA_ "Version" SG_ 321 FHPTC_DrFltHVHigh "23.08.08";
BA_ "GenSigStartValue" SG_ 321 FHPTC_IntlkSta 2;
BA_ "UserSigValidity" SG_ 321 FHPTC_IntlkSta 7;
BA_ "Version" SG_ 321 FHPTC_IntlkSta "25.06.01";
BA_ "UserSigValidity" SG_ 321 FHPTC_DrFltOverCurrent 7;
BA_ "Version" SG_ 321 FHPTC_DrFltOverCurrent "23.08.08";
BA_ "UserSigValidity" SG_ 321 FHPTC_DrFltThermalShutDn 7;
BA_ "Version" SG_ 321 FHPTC_DrFltThermalShutDn "23.08.08";
BA_ "UserSigValidity" SG_ 321 FHPTC_DrFltPcbThermalShutDn 7;
BA_ "Version" SG_ 321 FHPTC_DrFltPcbThermalShutDn "23.08.08";
BA_ "UserSigValidity" SG_ 321 FHPTC_DrFltMsgTmOutATCU 7;
BA_ "Version" SG_ 321 FHPTC_DrFltMsgTmOutATCU "23.08.08";
BA_ "UserSigValidity" SG_ 321 FHPTC_DrFailHVSnr 7;
BA_ "Version" SG_ 321 FHPTC_DrFailHVSnr "23.08.08";
BA_ "GenMsgSendType" BO_ 322 0;
BA_ "GenMsgCycleTime" BO_ 322 20;
BA_ "GenMsgCycleTimeFast" BO_ 322 0;
BA_ "GenMsgNrOfRepetition" BO_ 322 0;
BA_ "GenMsgDelayTime" BO_ 322 0;
BA_ "UserSigValidity" SG_ 322 FHPTC_PassRdySta 7;
BA_ "Version" SG_ 322 FHPTC_PassRdySta "23.08.08";
BA_ "UserSigValidity" SG_ 322 FHPTC_PassOpSta 7;
BA_ "Version" SG_ 322 FHPTC_PassOpSta "23.08.08";
BA_ "UserSigValidity" SG_ 322 FHPTC_PassCnsmptPwr_W 7;
BA_ "Version" SG_ 322 FHPTC_PassCnsmptPwr_W "23.08.08";
BA_ "UserSigValidity" SG_ 322 FHPTC_PassCtrlTyp 7;
BA_ "Version" SG_ 322 FHPTC_PassCtrlTyp "23.08.08";
BA_ "UserSigValidity" SG_ 322 FHPTC_PassVoltage_V 7;
BA_ "Version" SG_ 322 FHPTC_PassVoltage_V "23.08.08";
BA_ "UserSigValidity" SG_ 322 FHPTC_PassCurrent_A 7;
BA_ "Version" SG_ 322 FHPTC_PassCurrent_A "23.08.08";
BA_ "Description" SG_ 322 FHPTC_PassDutyFB_Pec "Duty Conversion to PTC Consumption power value, 40w~6kw -> 10%~95%";
BA_ "UserSigValidity" SG_ 322 FHPTC_PassDutyFB_Pec 7;
BA_ "Version" SG_ 322 FHPTC_PassDutyFB_Pec "23.08.08";
BA_ "Description" SG_ 322 FHPTC_PassDutyFB_IGBT "PWM DUTY of PTC IGBT (0~100%)";
BA_ "UserSigValidity" SG_ 322 FHPTC_PassDutyFB_IGBT 7;
BA_ "Version" SG_ 322 FHPTC_PassDutyFB_IGBT "23.08.08";
BA_ "UserSigValidity" SG_ 322 FHPTC_PassCoreTemp_C 7;
BA_ "Version" SG_ 322 FHPTC_PassCoreTemp_C "23.08.08";
BA_ "GenMsgSendType" BO_ 323 0;
BA_ "GenMsgCycleTime" BO_ 323 20;
BA_ "GenMsgCycleTimeFast" BO_ 323 0;
BA_ "GenMsgNrOfRepetition" BO_ 323 0;
BA_ "GenMsgDelayTime" BO_ 323 0;
BA_ "UserSigValidity" SG_ 323 FHPTC_PassFlt 7;
BA_ "Version" SG_ 323 FHPTC_PassFlt "23.08.08";
BA_ "UserSigValidity" SG_ 323 FHPTC_PassFltLVLow 7;
BA_ "Version" SG_ 323 FHPTC_PassFltLVLow "23.08.08";
BA_ "UserSigValidity" SG_ 323 FHPTC_PassFailLVSnr 7;
BA_ "Version" SG_ 323 FHPTC_PassFailLVSnr "23.08.08";
BA_ "UserSigValidity" SG_ 323 FHPTC_PassFailCurrentSnr 7;
BA_ "Version" SG_ 323 FHPTC_PassFailCurrentSnr "23.08.08";
BA_ "UserSigValidity" SG_ 323 FHPTC_PassFailCoreTempSnr 7;
BA_ "Version" SG_ 323 FHPTC_PassFailCoreTempSnr "23.08.08";
BA_ "UserSigValidity" SG_ 323 FHPTC_PassFailPcbTempSnr 7;
BA_ "Version" SG_ 323 FHPTC_PassFailPcbTempSnr "23.08.08";
BA_ "UserSigValidity" SG_ 323 FHPTC_PassFailIGBT 7;
BA_ "Version" SG_ 323 FHPTC_PassFailIGBT "23.08.08";
BA_ "UserSigValidity" SG_ 323 FHPTC_PassFailOpenLoad 7;
BA_ "Version" SG_ 323 FHPTC_PassFailOpenLoad "23.08.08";
BA_ "UserSigValidity" SG_ 323 FHPTC_PassLtdOpCause 7;
BA_ "Version" SG_ 323 FHPTC_PassLtdOpCause "23.08.08";
BA_ "UserSigValidity" SG_ 323 FHPTC_PassFltLVHigh 7;
BA_ "Version" SG_ 323 FHPTC_PassFltLVHigh "23.08.08";
BA_ "UserSigValidity" SG_ 323 FHPTC_PassSwVer 7;
BA_ "Version" SG_ 323 FHPTC_PassSwVer "23.08.08";
BA_ "UserSigValidity" SG_ 323 FHPTC_PassFltHVLow 7;
BA_ "Version" SG_ 323 FHPTC_PassFltHVLow "23.08.08";
BA_ "UserSigValidity" SG_ 323 FHPTC_PassFltHVHigh 7;
BA_ "Version" SG_ 323 FHPTC_PassFltHVHigh "23.08.08";
BA_ "UserSigValidity" SG_ 323 FHPTC_PassFltOverCurrent 7;
BA_ "Version" SG_ 323 FHPTC_PassFltOverCurrent "23.08.08";
BA_ "UserSigValidity" SG_ 323 FHPTC_PassFltThermalShutDn 7;
BA_ "Version" SG_ 323 FHPTC_PassFltThermalShutDn "23.08.08";
BA_ "UserSigValidity" SG_ 323 FHPTC_PassFltPcbThermalShutDn 7;
BA_ "Version" SG_ 323 FHPTC_PassFltPcbThermalShutDn "23.08.08";
BA_ "UserSigValidity" SG_ 323 FHPTC_PassFltMsgTmOutATCU 7;
BA_ "Version" SG_ 323 FHPTC_PassFltMsgTmOutATCU "23.08.08";
BA_ "UserSigValidity" SG_ 323 FHPTC_PassFailHVSnr 7;
BA_ "Version" SG_ 323 FHPTC_PassFailHVSnr "23.08.08";
BA_ "GenMsgSendType" BO_ 324 0;
BA_ "GenMsgCycleTime" BO_ 324 20;
BA_ "GenMsgCycleTimeFast" BO_ 324 0;
BA_ "GenMsgNrOfRepetition" BO_ 324 0;
BA_ "GenMsgDelayTime" BO_ 324 0;
BA_ "UserSigValidity" SG_ 324 FHPTC_2ndDrRdySta 7;
BA_ "Version" SG_ 324 FHPTC_2ndDrRdySta "24.02.06";
BA_ "UserSigValidity" SG_ 324 FHPTC_2ndDrOpSta 7;
BA_ "Version" SG_ 324 FHPTC_2ndDrOpSta "24.02.06";
BA_ "UserSigValidity" SG_ 324 FHPTC_2ndDrCnsmptPwr_W 7;
BA_ "Version" SG_ 324 FHPTC_2ndDrCnsmptPwr_W "24.02.06";
BA_ "UserSigValidity" SG_ 324 FHPTC_2ndDrCurrent_A 7;
BA_ "Version" SG_ 324 FHPTC_2ndDrCurrent_A "24.02.06";
BA_ "UserSigValidity" SG_ 324 FHPTC_2ndDrCoreTemp_C 7;
BA_ "Version" SG_ 324 FHPTC_2ndDrCoreTemp_C "24.02.06";
BA_ "Description" SG_ 324 FHPTC_2ndDrDutyFB_Pec "Duty Conversion to PTC Consumption power value, 40w~6kw -> 10%~95%";
BA_ "UserSigValidity" SG_ 324 FHPTC_2ndDrDutyFB_Pec 7;
BA_ "Version" SG_ 324 FHPTC_2ndDrDutyFB_Pec "24.02.06";
BA_ "Description" SG_ 324 FHPTC_2ndDrDutyFB_IGBT "PWM DUTY of PTC IGBT (0~100%)";
BA_ "UserSigValidity" SG_ 324 FHPTC_2ndDrDutyFB_IGBT 7;
BA_ "Version" SG_ 324 FHPTC_2ndDrDutyFB_IGBT "24.02.06";
BA_ "UserSigValidity" SG_ 324 FHPTC_2ndDrCtrlTyp 7;
BA_ "Version" SG_ 324 FHPTC_2ndDrCtrlTyp "24.02.06";
BA_ "UserSigValidity" SG_ 324 FHPTC_2ndDrVoltage_V 7;
BA_ "Version" SG_ 324 FHPTC_2ndDrVoltage_V "24.02.06";
BA_ "GenMsgSendType" BO_ 325 0;
BA_ "GenMsgCycleTime" BO_ 325 20;
BA_ "GenMsgCycleTimeFast" BO_ 325 0;
BA_ "GenMsgNrOfRepetition" BO_ 325 0;
BA_ "GenMsgDelayTime" BO_ 325 0;
BA_ "UserSigValidity" SG_ 325 FHPTC_2ndDrFlt 7;
BA_ "Version" SG_ 325 FHPTC_2ndDrFlt "24.02.06";
BA_ "UserSigValidity" SG_ 325 FHPTC_2ndDrFltLVLow 7;
BA_ "Version" SG_ 325 FHPTC_2ndDrFltLVLow "24.02.06";
BA_ "UserSigValidity" SG_ 325 FHPTC_2ndDrFailLVSnr 7;
BA_ "Version" SG_ 325 FHPTC_2ndDrFailLVSnr "24.02.06";
BA_ "UserSigValidity" SG_ 325 FHPTC_2ndDrFailCurrentSnr 7;
BA_ "Version" SG_ 325 FHPTC_2ndDrFailCurrentSnr "24.02.06";
BA_ "UserSigValidity" SG_ 325 FHPTC_2ndDrFailCoreTempSnr 7;
BA_ "Version" SG_ 325 FHPTC_2ndDrFailCoreTempSnr "24.02.06";
BA_ "UserSigValidity" SG_ 325 FHPTC_2ndDrFailPcbTempSnr 7;
BA_ "Version" SG_ 325 FHPTC_2ndDrFailPcbTempSnr "24.02.06";
BA_ "UserSigValidity" SG_ 325 FHPTC_2ndDrFailIGBT 7;
BA_ "Version" SG_ 325 FHPTC_2ndDrFailIGBT "24.02.06";
BA_ "UserSigValidity" SG_ 325 FHPTC_2ndDrFailOpenLoad 7;
BA_ "Version" SG_ 325 FHPTC_2ndDrFailOpenLoad "24.02.06";
BA_ "UserSigValidity" SG_ 325 FHPTC_2ndDrLtdOpCause 7;
BA_ "Version" SG_ 325 FHPTC_2ndDrLtdOpCause "24.02.06";
BA_ "UserSigValidity" SG_ 325 FHPTC_2ndDrFltLVHigh 7;
BA_ "Version" SG_ 325 FHPTC_2ndDrFltLVHigh "24.02.06";
BA_ "UserSigValidity" SG_ 325 FHPTC_2ndDrSwVer 7;
BA_ "Version" SG_ 325 FHPTC_2ndDrSwVer "24.02.06";
BA_ "UserSigValidity" SG_ 325 FHPTC_2ndDrFltHVLow 7;
BA_ "Version" SG_ 325 FHPTC_2ndDrFltHVLow "24.02.06";
BA_ "UserSigValidity" SG_ 325 FHPTC_2ndDrFltHVHigh 7;
BA_ "Version" SG_ 325 FHPTC_2ndDrFltHVHigh "24.02.06";
BA_ "UserSigValidity" SG_ 325 FHPTC_2ndDrFltOverCurrent 7;
BA_ "Version" SG_ 325 FHPTC_2ndDrFltOverCurrent "24.02.06";
BA_ "UserSigValidity" SG_ 325 FHPTC_2ndDrFltThermalShutDn 7;
BA_ "Version" SG_ 325 FHPTC_2ndDrFltThermalShutDn "24.02.06";
BA_ "UserSigValidity" SG_ 325 FHPTC_2ndDrFltPcbThermalShutDn 7;
BA_ "Version" SG_ 325 FHPTC_2ndDrFltPcbThermalShutDn "24.02.06";
BA_ "UserSigValidity" SG_ 325 FHPTC_2ndDrFltMsgTmOutATCU 7;
BA_ "Version" SG_ 325 FHPTC_2ndDrFltMsgTmOutATCU "24.02.06";
BA_ "UserSigValidity" SG_ 325 FHPTC_2ndDrFailHVSnr 7;
BA_ "Version" SG_ 325 FHPTC_2ndDrFailHVSnr "24.02.06";
BA_ "GenMsgSendType" BO_ 326 0;
BA_ "GenMsgCycleTime" BO_ 326 20;
BA_ "GenMsgCycleTimeFast" BO_ 326 0;
BA_ "GenMsgNrOfRepetition" BO_ 326 0;
BA_ "GenMsgDelayTime" BO_ 326 0;
BA_ "UserSigValidity" SG_ 326 FHPTC_2ndPsRdySta 7;
BA_ "Version" SG_ 326 FHPTC_2ndPsRdySta "24.02.06";
BA_ "UserSigValidity" SG_ 326 FHPTC_2ndPsOpSta 7;
BA_ "Version" SG_ 326 FHPTC_2ndPsOpSta "24.02.06";
BA_ "UserSigValidity" SG_ 326 FHPTC_2ndPsCnsmptPwr_W 7;
BA_ "Version" SG_ 326 FHPTC_2ndPsCnsmptPwr_W "24.02.06";
BA_ "UserSigValidity" SG_ 326 FHPTC_2ndPsCtrlTyp 7;
BA_ "Version" SG_ 326 FHPTC_2ndPsCtrlTyp "24.02.06";
BA_ "UserSigValidity" SG_ 326 FHPTC_2ndPsVoltage_V 7;
BA_ "Version" SG_ 326 FHPTC_2ndPsVoltage_V "24.02.06";
BA_ "UserSigValidity" SG_ 326 FHPTC_2ndPsCurrent_A 7;
BA_ "Version" SG_ 326 FHPTC_2ndPsCurrent_A "24.02.06";
BA_ "Description" SG_ 326 FHPTC_2ndPsDutyFB_Pec "Duty Conversion to PTC Consumption power value, 40w~6kw -> 10%~95%";
BA_ "UserSigValidity" SG_ 326 FHPTC_2ndPsDutyFB_Pec 7;
BA_ "Version" SG_ 326 FHPTC_2ndPsDutyFB_Pec "24.02.06";
BA_ "Description" SG_ 326 FHPTC_2ndPsDutyFB_IGBT "PWM DUTY of PTC IGBT (0~100%)";
BA_ "UserSigValidity" SG_ 326 FHPTC_2ndPsDutyFB_IGBT 7;
BA_ "Version" SG_ 326 FHPTC_2ndPsDutyFB_IGBT "24.02.06";
BA_ "UserSigValidity" SG_ 326 FHPTC_2ndPsCoreTemp_C 7;
BA_ "Version" SG_ 326 FHPTC_2ndPsCoreTemp_C "24.02.06";
BA_ "GenMsgSendType" BO_ 327 0;
BA_ "GenMsgCycleTime" BO_ 327 20;
BA_ "GenMsgCycleTimeFast" BO_ 327 0;
BA_ "GenMsgNrOfRepetition" BO_ 327 0;
BA_ "GenMsgDelayTime" BO_ 327 0;
BA_ "UserSigValidity" SG_ 327 FHPTC_2ndPsFlt 7;
BA_ "Version" SG_ 327 FHPTC_2ndPsFlt "24.02.06";
BA_ "UserSigValidity" SG_ 327 FHPTC_2ndPsFltLVLow 7;
BA_ "Version" SG_ 327 FHPTC_2ndPsFltLVLow "24.02.06";
BA_ "UserSigValidity" SG_ 327 FHPTC_2ndPsFailLVSnr 7;
BA_ "Version" SG_ 327 FHPTC_2ndPsFailLVSnr "24.02.06";
BA_ "UserSigValidity" SG_ 327 FHPTC_2ndPsFailCurrentSnr 7;
BA_ "Version" SG_ 327 FHPTC_2ndPsFailCurrentSnr "24.02.06";
BA_ "UserSigValidity" SG_ 327 FHPTC_2ndPsFailCoreTempSnr 7;
BA_ "Version" SG_ 327 FHPTC_2ndPsFailCoreTempSnr "24.02.06";
BA_ "UserSigValidity" SG_ 327 FHPTC_2ndPsFailPcbTempSnr 7;
BA_ "Version" SG_ 327 FHPTC_2ndPsFailPcbTempSnr "24.02.06";
BA_ "UserSigValidity" SG_ 327 FHPTC_2ndPsFailIGBT 7;
BA_ "Version" SG_ 327 FHPTC_2ndPsFailIGBT "24.02.06";
BA_ "UserSigValidity" SG_ 327 FHPTC_2ndPsFailOpenLoad 7;
BA_ "Version" SG_ 327 FHPTC_2ndPsFailOpenLoad "24.02.06";
BA_ "UserSigValidity" SG_ 327 FHPTC_2ndPsLtdOpCause 7;
BA_ "Version" SG_ 327 FHPTC_2ndPsLtdOpCause "24.02.06";
BA_ "UserSigValidity" SG_ 327 FHPTC_2ndPsFltLVHigh 7;
BA_ "Version" SG_ 327 FHPTC_2ndPsFltLVHigh "24.02.06";
BA_ "UserSigValidity" SG_ 327 FHPTC_2ndPsSwVer 7;
BA_ "Version" SG_ 327 FHPTC_2ndPsSwVer "24.02.06";
BA_ "UserSigValidity" SG_ 327 FHPTC_2ndPsFltHVLow 7;
BA_ "Version" SG_ 327 FHPTC_2ndPsFltHVLow "24.02.06";
BA_ "UserSigValidity" SG_ 327 FHPTC_2ndPsFltHVHigh 7;
BA_ "Version" SG_ 327 FHPTC_2ndPsFltHVHigh "24.02.06";
BA_ "UserSigValidity" SG_ 327 FHPTC_2ndPsFltOverCurrent 7;
BA_ "Version" SG_ 327 FHPTC_2ndPsFltOverCurrent "24.02.06";
BA_ "UserSigValidity" SG_ 327 FHPTC_2ndPsFltThermalShutDn 7;
BA_ "Version" SG_ 327 FHPTC_2ndPsFltThermalShutDn "24.02.06";
BA_ "UserSigValidity" SG_ 327 FHPTC_2ndPsFltPcbThermalShutDn 7;
BA_ "Version" SG_ 327 FHPTC_2ndPsFltPcbThermalShutDn "24.02.06";
BA_ "UserSigValidity" SG_ 327 FHPTC_2ndPsFltMsgTmOutATCU 7;
BA_ "Version" SG_ 327 FHPTC_2ndPsFltMsgTmOutATCU "24.02.06";
BA_ "UserSigValidity" SG_ 327 FHPTC_2ndPsFailHVSnr 7;
BA_ "Version" SG_ 327 FHPTC_2ndPsFailHVSnr "24.02.06";
BA_ "GenMsgCycleTime" BO_ 67 0;
BA_ "GenSigSendType" SG_ 67 HKBD_Fr_DrTempClickCnt 4;
BA_ "GenSigStartValue" SG_ 67 HKBD_Fr_DrTempClickCnt 255;
BA_ "UserSigValidity" SG_ 67 HKBD_Fr_DrTempClickCnt 7;
BA_REL_ "GenSigTimeoutTime" BU_SG_REL_ L_ATCU SG_ 67 HKBD_Fr_DrTempClickCnt 0;
BA_ "Version" SG_ 67 HKBD_Fr_DrTempClickCnt "24.05.08";
BA_ "GenSigSendType" SG_ 67 HKBD_Fr_RrTempClickCnt 4;
BA_ "GenSigStartValue" SG_ 67 HKBD_Fr_RrTempClickCnt 255;
BA_ "UserSigValidity" SG_ 67 HKBD_Fr_RrTempClickCnt 7;
BA_REL_ "GenSigTimeoutTime" BU_SG_REL_ L_ATCU SG_ 67 HKBD_Fr_RrTempClickCnt 0;
BA_ "Version" SG_ 67 HKBD_Fr_RrTempClickCnt "24.05.08";
BA_ "GenSigSendType" SG_ 67 HKBD_Fr_DrBlwClickCnt 4;
BA_ "GenSigStartValue" SG_ 67 HKBD_Fr_DrBlwClickCnt 255;
BA_ "UserSigValidity" SG_ 67 HKBD_Fr_DrBlwClickCnt 7;
BA_REL_ "GenSigTimeoutTime" BU_SG_REL_ L_ATCU SG_ 67 HKBD_Fr_DrBlwClickCnt 0;
BA_ "Version" SG_ 67 HKBD_Fr_DrBlwClickCnt "24.05.08";
BA_ "GenSigSendType" SG_ 67 HKBD_Fr_PsBlwClickCnt 4;
BA_ "GenSigStartValue" SG_ 67 HKBD_Fr_PsBlwClickCnt 255;
BA_ "UserSigValidity" SG_ 67 HKBD_Fr_PsBlwClickCnt 7;
BA_REL_ "GenSigTimeoutTime" BU_SG_REL_ L_ATCU SG_ 67 HKBD_Fr_PsBlwClickCnt 0;
BA_ "Version" SG_ 67 HKBD_Fr_PsBlwClickCnt "24.05.08";
BA_ "GenSigSendType" SG_ 67 HKBD_FrTempKnobCnt 4;
BA_ "GenSigStartValue" SG_ 67 HKBD_FrTempKnobCnt 3;
BA_ "UserSigValidity" SG_ 67 HKBD_FrTempKnobCnt 7;
BA_REL_ "GenSigTimeoutTime" BU_SG_REL_ L_ATCU SG_ 67 HKBD_FrTempKnobCnt 0;
BA_ "Version" SG_ 67 HKBD_FrTempKnobCnt "24.05.08";
BA_ "GenSigSendType" SG_ 67 HKBD_FrBlwKnobCnt 4;
BA_ "GenSigStartValue" SG_ 67 HKBD_FrBlwKnobCnt 3;
BA_ "UserSigValidity" SG_ 67 HKBD_FrBlwKnobCnt 7;
BA_REL_ "GenSigTimeoutTime" BU_SG_REL_ L_ATCU SG_ 67 HKBD_FrBlwKnobCnt 0;
BA_ "Version" SG_ 67 HKBD_FrBlwKnobCnt "24.05.08";
BA_ "GenSigSendType" SG_ 67 HKBD_Fr_PsTempClickCnt 4;
BA_ "GenSigStartValue" SG_ 67 HKBD_Fr_PsTempClickCnt 255;
BA_ "UserSigValidity" SG_ 67 HKBD_Fr_PsTempClickCnt 7;
BA_REL_ "GenSigTimeoutTime" BU_SG_REL_ L_ATCU SG_ 67 HKBD_Fr_PsTempClickCnt 0;
BA_ "Version" SG_ 67 HKBD_Fr_PsTempClickCnt "24.05.08";
BA_ "GenMsgSendType" BO_ 72 0;
BA_ "GenMsgCycleTime" BO_ 72 20;
BA_ "GenMsgCycleTimeFast" BO_ 72 0;
BA_ "GenMsgNrOfRepetition" BO_ 72 0;
BA_ "GenMsgDelayTime" BO_ 72 0;
BA_ "UserSigValidity" SG_ 72 HKBD_Fr_IncarRaw 7;
BA_ "Version" SG_ 72 HKBD_Fr_IncarRaw "23.08.13";
BA_ "GenMsgSendType" BO_ 624 0;
BA_ "GenMsgCycleTime" BO_ 624 20;
BA_ "GenMsgCycleTimeFast" BO_ 624 0;
BA_ "GenMsgNrOfRepetition" BO_ 624 0;
BA_ "GenMsgDelayTime" BO_ 624 0;
BA_ "UserSigValidity" SG_ 624 PCM_ActPosFB 7;
BA_ "Version" SG_ 624 PCM_ActPosFB "24.02.06";
BA_ "UserSigValidity" SG_ 624 PCM_Blwr1Sta 7;
BA_ "Version" SG_ 624 PCM_Blwr1Sta "24.02.06";
BA_ "UserSigValidity" SG_ 624 PCM_Blwr2Sta 7;
BA_ "Version" SG_ 624 PCM_Blwr2Sta "24.02.06";
BA_ "UserSigValidity" SG_ 624 PCM_Blwr1Fail 7;
BA_ "Version" SG_ 624 PCM_Blwr1Fail "24.02.06";
BA_ "UserSigValidity" SG_ 624 PCM_Blwr2Fail 7;
BA_ "Version" SG_ 624 PCM_Blwr2Fail "24.02.06";
BA_ "UserSigValidity" SG_ 624 PCM_MainCtrlSta 7;
BA_ "Version" SG_ 624 PCM_MainCtrlSta "24.02.06";
BA_ "UserSigValidity" SG_ 624 PCM_Cart1Sta 7;
BA_ "Version" SG_ 624 PCM_Cart1Sta "24.02.06";
BA_ "UserSigValidity" SG_ 624 PCM_Cart2Sta 7;
BA_ "Version" SG_ 624 PCM_Cart2Sta "24.02.06";
BA_ "UserSigValidity" SG_ 624 PCM_Cart1Kinds 7;
BA_ "Version" SG_ 624 PCM_Cart1Kinds "24.02.06";
BA_ "UserSigValidity" SG_ 624 PCM_Cart2Kinds 7;
BA_ "Version" SG_ 624 PCM_Cart2Kinds "24.02.06";
BA_ "UserSigValidity" SG_ 624 PCM_ActSta 7;
BA_ "Version" SG_ 624 PCM_ActSta "24.02.06";
BA_ "UserSigValidity" SG_ 624 PCM_ActFail 7;
BA_ "Version" SG_ 624 PCM_ActFail "24.02.06";
BA_ "GenMsgSendType" BO_ 625 0;
BA_ "GenMsgCycleTime" BO_ 625 500;
BA_ "GenSigSendType" SG_ 625 PCM_Cart1VectorX 4;
BA_ "UserSigValidity" SG_ 625 PCM_Cart1VectorX 7;
BA_REL_ "GenSigTimeoutTime" BU_SG_REL_ L_ATCU SG_ 625 PCM_Cart1VectorX 5000;
BA_ "Version" SG_ 625 PCM_Cart1VectorX "24.02.06";
BA_ "GenSigSendType" SG_ 625 PCM_Cart1RmnPer 4;
BA_ "UserSigValidity" SG_ 625 PCM_Cart1RmnPer 7;
BA_REL_ "GenSigTimeoutTime" BU_SG_REL_ L_ATCU SG_ 625 PCM_Cart1RmnPer 5000;
BA_ "Version" SG_ 625 PCM_Cart1RmnPer "24.02.06";
BA_ "GenSigSendType" SG_ 625 PCM_Cart1ExpSta 4;
BA_ "UserSigValidity" SG_ 625 PCM_Cart1ExpSta 7;
BA_REL_ "GenSigTimeoutTime" BU_SG_REL_ L_ATCU SG_ 625 PCM_Cart1ExpSta 5000;
BA_ "Version" SG_ 625 PCM_Cart1ExpSta "24.02.06";
BA_ "GenSigSendType" SG_ 625 PCM_Cart1RmnDisp 4;
BA_ "UserSigValidity" SG_ 625 PCM_Cart1RmnDisp 7;
BA_REL_ "GenSigTimeoutTime" BU_SG_REL_ L_ATCU SG_ 625 PCM_Cart1RmnDisp 5000;
BA_ "Version" SG_ 625 PCM_Cart1RmnDisp "24.02.06";
BA_ "GenSigSendType" SG_ 625 PCM_Cart1VectorY 4;
BA_ "UserSigValidity" SG_ 625 PCM_Cart1VectorY 7;
BA_REL_ "GenSigTimeoutTime" BU_SG_REL_ L_ATCU SG_ 625 PCM_Cart1VectorY 5000;
BA_ "Version" SG_ 625 PCM_Cart1VectorY "24.02.06";
BA_ "GenMsgSendType" BO_ 626 0;
BA_ "GenMsgCycleTime" BO_ 626 500;
BA_ "GenSigSendType" SG_ 626 PCM_Cart2VectorX 4;
BA_ "UserSigValidity" SG_ 626 PCM_Cart2VectorX 7;
BA_REL_ "GenSigTimeoutTime" BU_SG_REL_ L_ATCU SG_ 626 PCM_Cart2VectorX 5000;
BA_ "Version" SG_ 626 PCM_Cart2VectorX "24.02.06";
BA_ "GenSigSendType" SG_ 626 PCM_Cart2RmnPer 4;
BA_ "UserSigValidity" SG_ 626 PCM_Cart2RmnPer 7;
BA_REL_ "GenSigTimeoutTime" BU_SG_REL_ L_ATCU SG_ 626 PCM_Cart2RmnPer 5000;
BA_ "Version" SG_ 626 PCM_Cart2RmnPer "24.02.06";
BA_ "GenSigSendType" SG_ 626 PCM_Cart2ExpSta 4;
BA_ "UserSigValidity" SG_ 626 PCM_Cart2ExpSta 7;
BA_REL_ "GenSigTimeoutTime" BU_SG_REL_ L_ATCU SG_ 626 PCM_Cart2ExpSta 5000;
BA_ "Version" SG_ 626 PCM_Cart2ExpSta "24.02.06";
BA_ "GenSigSendType" SG_ 626 PCM_Cart2RmnDisp 4;
BA_ "UserSigValidity" SG_ 626 PCM_Cart2RmnDisp 7;
BA_REL_ "GenSigTimeoutTime" BU_SG_REL_ L_ATCU SG_ 626 PCM_Cart2RmnDisp 5000;
BA_ "Version" SG_ 626 PCM_Cart2RmnDisp "24.02.06";
BA_ "GenSigSendType" SG_ 626 PCM_Cart2VectorY 4;
BA_ "UserSigValidity" SG_ 626 PCM_Cart2VectorY 7;
BA_REL_ "GenSigTimeoutTime" BU_SG_REL_ L_ATCU SG_ 626 PCM_Cart2VectorY 5000;
BA_ "Version" SG_ 626 PCM_Cart2VectorY "24.02.06";
BA_ "GenMsgSendType" BO_ 336 0;
BA_ "GenMsgCycleTime" BO_ 336 20;
BA_ "GenMsgCycleTimeFast" BO_ 336 0;
BA_ "GenMsgNrOfRepetition" BO_ 336 0;
BA_ "GenMsgDelayTime" BO_ 336 0;
BA_ "UserSigValidity" SG_ 336 RHPTC_Zone1RdySta 7;
BA_ "Version" SG_ 336 RHPTC_Zone1RdySta "24.02.06";
BA_ "UserSigValidity" SG_ 336 RHPTC_Zone1OpSta 7;
BA_ "Version" SG_ 336 RHPTC_Zone1OpSta "24.02.06";
BA_ "UserSigValidity" SG_ 336 RHPTC_Zone1CnsmptPwr_W 7;
BA_ "Version" SG_ 336 RHPTC_Zone1CnsmptPwr_W "24.02.06";
BA_ "UserSigValidity" SG_ 336 RHPTC_Zone1Voltage_V 7;
BA_ "Version" SG_ 336 RHPTC_Zone1Voltage_V "24.02.06";
BA_ "UserSigValidity" SG_ 336 RHPTC_Zone1CtrlTyp 7;
BA_ "Version" SG_ 336 RHPTC_Zone1CtrlTyp "24.02.06";
BA_ "UserSigValidity" SG_ 336 RHPTC_Zone1Current_A 7;
BA_ "Version" SG_ 336 RHPTC_Zone1Current_A "24.02.06";
BA_ "Description" SG_ 336 RHPTC_Zone1DutyFB_Pec "Duty Conversion to PTC Consumption power value, 40w~6kw -> 10%~95%";
BA_ "UserSigValidity" SG_ 336 RHPTC_Zone1DutyFB_Pec 7;
BA_ "Version" SG_ 336 RHPTC_Zone1DutyFB_Pec "24.02.06";
BA_ "Description" SG_ 336 RHPTC_Zone1DutyFB_IGBT "PWM DUTY of PTC IGBT (0~100%)";
BA_ "UserSigValidity" SG_ 336 RHPTC_Zone1DutyFB_IGBT 7;
BA_ "Version" SG_ 336 RHPTC_Zone1DutyFB_IGBT "24.02.06";
BA_ "UserSigValidity" SG_ 336 RHPTC_Zone1CoreTemp_C 7;
BA_ "Version" SG_ 336 RHPTC_Zone1CoreTemp_C "24.02.06";
VAL_ 102 L_2HKBD_RrDrTempClickCnt 0 "RESERVED" 1 "01~0x7F:Clockwise" 127 "01~0x7F:Clockwise" 128 "80~0xFE:Counter Clockwise" 254 "80~0xFE:Counter Clockwise" 255 "Invalid" ;
VAL_ 102 L_2HKBD_RrPsTempClickCnt 0 "RESERVED" 1 "01~0x7F:Clockwise" 127 "01~0x7F:Clockwise" 128 "80~0xFE:Counter Clockwise" 254 "80~0xFE:Counter Clockwise" 255 "Invalid" ;
VAL_ 102 L_2HKBD_RrPsBlwrClickCnt 0 "RESERVED" 1 "01~0x7F:Clockwise" 127 "01~0x7F:Clockwise" 128 "80~0xFE:Counter Clockwise" 254 "80~0xFE:Counter Clockwise" 255 "Invalid" ;
VAL_ 102 L_2HKBD_RrTempKnobCnt 0 "0" 1 "1" 2 "2" 3 "invlaid" ;
VAL_ 102 L_2HKBD_RrBlwKnobCnt 0 "0" 1 "1" 2 "2" 3 "invlaid" ;
VAL_ 102 L_2HKBD_RrCurtainBtn 0 "Default" 1 "Open ON" 2 "Close ON" 3 "Invalid" ;
VAL_ 102 L_2HKBD_HVACPnlBckLight_Res 0 "Invalid(Default)" 1 "On" 2 "Off" 3 "RESERVED" ;
VAL_ 102 L_2HKBD_RrDrBlwrClickCnt 0 "RESERVED" 1 "01~0x7F:Clockwise" 127 "01~0x7F:Clockwise" 128 "80~0xFE:Counter Clockwise" 254 "80~0xFE:Counter Clockwise" 255 "Invalid" ;
VAL_ 851 L_ATCU_Lib_SnsrDrvVentDuct 0 "0x0~0x640:-40.0~160.0¡É" 1600 "0x0~0x640:-40.0~160.0¡É" 1601 "641~0xFFFE:RESERVED" 65534 "641~0xFFFE:RESERVED" 65535 "Invalid" ;
VAL_ 851 L_ATCU_Lib_SnsrAstVentDuct 0 "0x0~0x640:-40.0~160.0¡É" 1600 "0x0~0x640:-40.0~160.0¡É" 1601 "641~0xFFFE:RESERVED" 65534 "641~0xFFFE:RESERVED" 65535 "Invalid" ;
VAL_ 851 L_ATCU_Lib_SnsrDrvFloorDuct 0 "0x0~0x640:-40.0~160.0¡É" 1600 "0x0~0x640:-40.0~160.0¡É" 1601 "641~0xFFFE:RESERVED" 65534 "641~0xFFFE:RESERVED" 65535 "Invalid" ;
VAL_ 851 L_ATCU_Lib_SnsrAstFloorDuct 0 "0x0~0x640:-40.0~160.0¡É" 1600 "0x0~0x640:-40.0~160.0¡É" 1601 "641~0xFFFE:RESERVED" 65534 "641~0xFFFE:RESERVED" 65535 "Invalid" ;
VAL_ 864 L_ATCU_Lib_MngrDEFBuf0 0 "KeyOff" 1 "FloorPuge" 2 "Mode" 3 "Num" 4 "RESERVED" 5 "RESERVED" 6 "RESERVED" 7 "RESERVED" ;
VAL_ 864 L_ATCU_Lib_MngrACBuf0 0 "DEF" 1 "RemoteFATC_DEF" 2 "SMKRemoteFATC" 3 "Washer" 4 "MIX" 5 "AirPurify" 6 "ADS" 7 "ManualSw" 8 "MAXCool" 9 "Auto" 10 "Num" 11 "RESERVED" 12 "RESERVED" 13 "RESERVED" 14 "RESERVED" 15 "RESERVED" ;
VAL_ 864 L_ATCU_Lib_MngrACBuf1 0 "DEF" 1 "RemoteFATC_DEF" 2 "SMKRemoteFATC" 3 "Washer" 4 "MIX" 5 "AirPurify" 6 "ADS" 7 "ManualSw" 8 "MAXCool" 9 "Auto" 10 "Num" 11 "RESERVED" 12 "RESERVED" 13 "RESERVED" 14 "RESERVED" 15 "RESERVED" ;
VAL_ 864 L_ATCU_Lib_MngrACBuf2 0 "DEF" 1 "RemoteFATC_DEF" 2 "SMKRemoteFATC" 3 "Washer" 4 "MIX" 5 "AirPurify" 6 "ADS" 7 "ManualSw" 8 "MAXCool" 9 "Auto" 10 "Num" 11 "RESERVED" 12 "RESERVED" 13 "RESERVED" 14 "RESERVED" 15 "RESERVED" ;
VAL_ 864 L_ATCU_Lib_MngrACBuf3 0 "DEF" 1 "RemoteFATC_DEF" 2 "SMKRemoteFATC" 3 "Washer" 4 "MIX" 5 "AirPurify" 6 "ADS" 7 "ManualSw" 8 "MAXCool" 9 "Auto" 10 "Num" 11 "RESERVED" 12 "RESERVED" 13 "RESERVED" 14 "RESERVED" 15 "RESERVED" ;
VAL_ 864 L_ATCU_Lib_MngrACBuf4 0 "DEF" 1 "RemoteFATC_DEF" 2 "SMKRemoteFATC" 3 "Washer" 4 "MIX" 5 "AirPurify" 6 "ADS" 7 "ManualSw" 8 "MAXCool" 9 "Auto" 10 "Num" 11 "RESERVED" 12 "RESERVED" 13 "RESERVED" 14 "RESERVED" 15 "RESERVED" ;
VAL_ 864 L_ATCU_Lib_MngrDEFBuf1 0 "KeyOff" 1 "FloorPuge" 2 "Mode" 3 "Num" 4 "RESERVED" 5 "RESERVED" 6 "RESERVED" 7 "RESERVED" ;
VAL_ 864 L_ATCU_Lib_MngrACBuf5 0 "DEF" 1 "RemoteFATC_DEF" 2 "SMKRemoteFATC" 3 "Washer" 4 "MIX" 5 "AirPurify" 6 "ADS" 7 "ManualSw" 8 "MAXCool" 9 "Auto" 10 "Num" 11 "RESERVED" 12 "RESERVED" 13 "RESERVED" 14 "RESERVED" 15 "RESERVED" ;
VAL_ 864 L_ATCU_Lib_MngrACBuf6 0 "DEF" 1 "RemoteFATC_DEF" 2 "SMKRemoteFATC" 3 "Washer" 4 "MIX" 5 "AirPurify" 6 "ADS" 7 "ManualSw" 8 "MAXCool" 9 "Auto" 10 "Num" 11 "RESERVED" 12 "RESERVED" 13 "RESERVED" 14 "RESERVED" 15 "RESERVED" ;
VAL_ 864 L_ATCU_Lib_MngrACBuf7 0 "DEF" 1 "RemoteFATC_DEF" 2 "SMKRemoteFATC" 3 "Washer" 4 "MIX" 5 "AirPurify" 6 "ADS" 7 "ManualSw" 8 "MAXCool" 9 "Auto" 10 "Num" 11 "RESERVED" 12 "RESERVED" 13 "RESERVED" 14 "RESERVED" 15 "RESERVED" ;
VAL_ 864 L_ATCU_Lib_MngrDEFBufLow1 0 "ADS" 1 "SmrtVent" 2 "Num" 3 "RESERVED" ;
VAL_ 864 L_ATCU_Lib_MngrTempBufLow1 0 "EvapDry" 1 "ADS" 2 "PECbyDEF" 3 "Num" ;
VAL_ 864 L_ATCU_Lib_MngrTempBufLow0 0 "EvapDry" 1 "ADS" 2 "PECbyDEF" 3 "Num" ;
VAL_ 864 L_ATCU_Lib_MngrIntakeBufHi0 0 "BATCooling" 1 "HighSpeed" 2 "Num" 3 "RESERVED" ;
VAL_ 864 L_ATCU_Lib_MngrIntakeBufHi1 0 "BATCooling" 1 "HighSpeed" 2 "Num" 3 "RESERVED" ;
VAL_ 864 L_ATCU_Lib_MngrIntakeBufLow2 0 "PTG" 1 "PartialIntake" 2 "ISG" 3 "RESERVED" ;
VAL_ 864 L_ATCU_Lib_MngrDEFBufLow0 0 "ADS" 1 "SmrtVent" 2 "Num" 3 "RESERVED" ;
VAL_ 864 L_ATCU_Lib_MngrDEFBuf2 0 "KeyOff" 1 "FloorPuge" 2 "Mode" 3 "Num" 4 "RESERVED" 5 "RESERVED" 6 "RESERVED" 7 "RESERVED" ;
VAL_ 865 L_ATCU_Lib_MngrIntakeBuf0 0 "KeyOff" 1 "SmartVencForcedOn" 2 "RemoteFATC" 3 "RemoteFATC_DEF" 4 "AutoWash" 5 "Washer" 6 "ADS" 7 "Sunroof" 8 "Tunnel" 9 "AirPurify" 10 "DEF" 11 "MIX" 12 "FloorPurge" 13 "AQS_REC" 14 "AQS_FRE" 15 "FREbyTime" 16 "protectEvapRust" 17 "ManualSw_FRE" 18 "ManualSw_REC" 19 "SmrtVent" 20 "SysOff" 21 "MaxHot" 22 "MaxCool" 23 "StayMod" 24 "SchdldVent" 25 "AfterBlow" 26 "Auto_FRE" 27 "Num" 28 "RESERVED" 29 "RESERVED" 30 "RESERVED" 31 "RESERVED" ;
VAL_ 865 L_ATCU_Lib_MngrIntakeBufLow1 0 "PTG" 1 "PartialIntake" 2 "ISG" 3 "RESERVED" ;
VAL_ 865 L_ATCU_Lib_MngrIntakeBuf2 0 "KeyOff" 1 "SmartVencForcedOn" 2 "RemoteFATC" 3 "RemoteFATC_DEF" 4 "AutoWash" 5 "Washer" 6 "ADS" 7 "Sunroof" 8 "Tunnel" 9 "AirPurify" 10 "DEF" 11 "MIX" 12 "FloorPurge" 13 "AQS_REC" 14 "AQS_FRE" 15 "FREbyTime" 16 "protectEvapRust" 17 "ManualSw_FRE" 18 "ManualSw_REC" 19 "SmrtVent" 20 "SysOff" 21 "MaxHot" 22 "MaxCool" 23 "StayMod" 24 "SchdldVent" 25 "AfterBlow" 26 "Auto_FRE" 27 "Num" 28 "RESERVED" 29 "RESERVED" 30 "RESERVED" 31 "RESERVED" ;
VAL_ 865 L_ATCU_Lib_MngrTempBuf0 0 "MaxCool" 1 "MaxHot" 2 "Last" 3 "AfterBlow" 4 "Auto" 5 "Num" 6 "RESERVED" 7 "RESERVED" ;
VAL_ 865 L_ATCU_Lib_MngrIntakeBuf3 0 "KeyOff" 1 "SmartVencForcedOn" 2 "RemoteFATC" 3 "RemoteFATC_DEF" 4 "AutoWash" 5 "Washer" 6 "ADS" 7 "Sunroof" 8 "Tunnel" 9 "AirPurify" 10 "DEF" 11 "MIX" 12 "FloorPurge" 13 "AQS_REC" 14 "AQS_FRE" 15 "FREbyTime" 16 "protectEvapRust" 17 "ManualSw_FRE" 18 "ManualSw_REC" 19 "SmrtVent" 20 "SysOff" 21 "MaxHot" 22 "MaxCool" 23 "StayMod" 24 "SchdldVent" 25 "AfterBlow" 26 "Auto_FRE" 27 "Num" 28 "RESERVED" 29 "RESERVED" 30 "RESERVED" 31 "RESERVED" ;
VAL_ 865 L_ATCU_Lib_MngrTempBuf1 0 "MaxCool" 1 "MaxHot" 2 "Last" 3 "AfterBlow" 4 "Auto" 5 "Num" 6 "RESERVED" 7 "RESERVED" ;
VAL_ 865 L_ATCU_Lib_MngrIntakeBuf4 0 "KeyOff" 1 "SmartVencForcedOn" 2 "RemoteFATC" 3 "RemoteFATC_DEF" 4 "SMKRemoteFATC" 5 "Washer" 6 "ADS" 7 "Sunroof" 8 "Tunnel" 9 "AirPurify" 10 "DEF" 11 "MIX" 12 "FloorPurge" 13 "AQS_REC" 14 "AQS_FRE" 15 "FREbyTime" 16 "protectEvapRust" 17 "ManualSw_FRE" 18 "ManualSw_REC" 19 "SmrtVent" 20 "SysOff" 21 "MaxHot" 22 "MaxCool" 23 "StayMod" 24 "SchdldVent" 25 "AfterBlow" 26 "Auto_FRE" 27 "Num" 28 "RESERVED" 29 "RESERVED" 30 "RESERVED" 31 "RESERVED" ;
VAL_ 865 L_ATCU_Lib_MngrTempBuf2 0 "MaxCool" 1 "MaxHot" 2 "Last" 3 "AfterBlow" 4 "Auto" 5 "Num" 6 "RESERVED" 7 "RESERVED" ;
VAL_ 865 L_ATCU_Lib_MngrIntakeBuf5 0 "KeyOff" 1 "SmartVencForcedOn" 2 "RemoteFATC" 3 "RemoteFATC_DEF" 4 "SMKRemoteFATC" 5 "Washer" 6 "ADS" 7 "Sunroof" 8 "Tunnel" 9 "AirPurify" 10 "DEF" 11 "MIX" 12 "FloorPurge" 13 "AQS_REC" 14 "AQS_FRE" 15 "FREbyTime" 16 "protectEvapRust" 17 "ManualSw_FRE" 18 "ManualSw_REC" 19 "SmrtVent" 20 "SysOff" 21 "MaxHot" 22 "MaxCool" 23 "StayMod" 24 "SchdldVent" 25 "AfterBlow" 26 "Auto_FRE" 27 "Num" 28 "RESERVED" 29 "RESERVED" 30 "RESERVED" 31 "RESERVED" ;
VAL_ 865 L_ATCU_Lib_MngrTempBuf3 0 "MaxCool" 1 "MaxHot" 2 "Last" 3 "AfterBlow" 4 "Auto" 5 "Num" 6 "RESERVED" 7 "RESERVED" ;
VAL_ 865 L_ATCU_Lib_MngrIntakeBuf6 0 "KeyOff" 1 "SmartVencForcedOn" 2 "RemoteFATC" 3 "RemoteFATC_DEF" 4 "SMKRemoteFATC" 5 "Washer" 6 "ADS" 7 "Sunroof" 8 "Tunnel" 9 "AirPurify" 10 "DEF" 11 "MIX" 12 "FloorPurge" 13 "AQS_REC" 14 "AQS_FRE" 15 "FREbyTime" 16 "protectEvapRust" 17 "ManualSw_FRE" 18 "ManualSw_REC" 19 "SmrtVent" 20 "SysOff" 21 "MaxHot" 22 "MaxCool" 23 "StayMod" 24 "SchdldVent" 25 "AfterBlow" 26 "Auto_FRE" 27 "Num" 28 "RESERVED" 29 "RESERVED" 30 "RESERVED" 31 "RESERVED" ;
VAL_ 865 L_ATCU_Lib_MngrIntakeBufLow0 0 "PTG" 1 "PartialIntake" 2 "ISG" 3 "RESERVED" ;
VAL_ 865 L_ATCU_Lib_MngrTempBuf4 0 "MaxCool" 1 "MaxHot" 2 "Last" 3 "AfterBlow" 4 "Auto" 5 "Num" 6 "RESERVED" 7 "RESERVED" ;
VAL_ 865 L_ATCU_Lib_MngrIntakeBuf7 0 "KeyOff" 1 "SmartVencForcedOn" 2 "RemoteFATC" 3 "RemoteFATC_DEF" 4 "SMKRemoteFATC" 5 "Washer" 6 "ADS" 7 "Sunroof" 8 "Tunnel" 9 "AirPurify" 10 "DEF" 11 "MIX" 12 "FloorPurge" 13 "AQS_REC" 14 "AQS_FRE" 15 "FREbyTime" 16 "protectEvapRust" 17 "ManualSw_FRE" 18 "ManualSw_REC" 19 "SmrtVent" 20 "SysOff" 21 "MaxHot" 22 "MaxCool" 23 "StayMod" 24 "SchdldVent" 25 "AfterBlow" 26 "Auto_FRE" 27 "Num" 28 "RESERVED" 29 "RESERVED" 30 "RESERVED" 31 "RESERVED" ;
VAL_ 865 L_ATCU_Lib_MngrTempBufLow2 0 "EvapDry" 1 "ADS" 2 "PECbyDEF" 3 "Num" ;
VAL_ 865 L_ATCU_Lib_MngrIntakeBuf1 0 "KeyOff" 1 "SmartVencForcedOn" 2 "RemoteFATC" 3 "RemoteFATC_DEF" 4 "AutoWash" 5 "Washer" 6 "ADS" 7 "Sunroof" 8 "Tunnel" 9 "AirPurify" 10 "DEF" 11 "MIX" 12 "FloorPurge" 13 "AQS_REC" 14 "AQS_FRE" 15 "FREbyTime" 16 "protectEvapRust" 17 "ManualSw_FRE" 18 "ManualSw_REC" 19 "SmrtVent" 20 "SysOff" 21 "MaxHot" 22 "MaxCool" 23 "StayMod" 24 "SchdldVent" 25 "AfterBlow" 26 "Auto_FRE" 27 "Num" 28 "RESERVED" 29 "RESERVED" 30 "RESERVED" 31 "RESERVED" ;
VAL_ 866 L_ATCU_Lib_2LHMngrModBuf0 0 "KeyOff" 1 "ManualSw" 2 "MaxCool" 3 "HotStart" 4 "FootZone" 5 "MaxHot" 6 "Auto" 7 "Num" 8 "RESERVED" 9 "RESERVED" 10 "RESERVED" 11 "RESERVED" 12 "RESERVED" 13 "RESERVED" 14 "RESERVED" 15 "RESERVED" ;
VAL_ 866 L_ATCU_Lib_2LHMngrModBuf3 0 "KeyOff" 1 "ManualSw" 2 "MaxCool" 3 "HotStart" 4 "FootZone" 5 "MaxHot" 6 "Auto" 7 "Num" 8 "RESERVED" 9 "RESERVED" 10 "RESERVED" 11 "RESERVED" 12 "RESERVED" 13 "RESERVED" 14 "RESERVED" 15 "RESERVED" ;
VAL_ 866 L_ATCU_Lib_2LHMngrModBuf4 0 "KeyOff" 1 "ManualSw" 2 "MaxCool" 3 "HotStart" 4 "FootZone" 5 "MaxHot" 6 "Auto" 7 "Num" 8 "RESERVED" 9 "RESERVED" 10 "RESERVED" 11 "RESERVED" 12 "RESERVED" 13 "RESERVED" 14 "RESERVED" 15 "RESERVED" ;
VAL_ 866 L_ATCU_Lib_2LHMngrModBuf5 0 "KeyOff" 1 "ManualSw" 2 "MaxCool" 3 "HotStart" 4 "FootZone" 5 "MaxHot" 6 "Auto" 7 "Num" 8 "RESERVED" 9 "RESERVED" 10 "RESERVED" 11 "RESERVED" 12 "RESERVED" 13 "RESERVED" 14 "RESERVED" 15 "RESERVED" ;
VAL_ 866 L_ATCU_Lib_2LHMngrModBuf6 0 "KeyOff" 1 "ManualSw" 2 "MaxCool" 3 "HotStart" 4 "FootZone" 5 "MaxHot" 6 "Auto" 7 "Num" 8 "RESERVED" 9 "RESERVED" 10 "RESERVED" 11 "RESERVED" 12 "RESERVED" 13 "RESERVED" 14 "RESERVED" 15 "RESERVED" ;
VAL_ 866 L_ATCU_Lib_2LHMngrModBuf7 0 "KeyOff" 1 "ManualSw" 2 "MaxCool" 3 "HotStart" 4 "FootZone" 5 "MaxHot" 6 "Auto" 7 "Num" 8 "RESERVED" 9 "RESERVED" 10 "RESERVED" 11 "RESERVED" 12 "RESERVED" 13 "RESERVED" 14 "RESERVED" 15 "RESERVED" ;
VAL_ 866 L_ATCU_Lib_2LHMngrBlwBuf0 0 "MaxCool" 1 "HotStart" 2 "MaxHot" 3 "ManualSw" 4 "Auto" 5 "Num" 6 "RESERVED" 7 "RESERVED" 8 "RESERVED" 9 "RESERVED" 10 "RESERVED" 11 "RESERVED" 12 "RESERVED" 13 "RESERVED" 14 "RESERVED" 15 "RESERVED" ;
VAL_ 866 L_ATCU_Lib_2LHMngrBlwBuf1 0 "MaxCool" 1 "HotStart" 2 "MaxHot" 3 "ManualSw" 4 "Auto" 5 "Num" 6 "RESERVED" 7 "RESERVED" 8 "RESERVED" 9 "RESERVED" 10 "RESERVED" 11 "RESERVED" 12 "RESERVED" 13 "RESERVED" 14 "RESERVED" 15 "RESERVED" ;
VAL_ 866 L_ATCU_Lib_2LHMngrModBuf1 0 "KeyOff" 1 "ManualSw" 2 "MaxCool" 3 "HotStart" 4 "FootZone" 5 "MaxHot" 6 "Auto" 7 "Num" 8 "RESERVED" 9 "RESERVED" 10 "RESERVED" 11 "RESERVED" 12 "RESERVED" 13 "RESERVED" 14 "RESERVED" 15 "RESERVED" ;
VAL_ 866 L_ATCU_Lib_2LHMngrBlwBuf2 0 "StartBlower" 1 "MaxCool" 2 "HotStart" 3 "MaxHot" 4 "ManualSw" 5 "Auto" 6 "Num" 7 "RESERVED" 8 "RESERVED" 9 "RESERVED" 10 "RESERVED" 11 "RESERVED" 12 "RESERVED" 13 "RESERVED" 14 "RESERVED" 15 "RESERVED" ;
VAL_ 866 L_ATCU_Lib_2LHMngrBlwBuf3 0 "MaxCool" 1 "HotStart" 2 "MaxHot" 3 "ManualSw" 4 "Auto" 5 "Num" 6 "RESERVED" 7 "RESERVED" 8 "RESERVED" 9 "RESERVED" 10 "RESERVED" 11 "RESERVED" 12 "RESERVED" 13 "RESERVED" 14 "RESERVED" 15 "RESERVED" ;
VAL_ 866 L_ATCU_Lib_2LHMngrBlwBuf4 0 "MaxCool" 1 "HotStart" 2 "MaxHot" 3 "ManualSw" 4 "Auto" 5 "Num" 6 "RESERVED" 7 "RESERVED" 8 "RESERVED" 9 "RESERVED" 10 "RESERVED" 11 "RESERVED" 12 "RESERVED" 13 "RESERVED" 14 "RESERVED" 15 "RESERVED" ;
VAL_ 866 L_ATCU_Lib_2LHMngrBlwBuf5 0 "MaxCool" 1 "HotStart" 2 "MaxHot" 3 "ManualSw" 4 "Auto" 5 "Num" 6 "RESERVED" 7 "RESERVED" 8 "RESERVED" 9 "RESERVED" 10 "RESERVED" 11 "RESERVED" 12 "RESERVED" 13 "RESERVED" 14 "RESERVED" 15 "RESERVED" ;
VAL_ 866 L_ATCU_Lib_2LHMngrBlwBuf6 0 "MaxCool" 1 "HotStart" 2 "MaxHot" 3 "ManualSw" 4 "Auto" 5 "Num" 6 "RESERVED" 7 "RESERVED" 8 "RESERVED" 9 "RESERVED" 10 "RESERVED" 11 "RESERVED" 12 "RESERVED" 13 "RESERVED" 14 "RESERVED" 15 "RESERVED" ;
VAL_ 866 L_ATCU_Lib_2LHMngrBlwBufHi0 0 "AirFlowLinkage" 1 "ISG" 2 "Num" 3 "RESERVED" ;
VAL_ 866 L_ATCU_Lib_2LHMngrBlwBufHi1 0 "AirFlowLinkage" 1 "ISG" 2 "Num" 3 "RESERVED" ;
VAL_ 866 L_ATCU_Lib_2LHMngrModBuf2 0 "KeyOff" 1 "ManualSw" 2 "MaxCool" 3 "HotStart" 4 "FootZone" 5 "MaxHot" 6 "Auto" 7 "Num" 8 "RESERVED" 9 "RESERVED" 10 "RESERVED" 11 "RESERVED" 12 "RESERVED" 13 "RESERVED" 14 "RESERVED" 15 "RESERVED" ;
VAL_ 867 L_ATCU_Lib_2LHMngrTempBuf0 0 "MaxCool" 1 "MaxHot" 2 "Auto" 3 "Num" 4 "RESERVED" 5 "RESERVED" 6 "RESERVED" 7 "RESERVED" ;
VAL_ 867 L_ATCU_Lib_2RHMngrTempBuf0 0 "MaxCool" 1 "MaxHot" 2 "Auto" 3 "Num" 4 "RESERVED" 5 "RESERVED" 6 "RESERVED" 7 "RESERVED" ;
VAL_ 867 L_ATCU_Lib_2RHMngrTempBuf1 0 "MaxCool" 1 "MaxHot" 2 "Auto" 3 "Num" 4 "RESERVED" 5 "RESERVED" 6 "RESERVED" 7 "RESERVED" ;
VAL_ 867 L_ATCU_Lib_2RHMngrTempBuf2 0 "MaxCool" 1 "MaxHot" 2 "Auto" 3 "Num" 4 "RESERVED" 5 "RESERVED" 6 "RESERVED" 7 "RESERVED" ;
VAL_ 867 L_ATCU_Lib_2LHMngrTempBuf1 0 "MaxCool" 1 "MaxHot" 2 "Auto" 3 "Num" 4 "RESERVED" 5 "RESERVED" 6 "RESERVED" 7 "RESERVED" ;
VAL_ 867 L_ATCU_Lib_2LHMngrTempBuf2 0 "MaxCool" 1 "MaxHot" 2 "Auto" 3 "Num" 4 "RESERVED" 5 "RESERVED" 6 "RESERVED" 7 "RESERVED" ;
VAL_ 868 L_ATCU_Lib_SWVer 0 "0x00~0xFFFF:Only HEX, Not ASCII value" 65535 "0x00~0xFFFF:Only HEX, Not ASCII value" ;
VAL_ 1025 L_EVNT_HU_FrDrEVntSidePtDisp_X 0 "Default" 1 "001~0x780:PHY=HEX*1 + 0" 1920 "001~0x780:PHY=HEX*1 + 0" 1921 "781~0x7FE:RESERVED" 2046 "781~0x7FE:RESERVED" 2047 "Invalid" ;
VAL_ 1025 L_EVNT_HU_FrDrEVntSidePtDisp_Y 0 "Default" 1 "001~0x780:PHY=HEX*1 + 0" 1920 "001~0x780:PHY=HEX*1 + 0" 1921 "781~0x7FE:RESERVED" 2046 "781~0x7FE:RESERVED" 2047 "Invalid" ;
VAL_ 1025 L_EVNT_HU_FrDrEVntCtrPtDisp_X 0 "Default" 1 "001~0x780:PHY=HEX*1 + 0" 1920 "001~0x780:PHY=HEX*1 + 0" 1921 "781~0x7FE:RESERVED" 2046 "781~0x7FE:RESERVED" 2047 "Invalid" ;
VAL_ 1025 L_EVNT_HU_FrDrEVntCtrPtDisp_Y 0 "Default" 1 "001~0x780:PHY=HEX*1 + 0" 1920 "001~0x780:PHY=HEX*1 + 0" 1921 "781~0x7FE:RESERVED" 2046 "781~0x7FE:RESERVED" 2047 "Invalid" ;
VAL_ 1026 L_EVNT_HU_FrPsEVntSidePtDisp_X 0 "Default" 1 "001~0x780:PHY=HEX*1 + 0" 1920 "001~0x780:PHY=HEX*1 + 0" 1921 "781~0x7FE:RESERVED" 2046 "781~0x7FE:RESERVED" 2047 "Invalid" ;
VAL_ 1026 L_EVNT_HU_FrPsEVntSidePtDisp_Y 0 "Default" 1 "001~0x780:PHY=HEX*1 + 0" 1920 "001~0x780:PHY=HEX*1 + 0" 1921 "781~0x7FE:RESERVED" 2046 "781~0x7FE:RESERVED" 2047 "Invalid" ;
VAL_ 1026 L_EVNT_HU_FrPsEVntCtrPtDisp_X 0 "Default" 1 "001~0x780:PHY=HEX*1 + 0" 1920 "001~0x780:PHY=HEX*1 + 0" 1921 "781~0x7FE:RESERVED" 2046 "781~0x7FE:RESERVED" 2047 "Invalid" ;
VAL_ 1026 L_EVNT_HU_FrPsEVntCtrPtDisp_Y 0 "Default" 1 "001~0x780:PHY=HEX*1 + 0" 1920 "001~0x780:PHY=HEX*1 + 0" 1921 "781~0x7FE:RESERVED" 2046 "781~0x7FE:RESERVED" 2047 "Invalid" ;
VAL_ 1027 L_EVNT_HU_RrDrEVntConsPtDisp_X 0 "Default" 1 "001~0x780:PHY=HEX*1 + 0" 1920 "001~0x780:PHY=HEX*1 + 0" 1921 "781~0x7FE:RESERVED" 2046 "781~0x7FE:RESERVED" 2047 "Invalid" ;
VAL_ 1027 L_EVNT_HU_RrDrEVntConsPtDisp_Y 0 "Default" 1 "001~0x780:PHY=HEX*1 + 0" 1920 "001~0x780:PHY=HEX*1 + 0" 1921 "781~0x7FE:RESERVED" 2046 "781~0x7FE:RESERVED" 2047 "Invalid" ;
VAL_ 1027 L_EVNT_HU_RrPsEVntConsPtDisp_X 0 "Default" 1 "001~0x780:PHY=HEX*1 + 0" 1920 "001~0x780:PHY=HEX*1 + 0" 1921 "781~0x7FE:RESERVED" 2046 "781~0x7FE:RESERVED" 2047 "Invalid" ;
VAL_ 1027 L_EVNT_HU_RrPsEVntConsPtDisp_Y 0 "Default" 1 "001~0x780:PHY=HEX*1 + 0" 1920 "001~0x780:PHY=HEX*1 + 0" 1921 "781~0x7FE:RESERVED" 2046 "781~0x7FE:RESERVED" 2047 "Invalid" ;
VAL_ 1027 L_EVNT_FrDrEVntSideFlt 0 "Default" 1 "No Error" 2 "Error" 3 "Error Indicator" ;
VAL_ 1027 L_EVNT_FrDrEVntCtrFlt 0 "Default" 1 "No Error" 2 "Error" 3 "Error Indicator" ;
VAL_ 1027 L_EVNT_FrPsEVntSideFlt 0 "Default" 1 "No Error" 2 "Error" 3 "Error Indicator" ;
VAL_ 1027 L_EVNT_FrPsEVntCtrFlt 0 "Default" 1 "No Error" 2 "Error" 3 "Error Indicator" ;
VAL_ 1027 L_EVNT_RrDrEVntConsFlt 0 "Default" 1 "No Error" 2 "Error" 3 "Error Indicator" ;
VAL_ 1027 L_EVNT_RrPsEVntConsFlt 0 "Default" 1 "No Error" 2 "Error" 3 "Error Indicator" ;
VAL_ 1028 L_EVNT_FrDrEVntModeSet_Disp 0 "Default" 1 "FOCUS Mode" 2 "SPREAD Mode" 3 "CYCLE Mode" 4 "FREE Mode" 5 "OFF" 6 "RESERVED" 7 "RESERVED" 8 "RESERVED" 9 "RESERVED" 10 "RESERVED" 11 "RESERVED" 12 "RESERVED" 13 "RESERVED" 14 "RESERVED" 15 "Invalid" ;
VAL_ 1028 L_EVNT_RrPsEVntModeSet_Disp 0 "Default" 1 "FOCUS Mode" 2 "SPREAD Mode" 3 "CYCLE Mode" 4 "FREE Mode" 5 "OFF" 6 "RESERVED" 7 "RESERVED" 8 "RESERVED" 9 "RESERVED" 10 "RESERVED" 11 "RESERVED" 12 "RESERVED" 13 "RESERVED" 14 "RESERVED" 15 "Invalid" ;
VAL_ 1028 L_EVNT_FrDrEVntSideOpnClsDisp 0 "Default" 1 "OPEN" 2 "CLOSE" 3 "Invalid" ;
VAL_ 1028 L_EVNT_FrDrEVntCtrOpnClsDisp 0 "Default" 1 "OPEN" 2 "CLOSE" 3 "Invalid" ;
VAL_ 1028 L_EVNT_FrPsEVntSideOpnClsDisp 0 "Default" 1 "OPEN" 2 "CLOSE" 3 "Invalid" ;
VAL_ 1028 L_EVNT_FrPsEVntCtrOpnClsDisp 0 "Default" 1 "OPEN" 2 "CLOSE" 3 "Invalid" ;
VAL_ 1028 L_EVNT_RrDrEVntConsOpnClsDisp 0 "Default" 1 "OPEN" 2 "CLOSE" 3 "Invalid" ;
VAL_ 1028 L_EVNT_RrPsEVntConsOpnClsDisp 0 "Default" 1 "OPEN" 2 "CLOSE" 3 "Invalid" ;
VAL_ 1028 L_EVNT_EVntTouchInform_HU 0 "Default" 1 "APPLY" 2 "NOT APPLY" 3 "Invalid" ;
VAL_ 1028 L_EVNT_EVntTouchInform_CTS 0 "Default" 1 "APPLY" 2 "NOT APPLY" 3 "Invalid" ;
VAL_ 1028 L_EVNT_FrtEvntFocusLvlSta 0 "Default" 1 "1 Level" 2 "2 Level" 3 "3 Level" 4 "4 Level" 5 "5 Level" 6 "RESERVED" 7 "RESERVED" ;
VAL_ 1028 L_EVNT_RrEvntFocusLvlSta 0 "Default" 1 "1 Level" 2 "2 Level" 3 "3 Level" 4 "4 Level" 5 "5 Level" 6 "RESERVED" 7 "RESERVED" ;
VAL_ 1028 L_EVNT_DrVntOpt 0 "Default" 1 "APPLY" 2 "NOT APPLY" 3 "Invalid" ;
VAL_ 1028 L_EVNT_FrPsEVntModeSet_Disp 0 "Default" 1 "FOCUS Mode" 2 "SPREAD Mode" 3 "CYCLE Mode" 4 "FREE Mode" 5 "OFF" 6 "RESERVED" 7 "RESERVED" 8 "RESERVED" 9 "RESERVED" 10 "RESERVED" 11 "RESERVED" 12 "RESERVED" 13 "RESERVED" 14 "RESERVED" 15 "Invalid" ;
VAL_ 1028 L_EVNT_AstVntOpt 0 "Default" 1 "APPLY" 2 "NOT APPLY" 3 "Invalid" ;
VAL_ 1028 L_EVNT_RrDrVntOpt 0 "Default" 1 "APPLY" 2 "NOT APPLY" 3 "Invalid" ;
VAL_ 1028 L_EVNT_RrAstVntOpt 0 "Default" 1 "APPLY" 2 "NOT APPLY" 3 "Invalid" ;
VAL_ 1028 L_EVNT_EVntAutoFlowHardSwOpt 0 "Default" 1 "HardSw APPLY" 2 "HardSw NOT APPLY" 3 "Invalid" ;
VAL_ 1028 L_EVNT_RrDrEVntModeSet_Disp 0 "Default" 1 "FOCUS Mode" 2 "SPREAD Mode" 3 "CYCLE Mode" 4 "FREE Mode" 5 "OFF" 6 "RESERVED" 7 "RESERVED" 8 "RESERVED" 9 "RESERVED" 10 "RESERVED" 11 "RESERVED" 12 "RESERVED" 13 "RESERVED" 14 "RESERVED" 15 "Invalid" ;
VAL_ 1029 L_EVNT_CTS_FrDrEVntSidePtDisp_X 0 "Default" 1 "001~0x780:PHY=HEX*1 + 0" 1920 "001~0x780:PHY=HEX*1 + 0" 1921 "781~0x7FE:RESERVED" 2046 "781~0x7FE:RESERVED" 2047 "Invalid" ;
VAL_ 1029 L_EVNT_CTS_FrDrEVntSidePtDisp_Y 0 "Default" 1 "001~0x780:PHY=HEX*1 + 0" 1920 "001~0x780:PHY=HEX*1 + 0" 1921 "781~0x7FE:RESERVED" 2046 "781~0x7FE:RESERVED" 2047 "Invalid" ;
VAL_ 1029 L_EVNT_CTS_FrDrEVntCtrPtDisp_X 0 "Default" 1 "001~0x780:PHY=HEX*1 + 0" 1920 "001~0x780:PHY=HEX*1 + 0" 1921 "781~0x7FE:RESERVED" 2046 "781~0x7FE:RESERVED" 2047 "Invalid" ;
VAL_ 1029 L_EVNT_CTS_FrDrEVntCtrPtDisp_Y 0 "Default" 1 "001~0x780:PHY=HEX*1 + 0" 1920 "001~0x780:PHY=HEX*1 + 0" 1921 "781~0x7FE:RESERVED" 2046 "781~0x7FE:RESERVED" 2047 "Invalid" ;
VAL_ 1030 L_EVNT_CTS_FrPsEVntSidePtDisp_X 0 "Default" 1 "001~0x780:PHY=HEX*1 + 0" 1920 "001~0x780:PHY=HEX*1 + 0" 1921 "781~0x7FE:RESERVED" 2046 "781~0x7FE:RESERVED" 2047 "Invalid" ;
VAL_ 1030 L_EVNT_CTS_FrPsEVntSidePtDisp_Y 0 "Default" 1 "001~0x780:PHY=HEX*1 + 0" 1920 "001~0x780:PHY=HEX*1 + 0" 1921 "781~0x7FE:RESERVED" 2046 "781~0x7FE:RESERVED" 2047 "Invalid" ;
VAL_ 1030 L_EVNT_CTS_FrPsEVntCtrPtDisp_X 0 "Default" 1 "001~0x780:PHY=HEX*1 + 0" 1920 "001~0x780:PHY=HEX*1 + 0" 1921 "781~0x7FE:RESERVED" 2046 "781~0x7FE:RESERVED" 2047 "Invalid" ;
VAL_ 1030 L_EVNT_CTS_FrPsEVntCtrPtDisp_Y 0 "Default" 1 "001~0x780:PHY=HEX*1 + 0" 1920 "001~0x780:PHY=HEX*1 + 0" 1921 "781~0x7FE:RESERVED" 2046 "781~0x7FE:RESERVED" 2047 "Invalid" ;
VAL_ 1031 L_EVNT_CTS_RrDrEVntConsPtDisp_X 0 "Default" 1 "001~0x780:PHY=HEX*1 + 0" 1920 "001~0x780:PHY=HEX*1 + 0" 1921 "781~0x7FE:RESERVED" 2046 "781~0x7FE:RESERVED" 2047 "Invalid" ;
VAL_ 1031 L_EVNT_CTS_RrDrEVntConsPtDisp_Y 0 "Default" 1 "001~0x780:PHY=HEX*1 + 0" 1920 "001~0x780:PHY=HEX*1 + 0" 1921 "781~0x7FE:RESERVED" 2046 "781~0x7FE:RESERVED" 2047 "Invalid" ;
VAL_ 1031 L_EVNT_CTS_RrPsEVntConsPtDisp_X 0 "Default" 1 "001~0x780:PHY=HEX*1 + 0" 1920 "001~0x780:PHY=HEX*1 + 0" 1921 "781~0x7FE:RESERVED" 2046 "781~0x7FE:RESERVED" 2047 "Invalid" ;
VAL_ 1031 L_EVNT_CTS_RrPsEVntConsPtDisp_Y 0 "Default" 1 "001~0x780:PHY=HEX*1 + 0" 1920 "001~0x780:PHY=HEX*1 + 0" 1921 "781~0x7FE:RESERVED" 2046 "781~0x7FE:RESERVED" 2047 "Invalid" ;
VAL_ 1040 L_EVNT_FrDrEVntAutoFlowOSDReq 0 "Default" 1 "Mode Set (Drv)" 2 "Open/Close Set (Drv)" 3 "Invalid" ;
VAL_ 1040 L_EVNT_FrAstEVntAutoFlowOSDReq 2 "Open/Close Set (Ast)" 3 "Invalid" 0 "Default" 1 "Mode Set (Ast)" ;
VAL_ 320 FHPTC_DrRdySta 0 "Not Ready(Disable to control)" 1 "Ready (Enable to Control)" ;
VAL_ 320 FHPTC_DrOpSta 0 "Stop Mode" 1 "Operation Mode" 2 "Failure Mode" 3 "Limited operation Mode" ;
VAL_ 320 FHPTC_DrCnsmptPwr_W 0 "0x0~0x2710:Power" 10000 "0x0~0x2710:Power" 65535 "ERROR" ;
VAL_ 320 FHPTC_DrCurrent_A 0 "0x0~0xFA:Current" 250 "0x0~0xFA:Current" 251 "RESERVED" 252 "RESERVED" 253 "RESERVED" 254 "RESERVED" 255 "ERROR" ;
VAL_ 320 FHPTC_DrCoreTemp_C 0 "0x00~0xF0:Temperature" 240 "0x00~0xF0:Temperature" 241 "RESERVED" 242 "RESERVED" 243 "RESERVED" 244 "RESERVED" 245 "RESERVED" 246 "RESERVED" 247 "RESERVED" 248 "RESERVED" 249 "RESERVED" 250 "RESERVED" 251 "RESERVED" 252 "RESERVED" 253 "The thermister is open." 254 "The thermister is short." 255 "ERROR" ;
VAL_ 320 FHPTC_DrDutyFB_Pec 0 "0x0~0xC8:Duty" 200 "0x0~0xC8:Duty" 201 "RESERVED" 202 "RESERVED" 203 "RESERVED" 204 "RESERVED" 205 "RESERVED" 206 "RESERVED" 207 "RESERVED" 208 "RESERVED" 209 "RESERVED" 210 "RESERVED" 211 "RESERVED" 212 "RESERVED" 213 "RESERVED" 214 "RESERVED" 215 "RESERVED" 216 "RESERVED" 217 "RESERVED" 218 "RESERVED" 219 "RESERVED" 220 "RESERVED" 221 "RESERVED" 222 "RESERVED" 223 "RESERVED" 224 "RESERVED" 225 "RESERVED" 226 "RESERVED" 227 "RESERVED" 228 "RESERVED" 229 "RESERVED" 230 "RESERVED" 231 "RESERVED" 232 "RESERVED" 233 "RESERVED" 234 "RESERVED" 235 "RESERVED" 236 "RESERVED" 237 "RESERVED" 238 "RESERVED" 239 "RESERVED" 240 "RESERVED" 241 "RESERVED" 242 "RESERVED" 243 "RESERVED" 244 "RESERVED" 245 "RESERVED" 246 "RESERVED" 247 "RESERVED" 248 "RESERVED" 249 "RESERVED" 250 "RESERVED" 251 "RESERVED" 252 "RESERVED" 253 "RESERVED" 254 "RESERVED" 255 "ERROR" ;
VAL_ 320 FHPTC_DrDutyFB_IGBT 0 "0x0~0xC8:Duty" 200 "0x0~0xC8:Duty" 201 "RESERVED" 202 "RESERVED" 203 "RESERVED" 204 "RESERVED" 205 "RESERVED" 206 "RESERVED" 207 "RESERVED" 208 "RESERVED" 209 "RESERVED" 210 "RESERVED" 211 "RESERVED" 212 "RESERVED" 213 "RESERVED" 214 "RESERVED" 215 "RESERVED" 216 "RESERVED" 217 "RESERVED" 218 "RESERVED" 219 "RESERVED" 220 "RESERVED" 221 "RESERVED" 222 "RESERVED" 223 "RESERVED" 224 "RESERVED" 225 "RESERVED" 226 "RESERVED" 227 "RESERVED" 228 "RESERVED" 229 "RESERVED" 230 "RESERVED" 231 "RESERVED" 232 "RESERVED" 233 "RESERVED" 234 "RESERVED" 235 "RESERVED" 236 "RESERVED" 237 "RESERVED" 238 "RESERVED" 239 "RESERVED" 240 "RESERVED" 241 "RESERVED" 242 "RESERVED" 243 "RESERVED" 244 "RESERVED" 245 "RESERVED" 246 "RESERVED" 247 "RESERVED" 248 "RESERVED" 249 "RESERVED" 250 "RESERVED" 251 "RESERVED" 252 "RESERVED" 253 "RESERVED" 254 "RESERVED" 255 "ERROR" ;
VAL_ 320 FHPTC_DrCtrlTyp 0 "Single PTC & Single Control" 1 "Dual PTC & Single Control" 2 "Dual PTC & Dual Control" ;
VAL_ 320 FHPTC_DrVoltage_V 0 "0x0~0xFA:Voltage" 250 "0x0~0xFA:Voltage" 251 "RESERVED" 252 "RESERVED" 253 "RESERVED" 254 "RESERVED" 255 "ERROR" ;
VAL_ 321 FHPTC_DrFlt 0 "Normal" 1 "Fault" ;
VAL_ 321 FHPTC_DrFltLVLow 0 "Normal" 1 "Fault" ;
VAL_ 321 FHPTC_DrFailLVSnr 0 "Normal" 1 "Fault(Open or Short)" ;
VAL_ 321 FHPTC_DrFailCurrentSnr 0 "Normal" 1 "Fault(Open or Short)" ;
VAL_ 321 FHPTC_DrFailCoreTempSnr 0 "Normal" 1 "Fault(Open or Short)" ;
VAL_ 321 FHPTC_DrFailPcbTempSnr 0 "Normal" 1 "Fault(Open or Short)" ;
VAL_ 321 FHPTC_DrFailIGBT 0 "Normal" 1 "Fault" ;
VAL_ 321 FHPTC_DrFailOpenLoad 0 "Normal" 1 "Fault" ;
VAL_ 321 FHPTC_DrLtdOpCause 0 "Normal Operation" 1 "Ltd Operation by LVLowDr" 2 "Ltd Operation by LVHighDr" 3 "Ltd Operation by HVLowDr" 4 "Ltd Operation by HVHighDr" 5 "Ltd Operation by OverCurrentDr" 8 "Ltd Operation by ThermalShutDnDr" 9 "Ltd Operation by PCBThermalShutDnDr" 10 "A~0xFF:RESERVED" 255 "A~0xFF:RESERVED" ;
VAL_ 321 FHPTC_DrFltLVHigh 0 "Normal" 1 "Fault" ;
VAL_ 321 FHPTC_DrFltHVLow 0 "Normal" 1 "Fault" ;
VAL_ 321 FHPTC_CnsmptPwrTtl_W 0 "0x0~0x2710:Power" 10000 "0x0~0x2710:Power" 65535 "ERROR" ;
VAL_ 321 FHPTC_DrFltHVHigh 0 "Normal" 1 "Fault" ;
VAL_ 321 FHPTC_IntlkSta 0 "Disconnect" 1 "Connect" 2 "Default" 3 "Error Indicator" ;
VAL_ 321 FHPTC_DrFltOverCurrent 0 "Normal" 1 "Fault" ;
VAL_ 321 FHPTC_DrFltThermalShutDn 0 "Normal" 1 "Fault" ;
VAL_ 321 FHPTC_DrFltPcbThermalShutDn 0 "Normal" 1 "Fault" ;
VAL_ 321 FHPTC_DrFltMsgTmOutATCU 0 "Normal" 1 "Message Timeout" ;
VAL_ 321 FHPTC_DrFailHVSnr 0 "Normal" 1 "Fault(Open or Short)" ;
VAL_ 322 FHPTC_PassRdySta 0 "Not Ready(Disable to control)" 1 "Ready (Enable to Control)" ;
VAL_ 322 FHPTC_PassOpSta 0 "Stop Mode" 1 "Operation Mode" 2 "Failure Mode" 3 "Limited operation Mode" ;
VAL_ 322 FHPTC_PassCnsmptPwr_W 0 "0x0~0x2710:Power" 10000 "0x0~0x2710:Power" 65535 "ERROR" ;
VAL_ 322 FHPTC_PassCtrlTyp 0 "Single PTC & Single Control" 1 "Dual PTC & Single Control" 2 "Dual PTC & Dual Control" ;
VAL_ 322 FHPTC_PassVoltage_V 0 "0x0~0xFA:Voltage" 250 "0x0~0xFA:Voltage" 251 "RESERVED0xFF:ERROR" 252 "RESERVED0xFF:ERROR" 253 "RESERVED0xFF:ERROR" 254 "RESERVED0xFF:ERROR" ;
VAL_ 322 FHPTC_PassCurrent_A 0 "0x0~0xFA:Current" 250 "0x0~0xFA:Current" 251 "RESERVED" 252 "RESERVED" 253 "RESERVED" 254 "RESERVED" 255 "ERROR" ;
VAL_ 322 FHPTC_PassDutyFB_Pec 0 "0x0~0xC8:Duty" 200 "0x0~0xC8:Duty" 201 "RESERVED" 202 "RESERVED" 203 "RESERVED" 204 "RESERVED" 205 "RESERVED" 206 "RESERVED" 207 "RESERVED" 208 "RESERVED" 209 "RESERVED" 210 "RESERVED" 211 "RESERVED" 212 "RESERVED" 213 "RESERVED" 214 "RESERVED" 215 "RESERVED" 216 "RESERVED" 217 "RESERVED" 218 "RESERVED" 219 "RESERVED" 220 "RESERVED" 221 "RESERVED" 222 "RESERVED" 223 "RESERVED" 224 "RESERVED" 225 "RESERVED" 226 "RESERVED" 227 "RESERVED" 228 "RESERVED" 229 "RESERVED" 230 "RESERVED" 231 "RESERVED" 232 "RESERVED" 233 "RESERVED" 234 "RESERVED" 235 "RESERVED" 236 "RESERVED" 237 "RESERVED" 238 "RESERVED" 239 "RESERVED" 240 "RESERVED" 241 "RESERVED" 242 "RESERVED" 243 "RESERVED" 244 "RESERVED" 245 "RESERVED" 246 "RESERVED" 247 "RESERVED" 248 "RESERVED" 249 "RESERVED" 250 "RESERVED" 251 "RESERVED" 252 "RESERVED" 253 "RESERVED" 254 "RESERVED" 255 "ERROR" ;
VAL_ 322 FHPTC_PassDutyFB_IGBT 0 "0x0~0xC8:Duty" 200 "0x0~0xC8:Duty" 201 "RESERVED" 202 "RESERVED" 203 "RESERVED" 204 "RESERVED" 205 "RESERVED" 206 "RESERVED" 207 "RESERVED" 208 "RESERVED" 209 "RESERVED" 210 "RESERVED" 211 "RESERVED" 212 "RESERVED" 213 "RESERVED" 214 "RESERVED" 215 "RESERVED" 216 "RESERVED" 217 "RESERVED" 218 "RESERVED" 219 "RESERVED" 220 "RESERVED" 221 "RESERVED" 222 "RESERVED" 223 "RESERVED" 224 "RESERVED" 225 "RESERVED" 226 "RESERVED" 227 "RESERVED" 228 "RESERVED" 229 "RESERVED" 230 "RESERVED" 231 "RESERVED" 232 "RESERVED" 233 "RESERVED" 234 "RESERVED" 235 "RESERVED" 236 "RESERVED" 237 "RESERVED" 238 "RESERVED" 239 "RESERVED" 240 "RESERVED" 241 "RESERVED" 242 "RESERVED" 243 "RESERVED" 244 "RESERVED" 245 "RESERVED" 246 "RESERVED" 247 "RESERVED" 248 "RESERVED" 249 "RESERVED" 250 "RESERVED" 251 "RESERVED" 252 "RESERVED" 253 "RESERVED" 254 "RESERVED" 255 "ERROR" ;
VAL_ 322 FHPTC_PassCoreTemp_C 0 "0x0~0xF0:Temperature" 240 "0x0~0xF0:Temperature" 241 "RESERVED/0XFD:The thermister is open" 242 "RESERVED/0XFD:The thermister is open" 243 "RESERVED/0XFD:The thermister is open" 244 "RESERVED/0XFD:The thermister is open" 245 "RESERVED/0XFD:The thermister is open" 246 "RESERVED/0XFD:The thermister is open" 247 "RESERVED/0XFD:The thermister is open" 248 "RESERVED/0XFD:The thermister is open" 249 "RESERVED/0XFD:The thermister is open" 250 "RESERVED/0XFD:The thermister is open" 251 "RESERVED/0XFD:The thermister is open" 252 "RESERVED/0XFD:The thermister is open" 254 "The thermister is short" 255 "ERROR" ;
VAL_ 323 FHPTC_PassFlt 0 "Normal" 1 "Fault" ;
VAL_ 323 FHPTC_PassFltLVLow 0 "Normal" 1 "Fault" ;
VAL_ 323 FHPTC_PassFailLVSnr 0 "Normal" 1 "Fault(Open or Short)" ;
VAL_ 323 FHPTC_PassFailCurrentSnr 0 "Normal" 1 "Fault(Open or Short)" ;
VAL_ 323 FHPTC_PassFailCoreTempSnr 0 "Normal" 1 "Fault(Open or Short)" ;
VAL_ 323 FHPTC_PassFailPcbTempSnr 0 "Normal" 1 "Fault(Open or Short)" ;
VAL_ 323 FHPTC_PassFailIGBT 0 "Normal" 1 "Fault" ;
VAL_ 323 FHPTC_PassFailOpenLoad 0 "Normal" 1 "Fault" ;
VAL_ 323 FHPTC_PassLtdOpCause 0 "Normal Operation" 1 "Ltd Operation by LVLowDr" 2 "Ltd Operation by LVHighDr" 3 "Ltd Operation by HVLowDr" 4 "Ltd Operation by HVHighDr" 5 "Ltd Operation by OverCurrentDr" ;
VAL_ 323 FHPTC_PassFltLVHigh 0 "Normal" 1 "Fault" ;
VAL_ 323 FHPTC_PassFltHVLow 0 "Normal" 1 "Fault" ;
VAL_ 323 FHPTC_PassFltHVHigh 0 "Normal" 1 "Fault" ;
VAL_ 323 FHPTC_PassFltOverCurrent 0 "Normal" 1 "Fault" ;
VAL_ 323 FHPTC_PassFltThermalShutDn 0 "Normal" 1 "Fault" ;
VAL_ 323 FHPTC_PassFltPcbThermalShutDn 0 "Normal" 1 "Fault" ;
VAL_ 323 FHPTC_PassFltMsgTmOutATCU 0 "Normal" 1 "Message Timeout" ;
VAL_ 323 FHPTC_PassFailHVSnr 0 "Normal" 1 "Fault(Open or Short)" ;
VAL_ 324 FHPTC_2ndDrRdySta 0 "Not Ready(Disable to control)" 1 "Ready (Enable to Control)" ;
VAL_ 324 FHPTC_2ndDrOpSta 0 "Stop Mode" 1 "Operation Mode" 2 "Failure Mode" 3 "Limited operation Mode" ;
VAL_ 324 FHPTC_2ndDrCnsmptPwr_W 0 "0x0~0x2710:Power" 10000 "0x0~0x2710:Power" 65535 "ERROR" ;
VAL_ 324 FHPTC_2ndDrCurrent_A 0 "0x0~0xFA:Current" 250 "0x0~0xFA:Current" 251 "RESERVED" 252 "RESERVED" 253 "RESERVED" 254 "RESERVED" 255 "ERROR" ;
VAL_ 324 FHPTC_2ndDrCoreTemp_C 0 "0x00~0xF0:Temperature" 240 "0x00~0xF0:Temperature" 241 "RESERVED" 242 "RESERVED" 243 "RESERVED" 244 "RESERVED" 245 "RESERVED" 246 "RESERVED" 247 "RESERVED" 248 "RESERVED" 249 "RESERVED" 250 "RESERVED" 251 "RESERVED" 252 "RESERVED" 253 "The thermister is open." 254 "The thermister is short." 255 "ERROR" ;
VAL_ 324 FHPTC_2ndDrDutyFB_Pec 0 "0x0~0xC8:Duty" 200 "0x0~0xC8:Duty" 201 "RESERVED" 202 "RESERVED" 203 "RESERVED" 204 "RESERVED" 205 "RESERVED" 206 "RESERVED" 207 "RESERVED" 208 "RESERVED" 209 "RESERVED" 210 "RESERVED" 211 "RESERVED" 212 "RESERVED" 213 "RESERVED" 214 "RESERVED" 215 "RESERVED" 216 "RESERVED" 217 "RESERVED" 218 "RESERVED" 219 "RESERVED" 220 "RESERVED" 221 "RESERVED" 222 "RESERVED" 223 "RESERVED" 224 "RESERVED" 225 "RESERVED" 226 "RESERVED" 227 "RESERVED" 228 "RESERVED" 229 "RESERVED" 230 "RESERVED" 231 "RESERVED" 232 "RESERVED" 233 "RESERVED" 234 "RESERVED" 235 "RESERVED" 236 "RESERVED" 237 "RESERVED" 238 "RESERVED" 239 "RESERVED" 240 "RESERVED" 241 "RESERVED" 242 "RESERVED" 243 "RESERVED" 244 "RESERVED" 245 "RESERVED" 246 "RESERVED" 247 "RESERVED" 248 "RESERVED" 249 "RESERVED" 250 "RESERVED" 251 "RESERVED" 252 "RESERVED" 253 "RESERVED" 254 "RESERVED" 255 "ERROR" ;
VAL_ 324 FHPTC_2ndDrDutyFB_IGBT 0 "0x0~0xC8:Duty" 200 "0x0~0xC8:Duty" 201 "RESERVED" 202 "RESERVED" 203 "RESERVED" 204 "RESERVED" 205 "RESERVED" 206 "RESERVED" 207 "RESERVED" 208 "RESERVED" 209 "RESERVED" 210 "RESERVED" 211 "RESERVED" 212 "RESERVED" 213 "RESERVED" 214 "RESERVED" 215 "RESERVED" 216 "RESERVED" 217 "RESERVED" 218 "RESERVED" 219 "RESERVED" 220 "RESERVED" 221 "RESERVED" 222 "RESERVED" 223 "RESERVED" 224 "RESERVED" 225 "RESERVED" 226 "RESERVED" 227 "RESERVED" 228 "RESERVED" 229 "RESERVED" 230 "RESERVED" 231 "RESERVED" 232 "RESERVED" 233 "RESERVED" 234 "RESERVED" 235 "RESERVED" 236 "RESERVED" 237 "RESERVED" 238 "RESERVED" 239 "RESERVED" 240 "RESERVED" 241 "RESERVED" 242 "RESERVED" 243 "RESERVED" 244 "RESERVED" 245 "RESERVED" 246 "RESERVED" 247 "RESERVED" 248 "RESERVED" 249 "RESERVED" 250 "RESERVED" 251 "RESERVED" 252 "RESERVED" 253 "RESERVED" 254 "RESERVED" 255 "ERROR" ;
VAL_ 324 FHPTC_2ndDrCtrlTyp 0 "Single PTC & Single Control" 1 "Dual PTC & Single Control" 2 "Dual PTC & Dual Control" ;
VAL_ 324 FHPTC_2ndDrVoltage_V 0 "0x0~0xFA:Voltage" 250 "0x0~0xFA:Voltage" 251 "RESERVED" 252 "RESERVED" 253 "RESERVED" 254 "RESERVED" 255 "ERROR" ;
VAL_ 325 FHPTC_2ndDrFlt 0 "Normal" 1 "Fault" ;
VAL_ 325 FHPTC_2ndDrFltLVLow 0 "Normal" 1 "Fault" ;
VAL_ 325 FHPTC_2ndDrFailLVSnr 0 "Normal" 1 "Fault(Open or Short)" ;
VAL_ 325 FHPTC_2ndDrFailCurrentSnr 0 "Normal" 1 "Fault(Open or Short)" ;
VAL_ 325 FHPTC_2ndDrFailCoreTempSnr 0 "Normal" 1 "Fault(Open or Short)" ;
VAL_ 325 FHPTC_2ndDrFailPcbTempSnr 0 "Normal" 1 "Fault(Open or Short)" ;
VAL_ 325 FHPTC_2ndDrFailIGBT 0 "Normal" 1 "Fault" ;
VAL_ 325 FHPTC_2ndDrFailOpenLoad 0 "Normal" 1 "Fault" ;
VAL_ 325 FHPTC_2ndDrLtdOpCause 0 "Normal Operation" 1 "Ltd Operation by LVLowDr" 2 "Ltd Operation by LVHighDr" 3 "Ltd Operation by HVLowDr" 4 "Ltd Operation by HVHighDr" 5 "Ltd Operation by OverCurrentDr" 8 "Ltd Operation by ThermalShutDnDr" 9 "Ltd Operation by PCBThermalShutDnDr" 10 "A~0xFF:RESERVED" 255 "A~0xFF:RESERVED" ;
VAL_ 325 FHPTC_2ndDrFltLVHigh 0 "Normal" 1 "Fault" ;
VAL_ 325 FHPTC_2ndDrFltHVLow 0 "Normal" 1 "Fault" ;
VAL_ 325 FHPTC_2ndDrFltHVHigh 0 "Normal" 1 "Fault" ;
VAL_ 325 FHPTC_2ndDrFltOverCurrent 0 "Normal" 1 "Fault" ;
VAL_ 325 FHPTC_2ndDrFltThermalShutDn 0 "Normal" 1 "Fault" ;
VAL_ 325 FHPTC_2ndDrFltPcbThermalShutDn 0 "Normal" 1 "Fault" ;
VAL_ 325 FHPTC_2ndDrFltMsgTmOutATCU 0 "Normal" 1 "Message Timeout" ;
VAL_ 325 FHPTC_2ndDrFailHVSnr 0 "Normal" 1 "Fault(Open or Short)" ;
VAL_ 326 FHPTC_2ndPsRdySta 0 "Not Ready(Disable to control)" 1 "Ready (Enable to Control)" ;
VAL_ 326 FHPTC_2ndPsOpSta 0 "Stop Mode" 1 "Operation Mode" 2 "Failure Mode" 3 "Limited operation Mode" ;
VAL_ 326 FHPTC_2ndPsCnsmptPwr_W 0 "0x0~0x2710:Power" 10000 "0x0~0x2710:Power" 65535 "ERROR" ;
VAL_ 326 FHPTC_2ndPsCtrlTyp 0 "Single PTC & Single Control" 1 "Dual PTC & Single Control" 2 "Dual PTC & Dual Control" ;
VAL_ 326 FHPTC_2ndPsVoltage_V 0 "0x0~0xFA:Voltage" 250 "0x0~0xFA:Voltage" 251 "RESERVED0xFF:ERROR" 252 "RESERVED0xFF:ERROR" 253 "RESERVED0xFF:ERROR" 254 "RESERVED0xFF:ERROR" ;
VAL_ 326 FHPTC_2ndPsCurrent_A 0 "0x0~0xFA:Current" 250 "0x0~0xFA:Current" 251 "RESERVED" 252 "RESERVED" 253 "RESERVED" 254 "RESERVED" 255 "ERROR" ;
VAL_ 326 FHPTC_2ndPsDutyFB_Pec 0 "0x0~0xC8:Duty" 200 "0x0~0xC8:Duty" 201 "RESERVED" 202 "RESERVED" 203 "RESERVED" 204 "RESERVED" 205 "RESERVED" 206 "RESERVED" 207 "RESERVED" 208 "RESERVED" 209 "RESERVED" 210 "RESERVED" 211 "RESERVED" 212 "RESERVED" 213 "RESERVED" 214 "RESERVED" 215 "RESERVED" 216 "RESERVED" 217 "RESERVED" 218 "RESERVED" 219 "RESERVED" 220 "RESERVED" 221 "RESERVED" 222 "RESERVED" 223 "RESERVED" 224 "RESERVED" 225 "RESERVED" 226 "RESERVED" 227 "RESERVED" 228 "RESERVED" 229 "RESERVED" 230 "RESERVED" 231 "RESERVED" 232 "RESERVED" 233 "RESERVED" 234 "RESERVED" 235 "RESERVED" 236 "RESERVED" 237 "RESERVED" 238 "RESERVED" 239 "RESERVED" 240 "RESERVED" 241 "RESERVED" 242 "RESERVED" 243 "RESERVED" 244 "RESERVED" 245 "RESERVED" 246 "RESERVED" 247 "RESERVED" 248 "RESERVED" 249 "RESERVED" 250 "RESERVED" 251 "RESERVED" 252 "RESERVED" 253 "RESERVED" 254 "RESERVED" 255 "ERROR" ;
VAL_ 326 FHPTC_2ndPsDutyFB_IGBT 0 "0x0~0xC8:Duty" 200 "0x0~0xC8:Duty" 201 "RESERVED" 202 "RESERVED" 203 "RESERVED" 204 "RESERVED" 205 "RESERVED" 206 "RESERVED" 207 "RESERVED" 208 "RESERVED" 209 "RESERVED" 210 "RESERVED" 211 "RESERVED" 212 "RESERVED" 213 "RESERVED" 214 "RESERVED" 215 "RESERVED" 216 "RESERVED" 217 "RESERVED" 218 "RESERVED" 219 "RESERVED" 220 "RESERVED" 221 "RESERVED" 222 "RESERVED" 223 "RESERVED" 224 "RESERVED" 225 "RESERVED" 226 "RESERVED" 227 "RESERVED" 228 "RESERVED" 229 "RESERVED" 230 "RESERVED" 231 "RESERVED" 232 "RESERVED" 233 "RESERVED" 234 "RESERVED" 235 "RESERVED" 236 "RESERVED" 237 "RESERVED" 238 "RESERVED" 239 "RESERVED" 240 "RESERVED" 241 "RESERVED" 242 "RESERVED" 243 "RESERVED" 244 "RESERVED" 245 "RESERVED" 246 "RESERVED" 247 "RESERVED" 248 "RESERVED" 249 "RESERVED" 250 "RESERVED" 251 "RESERVED" 252 "RESERVED" 253 "RESERVED" 254 "RESERVED" 255 "ERROR" ;
VAL_ 326 FHPTC_2ndPsCoreTemp_C 0 "0x0~0xF0:Temperature" 240 "0x0~0xF0:Temperature" 241 "RESERVED/0XFD:The thermister is open" 242 "RESERVED/0XFD:The thermister is open" 243 "RESERVED/0XFD:The thermister is open" 244 "RESERVED/0XFD:The thermister is open" 245 "RESERVED/0XFD:The thermister is open" 246 "RESERVED/0XFD:The thermister is open" 247 "RESERVED/0XFD:The thermister is open" 248 "RESERVED/0XFD:The thermister is open" 249 "RESERVED/0XFD:The thermister is open" 250 "RESERVED/0XFD:The thermister is open" 251 "RESERVED/0XFD:The thermister is open" 252 "RESERVED/0XFD:The thermister is open" 254 "The thermister is short" 255 "ERROR" ;
VAL_ 327 FHPTC_2ndPsFlt 0 "Normal" 1 "Fault" ;
VAL_ 327 FHPTC_2ndPsFltLVLow 0 "Normal" 1 "Fault" ;
VAL_ 327 FHPTC_2ndPsFailLVSnr 0 "Normal" 1 "Fault(Open or Short)" ;
VAL_ 327 FHPTC_2ndPsFailCurrentSnr 0 "Normal" 1 "Fault(Open or Short)" ;
VAL_ 327 FHPTC_2ndPsFailCoreTempSnr 0 "Normal" 1 "Fault(Open or Short)" ;
VAL_ 327 FHPTC_2ndPsFailPcbTempSnr 0 "Normal" 1 "Fault(Open or Short)" ;
VAL_ 327 FHPTC_2ndPsFailIGBT 0 "Normal" 1 "Fault" ;
VAL_ 327 FHPTC_2ndPsFailOpenLoad 0 "Normal" 1 "Fault" ;
VAL_ 327 FHPTC_2ndPsLtdOpCause 0 "Normal Operation" 1 "Ltd Operation by LVLowDr" 2 "Ltd Operation by LVHighDr" 3 "Ltd Operation by HVLowDr" 4 "Ltd Operation by HVHighDr" 5 "Ltd Operation by OverCurrentDr" ;
VAL_ 327 FHPTC_2ndPsFltLVHigh 0 "Normal" 1 "Fault" ;
VAL_ 327 FHPTC_2ndPsFltHVLow 0 "Normal" 1 "Fault" ;
VAL_ 327 FHPTC_2ndPsFltHVHigh 0 "Normal" 1 "Fault" ;
VAL_ 327 FHPTC_2ndPsFltOverCurrent 0 "Normal" 1 "Fault" ;
VAL_ 327 FHPTC_2ndPsFltThermalShutDn 0 "Normal" 1 "Fault" ;
VAL_ 327 FHPTC_2ndPsFltPcbThermalShutDn 0 "Normal" 1 "Fault" ;
VAL_ 327 FHPTC_2ndPsFltMsgTmOutATCU 0 "Normal" 1 "Message Timeout" ;
VAL_ 327 FHPTC_2ndPsFailHVSnr 0 "Normal" 1 "Fault(Open or Short)" ;
VAL_ 67 HKBD_Fr_DrTempClickCnt 0 "RESERVED" 1 "1~0x7F:clockwise" 127 "1~0x7F:clockwise" 128 "80~0xFE:Counterclockwise" 254 "80~0xFE:Counterclockwise" 255 "Invalid" ;
VAL_ 67 HKBD_Fr_RrTempClickCnt 0 "RESERVED" 1 "1~0x7F:clockwise" 127 "1~0x7F:clockwise" 128 "80~0xFE:Counterclockwise" 254 "80~0xFE:Counterclockwise" 255 "Invalid" ;
VAL_ 67 HKBD_Fr_DrBlwClickCnt 0 "RESERVED" 1 "1~0x7F:clockwise" 127 "1~0x7F:clockwise" 128 "80~0xFE:Counterclockwise" 254 "80~0xFE:Counterclockwise" 255 "Invalid" ;
VAL_ 67 HKBD_Fr_PsBlwClickCnt 0 "RESERVED" 1 "1~0x7F:clockwise" 127 "1~0x7F:clockwise" 128 "80~0xFE:Counterclockwise" 254 "80~0xFE:Counterclockwise" 255 "Invalid" ;
VAL_ 67 HKBD_FrTempKnobCnt 0 "0" 1 "1" 2 "2" 3 "invalid" ;
VAL_ 67 HKBD_FrBlwKnobCnt 0 "0" 1 "1" 2 "2" 3 "invalid" ;
VAL_ 67 HKBD_Fr_PsTempClickCnt 0 "RESERVED" 1 "1~0x7F:clockwise" 127 "1~0x7F:clockwise" 128 "80~0xFE:Counterclockwise" 254 "80~0xFE:Counterclockwise" 255 "Invalid" ;
VAL_ 72 HKBD_Fr_IncarRaw 1023 "Error Indicator" ;
VAL_ 624 PCM_ActPosFB 0 "OFF" 1 "Cartridge#1" 2 "Cartridge#2" 3 "Calibrating" 4 "Moving - #1 to #2" 5 "Moving - #1 to Off" 6 "Moving - #2 to #1" 7 "Moving - #2 to Off" 8 "Moving Off to #1" 9 "Moving Off to #2" 10 "RESERVED" 11 "RESERVED" 12 "RESERVED" 13 "RESERVED" 14 "RESERVED" 15 "Error Indicator" ;
VAL_ 624 PCM_Blwr1Sta 0 "Normal OFF" 1 "Normal ON" 2 "Temporary Failure" 3 "Permanent Failure" ;
VAL_ 624 PCM_Blwr2Sta 0 "Normal OFF" 1 "Normal ON" 2 "Temporary Failure" 3 "Permanent Failure" ;
VAL_ 624 PCM_Blwr1Fail 0 "Normal" 1 "Circuit Open/Short (internal error, diagnosis/Siganl line open/short)" 2 "Motor Stall" 3 "Over Current" 4 "Over Temperature" 5 "Under Voltage" 6 "Over Voltage" 7 "reserved" ;
VAL_ 624 PCM_Blwr2Fail 0 "Normal" 1 "Circuit Open/Short (internal error, diagnosis/Siganl line open/short)" 2 "Motor Stall" 3 "Over Current" 4 "Over Temperature" 5 "Under Voltage" 6 "Over Voltage" 7 "reserved" ;
VAL_ 624 PCM_MainCtrlSta 0 "Initialization" 1 "Normal" 2 "Abnormal" 3 "reserved" ;
VAL_ 624 PCM_Cart1Sta 0 "Contacted, Normal" 1 "Reserved" 2 "Temporary Failure" 3 "Not-Contacted" ;
VAL_ 624 PCM_Cart2Sta 0 "Contacted, Normal" 1 "Reserved" 2 "Temporary Failure" 3 "Not-Contacted" ;
VAL_ 624 PCM_Cart1Kinds 0 "Default" 1 "THE DRIVER'S AWAKENING" 2 "MY FAVOURITE PLACE" 3 "THE CREAT OUTDOORS" 4 "RESERVED" 5 "RESERVED" 6 "RESERVED" 7 "RESERVED" 8 "RESERVED" 9 "RESERVED" 10 "RESERVED" 11 "RESERVED" 12 "New Frangrance Mounted(Genuine cartidge, Not registered new frangrance)" 13 "No Cartridge Mounted" 14 "Unknown Cartridge Mounted (Not Genuine cartidge)" 15 "Error Indicator" ;
VAL_ 624 PCM_Cart2Kinds 0 "Default" 1 "THE DRIVER'S AWAKENING" 2 "MY FAVOURITE PLACE" 3 "THE CREAT OUTDOORS" 4 "RESERVED" 5 "RESERVED" 6 "RESERVED" 7 "RESERVED" 8 "RESERVED" 9 "RESERVED" 10 "RESERVED" 11 "RESERVED" 12 "New Frangrance Mounted(Genuine cartidge, Not registered new frangrance)" 13 "No Cartridge Mounted" 14 "Unknown Cartridge Mounted (Not Genuine cartidge)" 15 "Error Indicator" ;
VAL_ 624 PCM_ActSta 0 "Normal Stop" 1 "Normal Moving" 2 "Calibration" 3 "Reserved" 4 "Reserved" 5 "Reserved" 6 "Reserved" 7 "Reserved" 8 "Reserved" 9 "Reserved" 10 "Reserved" 11 "Reserved" 12 "Reserved" 13 "Reserved" 14 "Temporary Failure" 15 "Permanent Failure" ;
VAL_ 624 PCM_ActFail 0 "Normal" 1 "Motor Stall" 2 "Motor circuit open/short(Motor Internal error, Over Current)" 3 "Over temperature" 4 "Over/Under Voltage" 5 "LIN Tiemout" 6 "reserved" 7 "reserved" ;
VAL_ 625 PCM_Cart1VectorX 0 "coordinate" 1 "coordinate" 2 "coordinate" 3 "coordinate" 4 "coordinate" 5 "coordinate" 6 "coordinate" 7 "coordinate" 8 "coordinate" 9 "coordinate" 10 "coordinate" 11 "coordinate" 12 "coordinate" 13 "coordinate" 14 "coordinate" 15 "coordinate" 16 "coordinate" 17 "coordinate" 18 "coordinate" 19 "coordinate" 20 "coordinate" 21 "15~0xFD:RESERVED" 253 "15~0xFD:RESERVED" 254 "Cartridge Not Contacted" 255 "Error Indicator" ;
VAL_ 625 PCM_Cart1RmnPer 0 "0x0000~0x03E8:0~100.0%" 1000 "0x0000~0x03E8:0~100.0%" 1001 "03E9~0xFFFE:Reserverd" 65534 "03E9~0xFFFE:Reserverd" 65535 "Error Indicator" ;
VAL_ 625 PCM_Cart1ExpSta 0 "Default" 1 "Normal" 2 "Expired" 3 "Error Indicator" ;
VAL_ 625 PCM_Cart1RmnDisp 0 "Default" 1 "Remains 100% (70~100%)" 2 "Remains 70% (30~70%)" 3 "Remains 30% (1~30%)" 4 "Remains 0%" 5 "Reserved" 6 "Unknown" 7 "Error Indicator" ;
VAL_ 625 PCM_Cart1VectorY 0 "coordinate" 1 "coordinate" 2 "coordinate" 3 "coordinate" 4 "coordinate" 5 "coordinate" 6 "coordinate" 7 "coordinate" 8 "coordinate" 9 "coordinate" 10 "coordinate" 11 "coordinate" 12 "coordinate" 13 "coordinate" 14 "coordinate" 15 "coordinate" 16 "coordinate" 17 "coordinate" 18 "coordinate" 19 "coordinate" 20 "coordinate" 21 "15~0xFD:RESERVED" 253 "15~0xFD:RESERVED" 254 "Cartridge Not Contacted" 255 "Error Indicator" ;
VAL_ 626 PCM_Cart2VectorX 0 "coordinate" 1 "coordinate" 2 "coordinate" 3 "coordinate" 4 "coordinate" 5 "coordinate" 6 "coordinate" 7 "coordinate" 8 "coordinate" 9 "coordinate" 10 "coordinate" 11 "coordinate" 12 "coordinate" 13 "coordinate" 14 "coordinate" 15 "coordinate" 16 "coordinate" 17 "coordinate" 18 "coordinate" 19 "coordinate" 20 "coordinate" 21 "15~0xFD:RESERVED" 253 "15~0xFD:RESERVED" 254 "Cartridge Not Contacted" 255 "Error Indicator" ;
VAL_ 626 PCM_Cart2RmnPer 0 "0x0000~0x03E8:0~100.0%" 1000 "0x0000~0x03E8:0~100.0%" 1001 "03E9~0xFFFE:Reserverd" 65534 "03E9~0xFFFE:Reserverd" 65535 "Error Indicator" ;
VAL_ 626 PCM_Cart2ExpSta 0 "Default" 1 "Normal" 2 "Expired" 3 "Error Indicator" ;
VAL_ 626 PCM_Cart2RmnDisp 0 "Default" 1 "Remains 100% (70~100%)" 2 "Remains 70% (30~70%)" 3 "Remains 30% (1~30%)" 4 "Remains 0%" 5 "Reserved" 6 "Unknown" 7 "Error Indicator" ;
VAL_ 626 PCM_Cart2VectorY 0 "coordinate" 1 "coordinate" 2 "coordinate" 3 "coordinate" 4 "coordinate" 5 "coordinate" 6 "coordinate" 7 "coordinate" 8 "coordinate" 9 "coordinate" 10 "coordinate" 11 "coordinate" 12 "coordinate" 13 "coordinate" 14 "coordinate" 15 "coordinate" 16 "coordinate" 17 "coordinate" 18 "coordinate" 19 "coordinate" 20 "coordinate" 21 "15~0xFD:RESERVED" 253 "15~0xFD:RESERVED" 254 "Cartridge Not Contacted" 255 "Error Indicator" ;
VAL_ 336 RHPTC_Zone1RdySta 0 "Not Ready(Disable to control)" 1 "Ready (Enable to Control)" ;
VAL_ 336 RHPTC_Zone1OpSta 0 "Stop Mode" 1 "Operation Mode" 2 "Failure Mode" 3 "Limited operation Mode" ;
VAL_ 336 RHPTC_Zone1CnsmptPwr_W 0 "0x0~0x2710:Power" 10000 "0x0~0x2710:Power" 65535 "ERROR" ;
VAL_ 336 RHPTC_Zone1Voltage_V 0 "0x0~0xFA:Voltage" 250 "0x0~0xFA:Voltage" 251 "RESERVED" 252 "RESERVED" 253 "RESERVED" 254 "RESERVED" 255 "ERROR" ;
VAL_ 336 RHPTC_Zone1CtrlTyp 0 "Single PTC & Single Control" 1 "Dual PTC & Single Control" 2 "Dual PTC & Dual Control" 3 "RESERVED" 4 "RESERVED" 5 "RESERVED" 6 "RESERVED" 7 "RESERVED" ;
VAL_ 336 RHPTC_Zone1Current_A 0 "0x0~0xFA:Current" 250 "0x0~0xFA:Current" 251 "RESERVED" 252 "RESERVED" 253 "RESERVED" 254 "RESERVED" 255 "ERROR" ;
VAL_ 336 RHPTC_Zone1DutyFB_Pec 0 "0x0~0xC8:Duty" 200 "0x0~0xC8:Duty" 201 "resreved" 202 "resreved" 203 "resreved" 204 "resreved" 205 "resreved" 206 "resreved" 207 "resreved" 208 "resreved" 209 "resreved" 210 "resreved" 211 "resreved" 212 "resreved" 213 "resreved" 214 "resreved" 215 "resreved" 216 "resreved" 217 "resreved" 218 "resreved" 219 "resreved" 220 "resreved" 221 "resreved" 222 "resreved" 223 "resreved" 224 "resreved" 225 "resreved" 226 "resreved" 227 "resreved" 228 "resreved" 229 "resreved" 230 "resreved" 231 "resreved" 232 "resreved" 233 "resreved" 234 "resreved" 235 "resreved" 236 "resreved" 237 "resreved" 238 "resreved" 239 "resreved" 240 "resreved" 241 "resreved" 242 "resreved" 243 "resreved" 244 "resreved" 245 "resreved" 246 "resreved" 247 "resreved" 248 "resreved" 249 "resreved" 250 "resreved" 251 "resreved" 252 "resreved" 253 "resreved" 254 "resreved" 255 "ERROR" ;
VAL_ 336 RHPTC_Zone1DutyFB_IGBT 0 "0x0~0xC8:Duty" 200 "0x0~0xC8:Duty" 201 "RESERVED" 202 "RESERVED" 203 "RESERVED" 204 "RESERVED" 205 "RESERVED" 206 "RESERVED" 207 "RESERVED" 208 "RESERVED" 209 "RESERVED" 210 "RESERVED" 211 "RESERVED" 212 "RESERVED" 213 "RESERVED" 214 "RESERVED" 215 "RESERVED" 216 "RESERVED" 217 "RESERVED" 218 "RESERVED" 219 "RESERVED" 220 "RESERVED" 221 "RESERVED" 222 "RESERVED" 223 "RESERVED" 224 "RESERVED" 225 "RESERVED" 226 "RESERVED" 227 "RESERVED" 228 "RESERVED" 229 "RESERVED" 230 "RESERVED" 231 "RESERVED" 232 "RESERVED" 233 "RESERVED" 234 "RESERVED" 235 "RESERVED" 236 "RESERVED" 237 "RESERVED" 238 "RESERVED" 239 "RESERVED" 240 "RESERVED" 241 "RESERVED" 242 "RESERVED" 243 "RESERVED" 244 "RESERVED" 245 "RESERVED" 246 "RESERVED" 247 "RESERVED" 248 "RESERVED" 249 "RESERVED" 250 "RESERVED" 251 "RESERVED" 252 "RESERVED" 253 "RESERVED" 254 "RESERVED" 255 "ERROR" ;
VAL_ 336 RHPTC_Zone1CoreTemp_C 0 "Temperature" 1 "Temperature" 2 "Temperature" 3 "Temperature" 4 "Temperature" 5 "Temperature" 6 "Temperature" 7 "Temperature" 8 "Temperature" 9 "Temperature" 10 "Temperature" 11 "Temperature" 12 "Temperature" 13 "Temperature" 14 "Temperature" 15 "Temperature" 241 "RESERVED" 242 "RESERVED" 243 "RESERVED" 244 "RESERVED" 245 "RESERVED" 246 "RESERVED" 247 "RESERVED" 248 "RESERVED" 249 "RESERVED" 250 "RESERVED" 251 "RESERVED" 252 "RESERVED" 253 "The thermister is open" 254 "The thermister is short" 255 "Error" ;
